VERSION ""

NS_ :

BS_:

BU_: IHU

BO_ 1050 AVM_3: 8 Vector__XXX
 SG_ HPA_Subscribe_Status : 63|3@0+ (1,0) [0|7] ""  IHU
 SG_ HPA_IHU_Audio_HPA_status : 60|1@0+ (1,0) [0|1] ""  IHU
 SG_ FaultStatusCameraDVR : 59|2@0+ (1,0) [0|2] ""  IHU
 SG_ REQ_AVMDisp_1 : 57|2@0+ (1,0) [0|3] ""  IHU
 SG_ PDC_fault_status : 55|1@0+ (1,0) [0|1] ""  IHU
 SG_ APA_fault_status : 54|2@0+ (1,0) [0|3] ""  IHU
 SG_ FAPASet_Feedback : 52|1@0+ (1,0) [0|1] ""  IHU
 SG_ HPASubStsFeedback : 51|1@0+ (1,0) [0|1] ""  IHU
 SG_ UndoSet_Feedback : 49|1@0+ (1,0) [0|1] ""  IHU
 SG_ Undo_fault_status : 48|1@0+ (1,0) [0|1] ""  IHU
 SG_ PDCmute_Set_Feedback : 43|1@0+ (1,0) [0|1] ""  IHU
 SG_ MOD_WorkSts : 42|2@0+ (1,0) [0|3] ""  IHU
 SG_ STAT_BSV_status : 40|1@0+ (1,0) [0|1] ""  IHU
 SG_ HPAMode : 47|3@0+ (1,0) [0|7] ""  IHU
 SG_ HPAActive : 44|1@0+ (1,0) [0|1] ""  IHU
 SG_ HPA_IHU_Audio_Park_Tips_1 : 39|4@0+ (1,0) [0|15] ""  IHU
 SG_ HPA_IHU_Audio_Learn_Tips_1 : 35|4@0+ (1,0) [0|15] ""  IHU
 SG_ HPA_IHU_Audio_Park_Tips : 31|4@0+ (1,0) [0|15] ""  IHU
 SG_ HPA_IHU_Audio_Learn_Tips : 27|4@0+ (1,0) [0|15] ""  IHU
 SG_ HPA_Exam_status : 21|2@0+ (1,0) [0|3] ""  IHU
 SG_ REQ_BSVDisp : 19|2@0+ (1,0) [0|3] ""  IHU
 SG_ MEBSet_Feedback : 8|1@0+ (1,0) [0|1] ""  IHU
 SG_ AVM_FactoryMode : 23|1@0+ (1,0) [0|1] ""  IHU
 SG_ AVMFeedbackSts_RemoteMode : 22|1@0+ (1,0) [0|1] ""  IHU
 SG_ AVM_3_IHUTTSExtend : 15|4@0+ (1,0) [0|15] ""  IHU
 SG_ AVM_3_IHUTTS : 5|5@0+ (1,0) [0|31] ""  IHU
 SG_ AVMDisplaySts : 0|1@0+ (1,0) [0|1] ""  IHU

BO_ 1267 AIPM_2: 8 Vector__XXX
 SG_ AIPM_2_DriveModeSet : 35|2@0+ (1,0) [0|3] ""  IHU

BO_ 1265 AIPM_1: 8 Vector__XXX
 SG_ PanelKeyVoiceRemindReq : 8|1@0+ (1,0) [0|1] ""  IHU

BO_ 704 ABS_ESP_G: 7 Vector__XXX
 SG_ CDPFailSts : 46|1@0+ (1,0) [0|1] ""  IHU
 SG_ AVHFailSts : 45|1@0+ (1,0) [0|1] ""  IHU
 SG_ AVHSts : 44|2@0+ (1,0) [0|3] ""  IHU
 SG_ HDCFailSts : 42|1@0+ (1,0) [0|1] ""  IHU
 SG_ DiagnosticSessionSts : 47|1@0+ (1,0) [0|1] ""  IHU
 SG_ CDPActive : 13|1@0+ (1,0) [0|1] ""  IHU
 SG_ HHCFailSts : 15|1@0+ (1,0) [0|1] ""  IHU
 SG_ VDCActive : 0|1@0+ (1,0) [0|1] ""  IHU
 SG_ TCSActive : 1|1@0+ (1,0) [0|1] ""  IHU
 SG_ VDCFailSts : 2|1@0+ (1,0) [0|1] ""  IHU
 SG_ TCSFailSts : 3|1@0+ (1,0) [0|1] ""  IHU
 SG_ EBDFailSts : 4|1@0+ (1,0) [0|1] ""  IHU
 SG_ ABSFailSts : 5|1@0+ (1,0) [0|1] ""  IHU
 SG_ AVHWarningMessage : 7|1@0+ (1,0) [0|1] ""  IHU
 SG_ ABS_ESP_Checksum : 55|8@0+ (1,0) [0|255] ""  IHU
 SG_ HDCCtrlSts : 41|2@0+ (1,0) [0|3] ""  IHU
 SG_ ABS_ESP_MessageCounter : 35|4@0+ (1,0) [0|15] ""  IHU
 SG_ VehicleSpeedVSOSigValidData : 31|1@0+ (1,0) [0|1] ""  IHU
 SG_ VehicleSpeedVSOSig : 12|13@0+ (0.0625,0) [0|511.875] "km/h"  IHU
 SG_ ESPSwitchStatus : 14|1@0+ (1,0) [0|1] ""  IHU

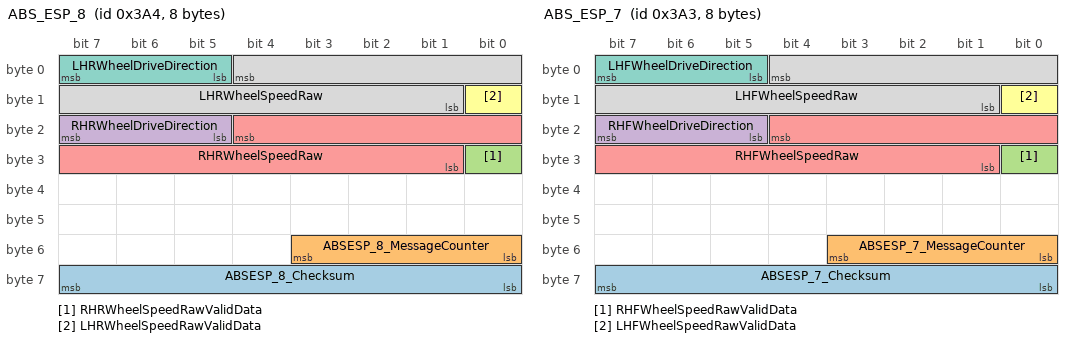
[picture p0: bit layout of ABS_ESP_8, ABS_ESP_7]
BO_ 932 ABS_ESP_8: 8 Vector__XXX
 SG_ ABSESP_8_Checksum : 63|8@0+ (1,0) [0|255] ""  IHU
 SG_ ABSESP_8_MessageCounter : 51|4@0+ (1,0) [0|15] ""  IHU
 SG_ RHRWheelSpeedRawValidData : 24|1@0+ (1,0) [0|1] ""  IHU
 SG_ RHRWheelDriveDirection : 23|3@0+ (1,0) [0|7] ""  IHU
 SG_ RHRWheelSpeedRaw : 20|12@0+ (0.05,-30) [-30|80] "m/s"  IHU
 SG_ LHRWheelSpeedRawValidData : 8|1@0+ (1,0) [0|1] ""  IHU
 SG_ LHRWheelDriveDirection : 7|3@0+ (1,0) [0|7] ""  IHU
 SG_ LHRWheelSpeedRaw : 4|12@0+ (0.05,-30) [-30|80] "m/s"  IHU

BO_ 931 ABS_ESP_7: 8 Vector__XXX
 SG_ ABSESP_7_Checksum : 63|8@0+ (1,0) [0|255] ""  IHU
 SG_ ABSESP_7_MessageCounter : 51|4@0+ (1,0) [0|15] ""  IHU
 SG_ RHFWheelSpeedRawValidData : 24|1@0+ (1,0) [0|1] ""  IHU
 SG_ RHFWheelDriveDirection : 23|3@0+ (1,0) [0|7] ""  IHU
 SG_ RHFWheelSpeedRaw : 20|12@0+ (0.05,-30) [-30|80] "m/s"  IHU
 SG_ LHFWheelSpeedRawValidData : 8|1@0+ (1,0) [0|1] ""  IHU
 SG_ LHFWheelDriveDirection : 7|3@0+ (1,0) [0|7] ""  IHU
 SG_ LHFWheelSpeedRaw : 4|12@0+ (0.05,-30) [-30|80] "m/s"  IHU

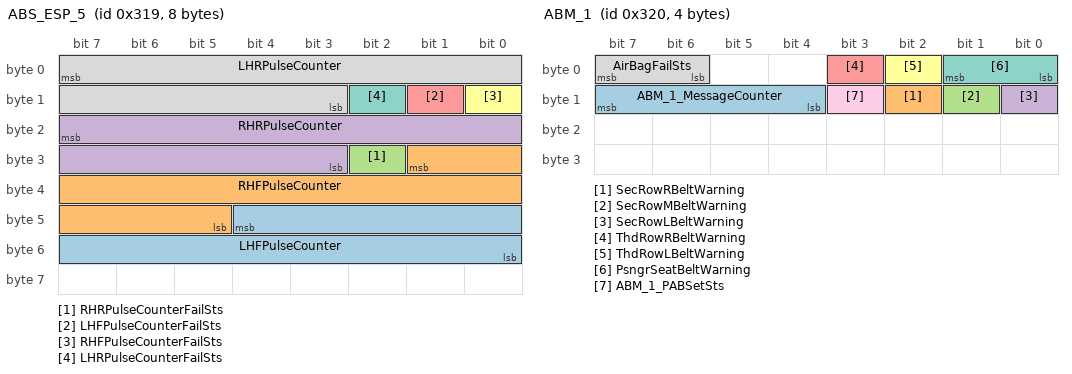
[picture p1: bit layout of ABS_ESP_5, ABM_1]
BO_ 793 ABS_ESP_5: 8 Vector__XXX
 SG_ LHFPulseCounter : 44|13@0+ (1,0) [0|8191] "pulse"  IHU
 SG_ RHFPulseCounter : 25|13@0+ (1,0) [0|8191] "pulse"  IHU
 SG_ RHRPulseCounterFailSts : 26|1@0+ (1,0) [0|1] ""  IHU
 SG_ RHRPulseCounter : 23|13@0+ (1,0) [0|8191] "pulse"  IHU
 SG_ LHFPulseCounterFailSts : 9|1@0+ (1,0) [0|1] ""  IHU
 SG_ RHFPulseCounterFailSts : 8|1@0+ (1,0) [0|1] ""  IHU
 SG_ LHRPulseCounterFailSts : 10|1@0+ (1,0) [0|1] ""  IHU
 SG_ LHRPulseCounter : 7|13@0+ (1,0) [0|8191] "pulse"  IHU

BO_ 787 ABS_ESP_3: 8 Vector__XXX
 SG_ ABS_ESP_3_AVHSts : 53|2@0+ (1,0) [0|3] ""  IHU
 SG_ ABS_ESP_3_AVHFailSts : 39|1@0+ (1,0) [0|1] ""  IHU

BO_ 800 ABM_1: 4 Vector__XXX
 SG_ ABM_1_MessageCounter : 15|4@0+ (1,0) [0|15] "" Vector__XXX
 SG_ SecRowRBeltWarning : 10|1@0+ (1,0) [0|1] "" Vector__XXX
 SG_ SecRowMBeltWarning : 9|1@0+ (1,0) [0|1] ""  IHU
 SG_ SecRowLBeltWarning : 8|1@0+ (1,0) [0|1] "" Vector__XXX
 SG_ ThdRowRBeltWarning : 3|1@0+ (1,0) [0|1] "" Vector__XXX
 SG_ ThdRowLBeltWarning : 2|1@0+ (1,0) [0|1] ""  IHU
 SG_ PsngrSeatBeltWarning : 1|2@0+ (1,0) [0|3] "" Vector__XXX
 SG_ AirBagFailSts : 7|2@0+ (1,0) [0|3] "" Vector__XXX
 SG_ ABM_1_PABSetSts : 11|1@0+ (1,0) [0|1] ""  IHU

BO_ 1338 CGW_TMF: 8 Vector__XXX
 SG_ TMF_SpdAct : 55|16@0+ (1,-32767) [-32767|32766] "rpm"  IHU

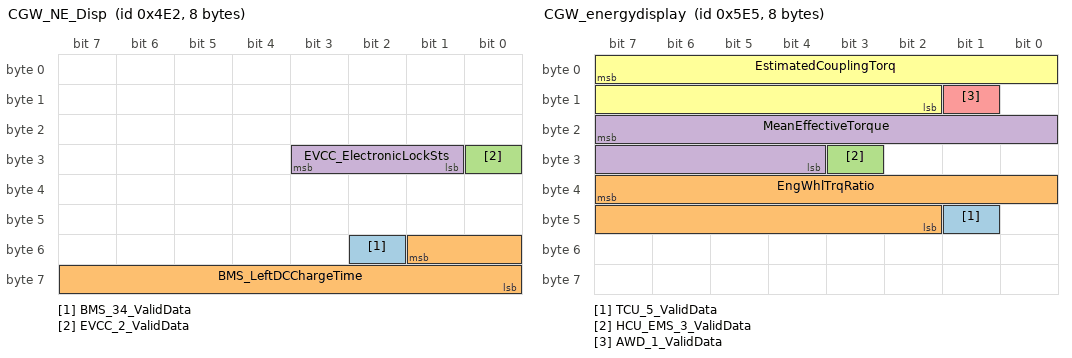
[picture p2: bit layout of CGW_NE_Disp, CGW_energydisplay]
BO_ 1250 CGW_NE_Disp: 8 Vector__XXX
 SG_ BMS_34_ValidData : 50|1@0+ (1,0) [0|1] ""  IHU
 SG_ BMS_LeftDCChargeTime : 49|10@0+ (1,0) [0|1022] "min"  IHU
 SG_ EVCC_2_ValidData : 24|1@0+ (1,0) [0|1] ""  IHU
 SG_ EVCC_ElectronicLockSts : 27|3@0+ (1,0) [0|4] ""  IHU

BO_ 1509 CGW_energydisplay: 8 Vector__XXX
 SG_ TCU_5_ValidData : 41|1@0+ (1,0) [0|1] ""  IHU
 SG_ EngWhlTrqRatio : 39|14@0+ (0.01,0) [0|163.82] ""  IHU
 SG_ HCU_EMS_3_ValidData : 27|1@0+ (1,0) [0|1] ""  IHU
 SG_ MeanEffectiveTorque : 23|12@0+ (0.5,-1000) [-1000|1000] "NM"  IHU
 SG_ AWD_1_ValidData : 9|1@0+ (1,0) [0|1] ""  IHU
 SG_ EstimatedCouplingTorq : 7|14@0+ (0.25,0) [0|3000] "Nm"  IHU

BO_ 1812 DMC_BCM_RLS_RES: 8 Vector__XXX
 SG_ DMC_BCM_RLS_RES : 7|64@0+ (1,0) [0|0] ""  IHU

BO_ 1796 DMC_BCM_RLS_REQ: 8 IHU
 SG_ DMC_BCM_RLS_REQ : 7|64@0+ (1,0) [0|0] "" Vector__XXX

BO_ 1882 TBOX_IHU_RES: 8 IHU
 SG_ TBOX_IHU_RES : 7|64@0+ (1,0) [0|0] "" Vector__XXX

BO_ 1866 TBOX_IHU_REQ: 8 Vector__XXX
 SG_ TBOX_IHU_REQ : 7|64@0+ (1,0) [0|0] ""  IHU

BO_ 1913 DMC_BCM_EBS_RES: 8 Vector__XXX
 SG_ DMC_BCM_EBS_RES : 7|64@0+ (1,0) [0|0] ""  IHU

BO_ 2041 DMC_ACU_RES_EDR: 8 Vector__XXX
 SG_ DMC_ACU_RES_EDR : 7|64@0+ (1,0) [0|0] ""  IHU

BO_ 2030 DMC_DCDC_RES: 8 Vector__XXX
 SG_ DMC_DCDC_RES : 7|64@0+ (1,0) [0|0] ""  IHU

BO_ 2029 DMC_BMS_RES: 8 Vector__XXX
 SG_ DMC_BMS_RES : 7|64@0+ (1,0) [0|0] ""  IHU

BO_ 1813 DMC_EVCC_RES: 8 Vector__XXX
 SG_ DMC_EVCC_RES : 7|64@0+ (1,0) [0|0] ""  IHU

BO_ 1819 DMC_ISGF_RES: 8 Vector__XXX
 SG_ DMC_ISGF_RES : 7|64@0+ (1,0) [0|0] ""  IHU

BO_ 2027 DMC_BSGF_MCUF_RES: 8 Vector__XXX
 SG_ DMC_BSG1_RES : 7|64@0+ (1,0) [0|0] ""  IHU

BO_ 2025 DMC_OBD_RES_TCU: 8 Vector__XXX
 SG_ DMC_OBD_RESP_TCU : 7|64@0+ (1,0) [0|0] ""  IHU

BO_ 2024 DMC_OBD_EMS_RES: 8 Vector__XXX
 SG_ DMC_OBD_EMS_RES : 7|64@0+ (1,0) [0|0] ""  IHU

BO_ 2014 DMC_SHU3L_RES: 8 Vector__XXX
 SG_ DMC_SHU3L_RES : 7|64@0+ (1,0) [0|0] ""  IHU

BO_ 2009 DMC_SHU2R_RES: 8 Vector__XXX
 SG_ DMC_SHU2R_RES : 7|64@0+ (1,0) [0|0] ""  IHU

BO_ 2008 DMC_SHU2M_RES: 8 Vector__XXX
 SG_ DMC_SHU2M_RES : 7|64@0+ (1,0) [0|0] ""  IHU

BO_ 2007 DMC_SHU2L_RES: 8 Vector__XXX
 SG_ DMC_SHU2L_RES : 7|64@0+ (1,0) [0|0] ""  IHU

BO_ 2006 DMC_SHU3R_RES: 8 Vector__XXX
 SG_ DMC_SHU3R_RES : 7|64@0+ (1,0) [0|0] ""  IHU

BO_ 1982 DMC_SRFR_RES: 8 Vector__XXX
 SG_ DMC_SRFR_RES : 7|64@0+ (1,0) [0|0] ""  IHU

BO_ 1981 DMC_SRFG_RES: 8 Vector__XXX
 SG_ DMC_SRFG_RES : 7|64@0+ (1,0) [0|0] ""  IHU

BO_ 1980 DMC_SAUR_RES: 8 Vector__XXX
 SG_ DMC_SAUR_RES : 7|64@0+ (1,0) [0|0] ""  IHU

BO_ 1979 DMC_RRPLM_RES: 8 Vector__XXX
 SG_ DMC_RRPLM_RES : 7|64@0+ (1,0) [0|0] ""  IHU

BO_ 1978 DMC_RRFLM_RES: 8 Vector__XXX
 SG_ DMC_RRFLM_RES : 7|64@0+ (1,0) [0|0] ""  IHU

BO_ 1977 DMC_RLPLM_RES: 8 Vector__XXX
 SG_ DMC_RLPLM_RES : 7|64@0+ (1,0) [0|0] ""  IHU

BO_ 1976 DMC_RLFLM_RES: 8 Vector__XXX
 SG_ DMC_RLFLM_RES : 7|64@0+ (1,0) [0|0] ""  IHU

BO_ 1975 DMC_SAUP_RES: 8 Vector__XXX
 SG_ DMC_SAUP_RES : 7|64@0+ (1,0) [0|0] ""  IHU

BO_ 1974 DMC_SHU1P_RES: 8 Vector__XXX
 SG_ DMC_SHU1P_RES : 7|64@0+ (1,0) [0|0] ""  IHU

BO_ 1951 DMC_SAUD_RES: 8 Vector__XXX
 SG_ DMC_SAUD_RES : 7|64@0+ (1,0) [0|0] ""  IHU

BO_ 1949 DMC_NFC_RES: 8 Vector__XXX
 SG_ DMC_NFC_RES : 7|64@0+ (1,0) [0|0] ""  IHU

BO_ 1946 DMC_AIPMR_RES: 8 Vector__XXX
 SG_ DMC__AIPMR_RES : 7|64@0+ (1,0) [0|0] ""  IHU

BO_ 1945 DMC_AIPM_RES: 8 Vector__XXX
 SG_ DMC__AIPM_RES : 7|64@0+ (1,0) [0|0] ""  IHU

BO_ 1938 DMC_SHU1D_RES: 8 Vector__XXX
 SG_ DMC_SHU1D_RES : 7|64@0+ (1,0) [0|0] ""  IHU

BO_ 1936 DMC_SCU_RES: 8 Vector__XXX
 SG_ DMC_SCU_RES : 7|64@0+ (1,0) [0|0] ""  IHU

BO_ 1919 DMC_RHM_RES: 8 Vector__XXX
 SG_ DMC_RHM_RES : 7|64@0+ (1,0) [0|0] ""  IHU

BO_ 1918 DMC_LHM_RES: 8 Vector__XXX
 SG_ DMC_LHM_RES : 7|64@0+ (1,0) [0|0] ""  IHU

BO_ 1917 DMC_ESCL_RES: 8 Vector__XXX
 SG_ DMC_ESCL_RES : 7|64@0+ (1,0) [0|0] ""  IHU

BO_ 1916 DMC_PLG_RES: 8 Vector__XXX
 SG_ DMC_PLG_RES : 7|64@0+ (1,0) [0|0] ""  IHU

BO_ 1910 DMC_AVM_RES: 8 Vector__XXX
 SG_ DMC_AVM_RES : 7|64@0+ (1,0) [0|0] ""  IHU

BO_ 1907 DMC_RADAR_RES: 8 Vector__XXX
 SG_ DMC_RADAR_RES : 7|64@0+ (1,0) [0|0] ""  IHU

BO_ 1906 DMC_CGW_RES: 8 Vector__XXX
 SG_ DMC_CGW_RES : 7|64@0+ (1,0) [0|0] ""  IHU

BO_ 1904 DMC_BDM_RES: 8 Vector__XXX
 SG_ DMC_BDM_RES : 7|64@0+ (1,0) [0|0] ""  IHU

BO_ 1885 DMC_IMMO_RES: 8 Vector__XXX
 SG_ DMC_IMMO_RES : 7|64@0+ (1,0) [0|0] ""  IHU

BO_ 1883 DMC_CLM_RES: 8 Vector__XXX
 SG_ DMC_CLM_RES : 7|64@0+ (1,0) [0|0] ""  IHU

BO_ 1880 DMC_DBL_RES: 8 Vector__XXX
 SG_ DMC_DBL_RES : 7|64@0+ (1,0) [0|0] ""  IHU

BO_ 1879 DMC_ICM_RES: 8 Vector__XXX
 SG_ DMC_ICM_RES : 7|64@0+ (1,0) [0|0] ""  IHU

BO_ 1878 DMC_ACU_RES: 8 Vector__XXX
 SG_ DMC_ACU_RES : 7|64@0+ (1,0) [0|0] ""  IHU

BO_ 1855 DMC_FRM_RES: 8 Vector__XXX
 SG_ DMC_FRM_RES : 7|64@0+ (1,0) [0|0] ""  IHU

BO_ 1854 DMC_FCM_RES: 8 Vector__XXX
 SG_ DMC_FCM_RES : 7|64@0+ (1,0) [0|0] ""  IHU

BO_ 1851 DMC_EGS_RES: 8 Vector__XXX
 SG_ DMC_EGS_RES : 7|64@0+ (1,0) [0|0] ""  IHU

BO_ 1848 DMC_TPMS_RES: 8 Vector__XXX
 SG_ DMC_TPMS_RES : 7|64@0+ (1,0) [0|0] ""  IHU

BO_ 1844 DMC_EPS_RES: 8 Vector__XXX
 SG_ DMC_EPS_RES : 7|64@0+ (1,0) [0|0] ""  IHU

BO_ 1840 DMC_ESP_RES: 8 Vector__XXX
 SG_ DMC_ESP_RES : 7|64@0+ (1,0) [0|0] ""  IHU

BO_ 1816 DIAG_EPB_RES_CH: 8 Vector__XXX
 SG_ DIAG_EPB_RES : 7|64@0+ (1,0) [0|0] ""  IHU

BO_ 1841 DIAG_EPB_RES_PT: 8 Vector__XXX
 SG_ DIAG_EPB_RES : 7|64@0+ (1,0) [0|0] ""  IHU

BO_ 1823 DMC_GSI_RES: 8 Vector__XXX
 SG_ DMC_GSI_RES : 7|64@0+ (1,0) [0|0] ""  IHU

BO_ 1811 DMC_TCU_RES: 8 Vector__XXX
 SG_ DMC_TCU_RES : 7|64@0+ (1,0) [0|0] ""  IHU

BO_ 1810 DMC_AWD_RES: 8 Vector__XXX
 SG_ DMC_AWD_RES : 7|64@0+ (1,0) [0|0] ""  IHU

BO_ 1809 DMC_FPC_RES: 8 Vector__XXX
 SG_ DMC_FPC_RES : 7|64@0+ (1,0) [0|0] ""  IHU

BO_ 1808 DMC_EMS_RES: 8 Vector__XXX
 SG_ DMC_EMS_RES : 7|64@0+ (1,0) [0|0] ""  IHU

BO_ 2005 DMC_CVBOX_RES: 8 Vector__XXX
 SG_ DMC_CVBOX_RES : 7|64@0+ (1,0) [0|0] ""  IHU

BO_ 1948 DMC_HUD_RES: 8 Vector__XXX
 SG_ DMC_HUD_RES : 7|64@0+ (1,0) [0|0] ""  IHU

BO_ 1874 DMC_DCM_RES: 8 Vector__XXX
 SG_ DMC_DCM_RES : 7|64@0+ (1,0) [0|0] ""  IHU

BO_ 1843 DMC_PPMI_RES: 8 Vector__XXX
 SG_ DMC_PPMI_RES : 7|64@0+ (1,0) [0|0] ""  IHU

BO_ 1905 DMC_SAM_RES: 8 Vector__XXX
 SG_ DMC_SAM_RES : 7|64@0+ (1,0) [0|0] ""  IHU

BO_ 2028 DMC_MCUR_RES: 8 Vector__XXX
 SG_ DMC_MCUR_RES : 7|64@0+ (1,0) [0|0] ""  IHU

BO_ 2026 DMC_HCU_RES: 8 Vector__XXX
 SG_ DMC_HCU_RES : 7|64@0+ (1,0) [0|0] ""  IHU

BO_ 1847 DMC_ASU_RES: 8 Vector__XXX
 SG_ DMC_ASU_RES : 7|64@0+ (1,0) [0|0] ""  IHU

BO_ 2004 DMC_RRCR_RES: 8 Vector__XXX
 SG_ DMC_RRCR_RES : 7|64@0+ (1,0) [0|0] ""  IHU

BO_ 2003 DMC_RLCR_RES: 8 Vector__XXX
 SG_ DMC_RLCR_RES : 7|64@0+ (1,0) [0|0] ""  IHU

BO_ 2002 DMC_FRCR_RES: 8 Vector__XXX
 SG_ DMC_FRCR_RES : 7|64@0+ (1,0) [0|0] ""  IHU

BO_ 2001 DMC_FLCR_RES: 8 Vector__XXX
 SG_ DMC_FLCR_RES : 7|64@0+ (1,0) [0|0] ""  IHU

BO_ 2000 DMC_IDCU_RES: 8 Vector__XXX
 SG_ DMC_IDCU_RES : 7|64@0+ (1,0) [0|0] ""  IHU

BO_ 1983 DMC_CIR_RES: 8 Vector__XXX
 SG_ DMC_CIR_RES : 7|64@0+ (1,0) [0|0] ""  IHU

BO_ 1897 DMC_BCM_EBS_REQ: 8 IHU
 SG_ DMC_BCM_EBS_REQ : 7|64@0+ (1,0) [0|0] "" Vector__XXX

BO_ 1999 DMC_REQ_Broadcast: 8 IHU
 SG_ DMC_REQ_Broadcast : 7|64@0+ (1,0) [0|0] "" Vector__XXX

BO_ 2033 DMC_ACU_REQ_EDR: 8 IHU
 SG_ DMC_ACU_REQ_EDR : 7|64@0+ (1,0) [0|0] "" Vector__XXX

BO_ 1797 DMC_EVCC_REQ: 8 IHU
 SG_ DMC_OBD_REQ_EVCC : 7|64@0+ (1,0) [0|0] "" Vector__XXX

BO_ 1803 DMC_ISGF_REQ: 8 IHU
 SG_ DMC_ISGF_REQ : 7|64@0+ (1,0) [0|0] "" Vector__XXX

BO_ 2019 DMC_BSGF_MCUF_REQ: 8 IHU
 SG_ DMC_BSG1_REQ : 7|64@0+ (1,0) [0|0] "" Vector__XXX

BO_ 2017 DMC_OBD_REQ_TCU: 8 IHU
 SG_ DMC_OBD_REQ_TCU : 7|64@0+ (1,0) [0|0] "" Vector__XXX

BO_ 2016 DMC_OBD_EMS_REQ: 8 IHU
 SG_ DMC_OBD_EMS_REQ : 7|64@0+ (1,0) [0|0] "" Vector__XXX

BO_ 1998 DMC_SHU3L_REQ: 8 IHU
 SG_ DMC_SHU3L_REQ : 7|64@0+ (1,0) [0|0] "" Vector__XXX

BO_ 1993 DMC_SHU2R_REQ: 8 IHU
 SG_ DMC_SHU2R_REQ : 7|64@0+ (1,0) [0|0] "" Vector__XXX

BO_ 1992 DMC_SHU2M_REQ: 8 IHU
 SG_ DMC_SHU2M_REQ : 7|64@0+ (1,0) [0|0] "" Vector__XXX

BO_ 1991 DMC_SHU2L_REQ: 8 IHU
 SG_ DMC_SHU2L_REQ : 7|64@0+ (1,0) [0|0] "" Vector__XXX

BO_ 1990 DMC_SHU3R_REQ: 8 IHU
 SG_ DMC_SHU3R_REQ : 7|64@0+ (1,0) [0|0] "" Vector__XXX

BO_ 1966 DMC_SRFR_REQ: 8 IHU
 SG_ DMC_SRFR_REQ : 7|64@0+ (1,0) [0|0] "" Vector__XXX

BO_ 1965 DMC_SRFG_REQ: 8 IHU
 SG_ DMC_SRFG_REQ : 7|64@0+ (1,0) [0|0] "" Vector__XXX

BO_ 1964 DMC_SAUR_REQ: 8 IHU
 SG_ DMC_SAUR_REQ : 7|64@0+ (1,0) [0|0] "" Vector__XXX

BO_ 1963 DMC_RRPLM_REQ: 8 IHU
 SG_ DMC_RRPLM_REQ : 7|64@0+ (1,0) [0|0] "" Vector__XXX

BO_ 1962 DMC_RRFLM_REQ: 8 IHU
 SG_ DMC_RRFLM_REQ : 7|64@0+ (1,0) [0|0] "" Vector__XXX

BO_ 1961 DMC_RLPLM_REQ: 8 IHU
 SG_ DMC_RLPLM_REQ : 7|64@0+ (1,0) [0|0] "" Vector__XXX

BO_ 1960 DMC_RLFLM_REQ: 8 IHU
 SG_ DMC_RLFLM_REQ : 7|64@0+ (1,0) [0|0] "" Vector__XXX

BO_ 1959 DMC_SAUP_REQ: 8 IHU
 SG_ DMC_SAUP_REQ : 7|64@0+ (1,0) [0|0] "" Vector__XXX

BO_ 1958 DMC_SHU1P_REQ: 8 IHU
 SG_ DMC_SHU1P_REQ : 7|64@0+ (1,0) [0|0] "" Vector__XXX

BO_ 1943 DMC_EAMP_RES: 8 Vector__XXX
 SG_ DMC_EAMP_RES : 7|64@0+ (1,0) [0|0] ""  IHU

BO_ 1942 DMC_ACP_RES: 8 Vector__XXX
 SG_ DMC__ACP_RES : 7|64@0+ (1,0) [0|0] ""  IHU

BO_ 1941 DMC_DVR_RES: 8 Vector__XXX
 SG_ DMC_DVR_RES : 7|64@0+ (1,0) [0|0] ""  IHU

BO_ 1939 DMC_CWC_RES: 8 Vector__XXX
 SG_ DMC_CWC_RES : 7|64@0+ (1,0) [0|0] ""  IHU

BO_ 1935 DMC_SAUD_REQ: 8 IHU
 SG_ DMC_SAUD_REQ : 7|64@0+ (1,0) [0|0] "" Vector__XXX

BO_ 1933 DMC_NFC_REQ: 8 IHU
 SG_ DMC_NFC_REQ : 7|64@0+ (1,0) [0|0] "" Vector__XXX

BO_ 1930 DMC_AIPMR_REQ: 8 IHU
 SG_ DMC_AIPMR_REQ : 7|64@0+ (1,0) [0|0] "" Vector__XXX

BO_ 1929 DMC_AIPM_REQ: 8 IHU
 SG_ DMC_AIPM_REQ : 7|64@0+ (1,0) [0|0] "" Vector__XXX

BO_ 1927 DMC_EAMP_REQ: 8 IHU
 SG_ DMC_EAMP_REQ : 7|64@0+ (1,0) [0|0] "" Vector__XXX

BO_ 1926 DMC_ACP_REQ: 8 IHU
 SG_ DMC__ACP_REQ : 7|64@0+ (1,0) [0|0] "" Vector__XXX

BO_ 1925 DMC_DVR_REQ: 8 IHU
 SG_ DMC_DVR_REQ : 7|64@0+ (1,0) [0|0] "" Vector__XXX

BO_ 1923 DMC_CWC_REQ: 8 IHU
 SG_ DMC_CWC_REQ : 7|64@0+ (1,0) [0|0] "" Vector__XXX

BO_ 1922 DMC_SHU1D_REQ: 8 IHU
 SG_ DMC_SHU1D_REQ : 7|64@0+ (1,0) [0|0] "" Vector__XXX

BO_ 1920 DMC_SCU_REQ: 8 IHU
 SG_ DMC_SCU_REQ : 7|64@0+ (1,0) [0|0] "" Vector__XXX

BO_ 1903 DMC_RHM_REQ: 8 IHU
 SG_ DMC_RHM_REQ : 7|64@0+ (1,0) [0|0] "" Vector__XXX

BO_ 1902 DMC_LHM_REQ: 8 IHU
 SG_ DMC_LHM_REQ : 7|64@0+ (1,0) [0|0] "" Vector__XXX

BO_ 1901 DMC_ESCL_REQ: 8 IHU
 SG_ DMC_ESCL_REQ : 7|64@0+ (1,0) [0|0] "" Vector__XXX

BO_ 1900 DMC_PLG_REQ: 8 IHU
 SG_ DMC_PLG_REQ : 7|64@0+ (1,0) [0|0] "" Vector__XXX

BO_ 1894 DMC_AVM_REQ: 8 IHU
 SG_ DMC_AVM_REQ : 7|64@0+ (1,0) [0|0] "" Vector__XXX

BO_ 1891 DMC_RADAR_REQ: 8 IHU
 SG_ DMC_RADAR_REQ : 7|64@0+ (1,0) [0|0] "" Vector__XXX

BO_ 1890 DMC_CGW_REQ: 8 IHU
 SG_ DMC_CGW_REQ : 7|64@0+ (1,0) [0|0] "" Vector__XXX

BO_ 1888 DMC_BDM_REQ: 8 IHU
 SG_ DMC_BDM_REQ : 7|64@0+ (1,0) [0|0] "" Vector__XXX

BO_ 1869 DMC_IMMO_REQ: 8 IHU
 SG_ DMC_IMMO_REQ : 7|64@0+ (1,0) [0|0] "" Vector__XXX

BO_ 1867 DMC_CLM_REQ: 8 IHU
 SG_ DMC_CLM_REQ : 7|64@0+ (1,0) [0|0] "" Vector__XXX

BO_ 1864 DMC_DBL_REQ: 8 IHU
 SG_ DMC_DBL_REQ : 7|64@0+ (1,0) [0|0] "" Vector__XXX

BO_ 1863 DMC_ICM_REQ: 8 IHU
 SG_ DMC_ICM_REQ : 7|64@0+ (1,0) [0|0] "" Vector__XXX

BO_ 1862 DMC_ACU_REQ: 8 IHU
 SG_ DMC_ACU_REQ : 7|64@0+ (1,0) [0|0] "" Vector__XXX

BO_ 1839 DMC_FRM_REQ: 8 IHU
 SG_ DMC_FRM_REQ : 7|64@0+ (1,0) [0|0] "" Vector__XXX

BO_ 1838 DMC_FCM_REQ: 8 IHU
 SG_ DMC_FCM_REQ : 7|64@0+ (1,0) [0|0] "" Vector__XXX

BO_ 1835 DMC_EGS_REQ: 8 IHU
 SG_ DMC_EGS_REQ : 7|64@0+ (1,0) [0|0] "" Vector__XXX

BO_ 1832 DMC_TPMS_REQ: 8 IHU
 SG_ DMC_TPMS_REQ : 7|64@0+ (1,0) [0|0] "" Vector__XXX

BO_ 1828 DMC_EPS_REQ: 8 IHU
 SG_ DMC_EPS_REQ : 7|64@0+ (1,0) [0|0] "" Vector__XXX

BO_ 1824 DMC_ESP_REQ: 8 IHU
 SG_ DMC_ESP_REQ : 7|64@0+ (1,0) [0|0] "" Vector__XXX

BO_ 1800 DIAG_EPB_REQ_CH: 8 IHU
 SG_ DIAG_EPB_REQ : 7|64@0+ (1,0) [0|0] "" Vector__XXX

BO_ 1825 DIAG_EPB_REQ_PT: 8 IHU
 SG_ DIAG_EPB_REQ : 7|64@0+ (1,0) [0|0] "" Vector__XXX

BO_ 1807 DMC_GSI_REQ: 8 IHU
 SG_ DMC_GSI_REQ : 7|64@0+ (1,0) [0|0] "" Vector__XXX

BO_ 1795 DMC_TCU_REQ: 8 IHU
 SG_ DMC_TCU_REQ : 7|64@0+ (1,0) [0|0] "" Vector__XXX

BO_ 1794 DMC_AWD_REQ: 8 IHU
 SG_ DMC_AWD_REQ : 7|64@0+ (1,0) [0|0] "" Vector__XXX

BO_ 1793 DMC_FPC_REQ: 8 IHU
 SG_ DMC_FPC_REQ : 7|64@0+ (1,0) [0|0] "" Vector__XXX

BO_ 1792 DMC_EMS_REQ: 8 IHU
 SG_ DMC_EMS_REQ : 7|64@0+ (1,0) [0|0] "" Vector__XXX

BO_ 1989 DMC_CVBOX_REQ: 8 IHU
 SG_ DMC_CVBOX_REQ : 7|64@0+ (1,0) [0|0] "" Vector__XXX

BO_ 1932 DMC_HUD_REQ: 8 IHU
 SG_ DMC_HUD_REQ : 7|64@0+ (1,0) [0|0] "" Vector__XXX

BO_ 1858 DMC_DCM_REQ: 8 IHU
 SG_ DMC_DCM_REQ : 7|64@0+ (1,0) [0|0] "" Vector__XXX

BO_ 1827 DMC_PPMI_REQ: 8 IHU
 SG_ DMC_PPMI_REQ : 7|64@0+ (1,0) [0|0] "" Vector__XXX

BO_ 1889 DMC_SAM_REQ: 8 IHU
 SG_ DMC_SAM_REQ : 7|64@0+ (1,0) [0|0] "" Vector__XXX

BO_ 2020 DMC_MCUR_REQ: 8 IHU
 SG_ DMC_MCUR_REQ : 7|64@0+ (1,0) [0|0] "" Vector__XXX

BO_ 2022 DMC_DCDC_REQ: 8 IHU
 SG_ DMC_DCDC_REQ : 7|64@0+ (1,0) [0|0] "" Vector__XXX

BO_ 2021 DMC_BMS_REQ: 8 IHU
 SG_ DMC_BMS_REQ : 7|64@0+ (1,0) [0|0] "" Vector__XXX

BO_ 2018 DMC_HCU_REQ: 8 IHU
 SG_ DMC_HCU_REQ : 7|64@0+ (1,0) [0|0] "" Vector__XXX

BO_ 1831 DMC_ASU_REQ: 8 IHU
 SG_ DMC_ASU_REQ : 7|64@0+ (1,0) [0|0] "" Vector__XXX

BO_ 1988 DMC_RRCR_REQ: 8 IHU
 SG_ DMC_RRCR_REQ : 7|64@0+ (1,0) [0|0] "" Vector__XXX

BO_ 1987 DMC_RLCR_REQ: 8 IHU
 SG_ DMC_RLCR_REQ : 7|64@0+ (1,0) [0|0] "" Vector__XXX

BO_ 1986 DMC_FRCR_REQ: 8 IHU
 SG_ DMC_FRCR_REQ : 7|64@0+ (1,0) [0|0] "" Vector__XXX

BO_ 1985 DMC_FLCR_REQ: 8 IHU
 SG_ DMC_FLCR_REQ : 7|64@0+ (1,0) [0|0] "" Vector__XXX

BO_ 1984 DMC_IDCU_REQ: 8 IHU
 SG_ DMC_IDCU_REQ : 7|64@0+ (1,0) [0|0] "" Vector__XXX

BO_ 1967 DMC_CIR_REQ: 8 IHU
 SG_ DMC_CIR_REQ : 7|64@0+ (1,0) [0|0] "" Vector__XXX

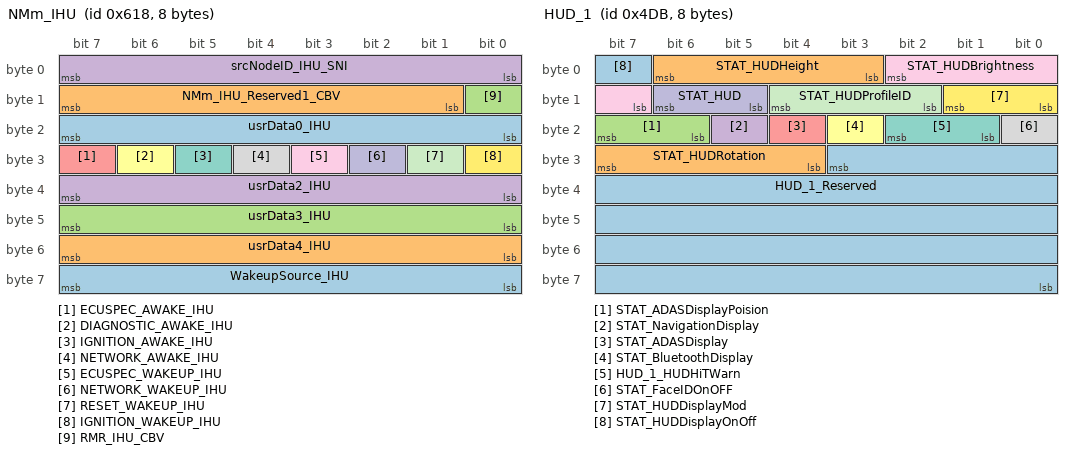
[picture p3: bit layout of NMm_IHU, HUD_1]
BO_ 1560 NMm_IHU: 8 IHU
 SG_ WakeupSource_IHU : 63|8@0+ (1,0) [0|255] "" Vector__XXX
 SG_ usrData4_IHU : 55|8@0+ (1,0) [0|255] "" Vector__XXX
 SG_ usrData3_IHU : 47|8@0+ (1,0) [0|255] "" Vector__XXX
 SG_ usrData2_IHU : 39|8@0+ (1,0) [0|255] "" Vector__XXX
 SG_ ECUSPEC_AWAKE_IHU : 31|1@0+ (1,0) [0|1] "" Vector__XXX
 SG_ DIAGNOSTIC_AWAKE_IHU : 30|1@0+ (1,0) [0|1] "" Vector__XXX
 SG_ IGNITION_AWAKE_IHU : 29|1@0+ (1,0) [0|1] "" Vector__XXX
 SG_ NETWORK_AWAKE_IHU : 28|1@0+ (1,0) [0|1] "" Vector__XXX
 SG_ ECUSPEC_WAKEUP_IHU : 27|1@0+ (1,0) [0|1] "" Vector__XXX
 SG_ NETWORK_WAKEUP_IHU : 26|1@0+ (1,0) [0|1] "" Vector__XXX
 SG_ RESET_WAKEUP_IHU : 25|1@0+ (1,0) [0|1] "" Vector__XXX
 SG_ IGNITION_WAKEUP_IHU : 24|1@0+ (1,0) [0|1] "" Vector__XXX
 SG_ usrData0_IHU : 23|8@0+ (1,0) [0|255] "" Vector__XXX
 SG_ NMm_IHU_Reserved1_CBV : 15|7@0+ (1,0) [0|127] "" Vector__XXX
 SG_ RMR_IHU_CBV : 8|1@0+ (1,0) [0|1] "" Vector__XXX
 SG_ srcNodeID_IHU_SNI : 7|8@0+ (1,0) [0|255] "" Vector__XXX

BO_ 1266 TBOX_2: 8 Vector__XXX
 SG_ TBOX_SetAVMVeiw : 34|3@0+ (1,0) [0|7] ""  IHU
 SG_ TBOX_SetAVMOnReq : 36|2@0+ (1,0) [0|3] ""  IHU

BO_ 1312 TBOX_1: 4 Vector__XXX
 SG_ TBOX_1_RemDiagSts : 23|2@0+ (1,0) [0|3] ""  IHU

BO_ 1243 HUD_1: 8 Vector__XXX
 SG_ HUD_1_Reserved : 27|36@0+ (1,0) [0|0] ""  IHU
 SG_ STAT_HUDRotation : 31|4@0+ (1,0) [0|15] ""  IHU
 SG_ STAT_ADASDisplayPoision : 23|2@0+ (1,0) [0|3] ""  IHU
 SG_ STAT_NavigationDisplay : 21|1@0+ (1,0) [0|1] ""  IHU
 SG_ STAT_ADASDisplay : 20|1@0+ (1,0) [0|1] ""  IHU
 SG_ STAT_BluetoothDisplay : 19|1@0+ (1,0) [0|1] ""  IHU
 SG_ HUD_1_HUDHiTWarn : 18|2@0+ (1,0) [0|3] ""  IHU
 SG_ STAT_FaceIDOnOFF : 16|1@0+ (1,0) [0|1] ""  IHU
 SG_ STAT_HUDBrightness : 2|4@0+ (1,0) [0|15] ""  IHU
 SG_ STAT_HUD : 14|2@0+ (1,0) [0|3] ""  IHU
 SG_ STAT_HUDProfileID : 12|3@0+ (1,0) [0|7] ""  IHU
 SG_ STAT_HUDDisplayMod : 9|2@0+ (1,0) [0|3] ""  IHU
 SG_ STAT_HUDDisplayOnOff : 7|1@0+ (1,0) [0|1] ""  IHU
 SG_ STAT_HUDHeight : 6|4@0+ (1,0) [0|15] ""  IHU

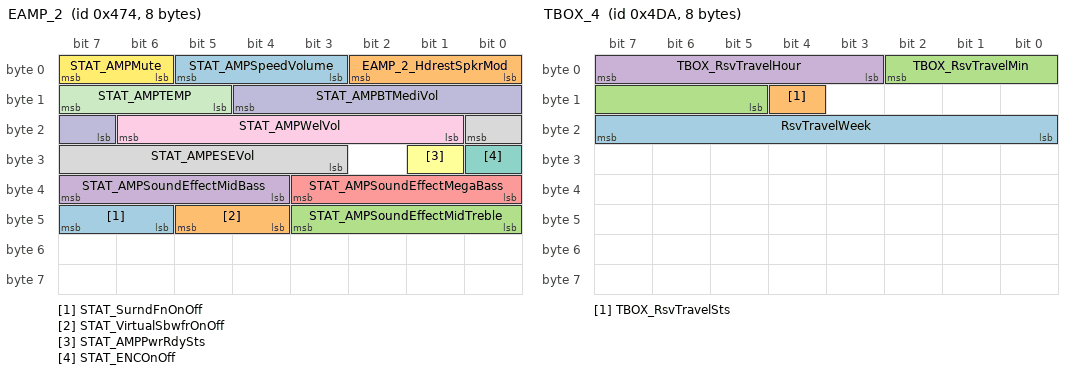
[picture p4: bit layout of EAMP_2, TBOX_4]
BO_ 1140 EAMP_2: 8 Vector__XXX
 SG_ STAT_SurndFnOnOff : 47|2@0+ (1,0) [0|3] ""  IHU
 SG_ STAT_VirtualSbwfrOnOff : 45|2@0+ (1,0) [0|3] ""  IHU
 SG_ STAT_AMPSoundEffectMidTreble : 43|4@0+ (1,0) [0|15] ""  IHU
 SG_ STAT_AMPSoundEffectMidBass : 39|4@0+ (1,0) [0|15] ""  IHU
 SG_ STAT_AMPSoundEffectMegaBass : 35|4@0+ (1,0) [0|15] ""  IHU
 SG_ STAT_AMPPwrRdySts : 25|1@0+ (1,0) [0|1] ""  IHU
 SG_ STAT_ENCOnOff : 24|1@0+ (1,0) [0|1] ""  IHU
 SG_ STAT_AMPESEVol : 16|6@0+ (1,0) [0|63] ""  IHU
 SG_ STAT_AMPWelVol : 22|6@0+ (1,0) [0|63] ""  IHU
 SG_ STAT_AMPBTMediVol : 12|6@0+ (1,0) [0|63] ""  IHU
 SG_ STAT_AMPTEMP : 15|3@0+ (1,0) [0|7] ""  IHU
 SG_ STAT_AMPMute : 7|2@0+ (1,0) [0|3] ""  IHU
 SG_ STAT_AMPSpeedVolume : 5|3@0+ (1,0) [0|7] ""  IHU
 SG_ EAMP_2_HdrestSpkrMod : 2|3@0+ (1,0) [0|7] ""  IHU

BO_ 1121 EAMP_1: 8 Vector__XXX
 SG_ STAT_AMPAlarmVolume : 63|4@0+ (1,0) [1|15] ""  IHU
 SG_ STAT_AMPLoudness : 59|2@0+ (1,0) [0|3] ""  IHU
 SG_ STAT_AMPLiveAcoustics : 57|2@0+ (1,0) [0|3] ""  IHU
 SG_ STAT_AMPSoundFieldFader : 55|4@0+ (1,0) [0|15] ""  IHU
 SG_ STAT_AMPSoundFieldBalance : 51|4@0+ (1,0) [0|15] ""  IHU
 SG_ STAT_AMPSoundEffectTreble : 47|4@0+ (1,0) [0|15] ""  IHU
 SG_ STAT_AMPSoundEffectMidrange : 43|4@0+ (1,0) [0|15] ""  IHU
 SG_ STAT_AMPSoundEffectBass : 39|4@0+ (1,0) [0|15] ""  IHU
 SG_ STAT_AMPSoundEffect : 35|4@0+ (1,0) [0|15] ""  IHU
 SG_ STAT_AMPRestoreDefaults : 31|2@0+ (1,0) [0|3] ""  IHU
 SG_ STAT_AMPDefaultVolume : 29|6@0+ (1,0) [0|63] ""  IHU
 SG_ STAT_AMPSoundFocus : 23|3@0+ (1,0) [0|15] ""  IHU
 SG_ STAT_AMPPhoneVolume : 20|5@0+ (1,0) [0|31] ""  IHU
 SG_ STAT_AMPMediaVolume : 15|6@0+ (1,0) [0|63] ""  IHU
 SG_ STAT_AMPKeyTone : 9|2@0+ (1,0) [0|3] ""  IHU
 SG_ STAT_AMPVRVolume : 7|4@0+ (1,0) [0|15] ""  IHU
 SG_ STAT_AMPNaviVolume : 3|4@0+ (1,0) [0|15] ""  IHU

BO_ 1517 HUD_IHU_Interaction: 8 Vector__XXX
 SG_ HUD_IHU_Interaction : 7|64@0+ (1,0) [0|0] ""  IHU

BO_ 1515 IHU_HUD_Interaction: 8 IHU
 SG_ IHU_HUD_Interaction : 7|64@0+ (1,0) [0|0] "" Vector__XXX

BO_ 1298 IHU_CVBOX_Interaction: 8 IHU
 SG_ IHU_CVBOX_Interaction : 7|64@0+ (1,0) [0|0] "" Vector__XXX

BO_ 1289 CVBOX_IHU_Interaction: 8 Vector__XXX
 SG_ CVBOX_IHU_Interaction : 7|64@0+ (1,0) [0|0] ""  IHU

BO_ 759 DVR_TIHU_Interaction: 8 Vector__XXX
 SG_ DVR_TIHU_Interaction : 7|64@0+ (1,0) [0|0] ""  IHU

BO_ 755 TIHU_DVR_Interaction: 8 IHU
 SG_ IHU_DVR_Interaction : 7|64@0+ (1,0) [0|0] "" Vector__XXX

BO_ 1151 TIHU_IMMO_12: 8 IHU
 SG_ TIHU_Teach_IMMO : 7|64@0+ (1,0) [0|0] "" Vector__XXX

BO_ 1116 TIHU_IMMO_11: 8 IHU
 SG_ TIHU_Auth : 7|64@0+ (1,0) [0|0] "" Vector__XXX

BO_ 1242 TBOX_4: 8 Vector__XXX
 SG_ RsvTravelWeek : 23|8@0+ (1,0) [0|255] ""  IHU
 SG_ TBOX_RsvTravelSts : 12|1@0+ (1,0) [0|1] ""  IHU
 SG_ TBOX_RsvTravelMin : 2|6@0+ (1,0) [0|63] "min"  IHU
 SG_ TBOX_RsvTravelHour : 7|5@0+ (1,0) [0|31] "h"  IHU

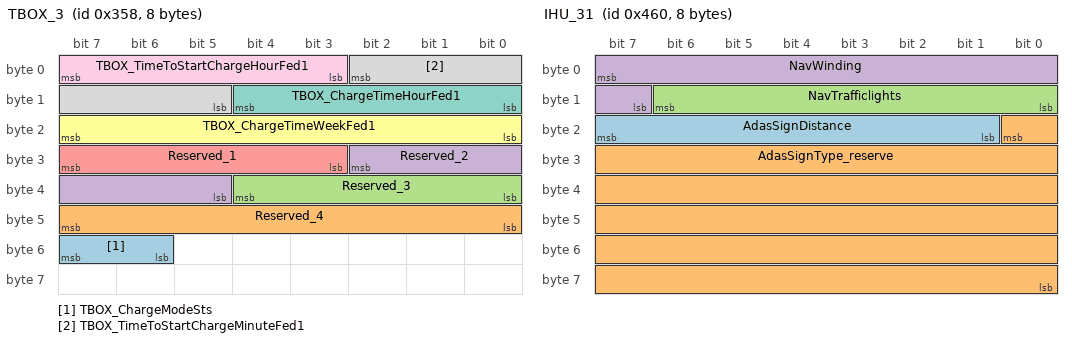
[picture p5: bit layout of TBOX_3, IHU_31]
BO_ 856 TBOX_3: 8 Vector__XXX
 SG_ TBOX_ChargeModeSts : 55|2@0+ (1,0) [0|3] ""  IHU
 SG_ Reserved_4 : 47|8@0+ (1,0) [0|0] ""  IHU
 SG_ Reserved_3 : 36|5@0+ (1,0) [0|0] ""  IHU
 SG_ Reserved_2 : 26|6@0+ (1,0) [0|0] ""  IHU
 SG_ Reserved_1 : 31|5@0+ (1,0) [0|0] ""  IHU
 SG_ TBOX_ChargeTimeWeekFed1 : 23|8@0+ (1,0) [0|255] ""  IHU
 SG_ TBOX_ChargeTimeHourFed1 : 12|5@0+ (1,0) [0|31] "h"  IHU
 SG_ TBOX_TimeToStartChargeMinuteFed1 : 2|6@0+ (1,0) [0|63] "min"  IHU
 SG_ TBOX_TimeToStartChargeHourFed1 : 7|5@0+ (1,0) [0|31] "h"  IHU

BO_ 1150 IHU_32: 8 IHU
 SG_ IHU_32_CRC : 63|8@0+ (1,0) [0|255] "" Vector__XXX
 SG_ IHU_32_MessageCounter : 51|4@0+ (1,0) [0|15] "" Vector__XXX
 SG_ IHU_32_Reserved3 : 55|4@0+ (1,0) [0|0] "" Vector__XXX
 SG_ IHU_32_Reserved2 : 47|4@0+ (1,0) [0|0] "" Vector__XXX
 SG_ APASoftKeyRequest : 43|2@0+ (1,0) [0|3] "" Vector__XXX
 SG_ SET_BSV_Enable : 41|2@0+ (1,0) [0|3] "" Vector__XXX
 SG_ IHU_CurrentThemeMode : 39|2@0+ (1,0) [0|2] "" Vector__XXX
 SG_ IHU_CurrentTheme : 37|2@0+ (1,0) [0|2] "" Vector__XXX
 SG_ HPA_Voice_Confirmed : 35|1@0+ (1,0) [0|1] "" Vector__XXX
 SG_ HPA_Voice_FuctionSwitch : 34|1@0+ (1,0) [0|1] "" Vector__XXX
 SG_ MOD_Setting : 33|2@0+ (1,0) [0|3] "" Vector__XXX
 SG_ PDCmute_Setting : 23|2@0+ (1,0) [0|3] "" Vector__XXX
 SG_ AVMSoftKeyRequest : 21|2@0+ (1,0) [0|3] "" Vector__XXX
 SG_ ADAS_tollstation_Dis : 17|10@0+ (1,0) [0|1000] "m" Vector__XXX
 SG_ ADAS_tollstation : 19|2@0+ (1,0) [0|2] "" Vector__XXX
 SG_ SET_stopgo_timeEnable : 15|8@0+ (1,0) [0|180] "S" Vector__XXX
 SG_ IHU_32_Reserved1 : 7|8@0+ (1,0) [0|0] "" Vector__XXX

BO_ 1120 IHU_31: 8 IHU
 SG_ AdasSignDistance : 23|7@0+ (1,0) [0|100] "" Vector__XXX
 SG_ AdasSignType_reserve : 16|41@0+ (1,0) [0|0] "" Vector__XXX
 SG_ NavTrafficlights : 14|7@0+ (1,0) [0|100] "" Vector__XXX
 SG_ NavWinding : 7|9@0+ (1,0) [0|360] "" Vector__XXX

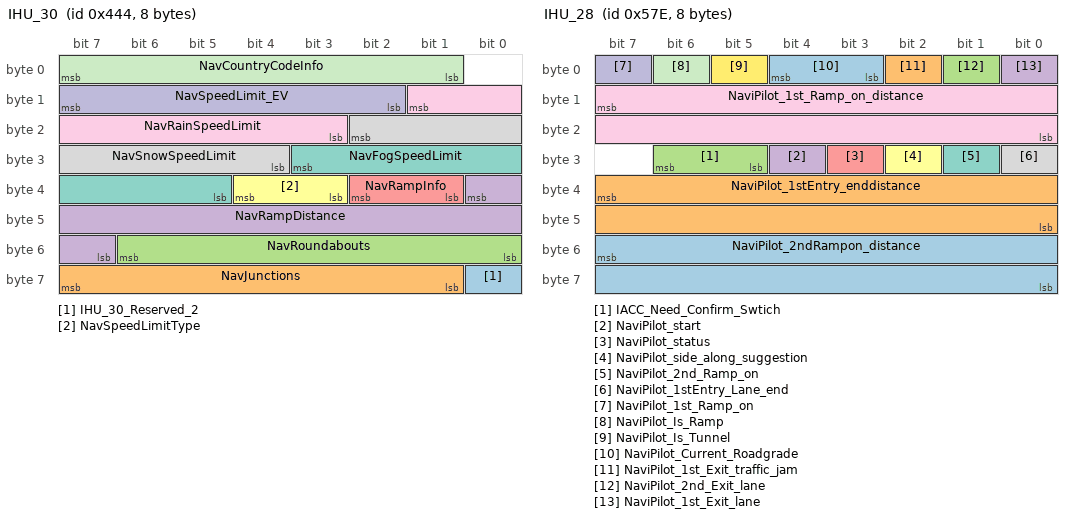
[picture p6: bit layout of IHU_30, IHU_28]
BO_ 1092 IHU_30: 8 IHU
 SG_ IHU_30_Reserved_2 : 56|1@0+ (1,0) [0|0] "" Vector__XXX
 SG_ NavJunctions : 63|7@0+ (1,0) [0|100] "" Vector__XXX
 SG_ NavRoundabouts : 54|7@0+ (1,0) [0|100] "" Vector__XXX
 SG_ NavRampDistance : 32|10@0+ (1,0) [0|1000] "m" Vector__XXX
 SG_ NavRampInfo : 34|2@0+ (1,0) [0|3] "" Vector__XXX
 SG_ NavSpeedLimitType : 36|2@0+ (1,0) [0|3] "" Vector__XXX
 SG_ NavFogSpeedLimit : 27|7@0+ (1,0) [0|120] "" Vector__XXX
 SG_ NavSnowSpeedLimit : 18|7@0+ (1,0) [0|120] "" Vector__XXX
 SG_ NavRainSpeedLimit : 9|7@0+ (1,0) [0|120] "" Vector__XXX
 SG_ NavSpeedLimit_EV : 15|6@0+ (1,0) [0|34] "" Vector__XXX
 SG_ NavCountryCodeInfo : 7|7@0+ (1,0) [0|127] "" Vector__XXX

BO_ 1330 IHU_29: 8 IHU
 SG_ IHU_29_Reserved_2 : 47|6@0+ (1,0) [0|0] "" Vector__XXX
 SG_ IHU_29_VoiceReminder : 59|2@0+ (1,0) [0|3] "" Vector__XXX
 SG_ IHU_29_SpeedLmtNmberE : 49|6@0+ (1,0) [0|63] "" Vector__XXX
 SG_ IHU_29_SpeedLmtNmberAb : 55|6@0+ (1,0) [0|63] "" Vector__XXX
 SG_ IHU_29_SLAMode : 41|2@0+ (1,0) [0|3] "" Vector__XXX
 SG_ ShowRoomSwt : 33|2@0+ (1,0) [0|3] "" Vector__XXX
 SG_ SLASpdlimitWarningAudSWSet : 35|2@0+ (1,0) [0|3] "" Vector__XXX
 SG_ SLWFONOFFSet : 37|2@0+ (1,0) [0|3] "" Vector__XXX
 SG_ IHU_29_DchaSet : 57|2@0+ (1,0) [0|2] "" Vector__XXX
 SG_ ElectcUnlckCmd : 15|1@0+ (1,0) [0|1] "" Vector__XXX
 SG_ IHU_29_ChrgElecLockSwt : 23|2@0+ (1,0) [0|3] "" Vector__XXX
 SG_ IHU_29_ChrgStopSoc : 29|8@0+ (1,0) [1|100] "%" Vector__XXX
 SG_ IHU_29_V2LStopSoc : 21|8@0+ (1,0) [1|100] "%" Vector__XXX
 SG_ IHU_29_KeepWrmSwt : 7|2@0+ (1,0) [0|3] "" Vector__XXX
 SG_ IHU_29_V2LSwt : 5|2@0+ (1,0) [0|3] "" Vector__XXX
 SG_ IHU_29_V2LFctSwt : 3|2@0+ (1,0) [0|3] "" Vector__XXX
 SG_ IHU_29_TowMod : 1|2@0+ (1,0) [0|3] "" Vector__XXX

BO_ 1406 IHU_28: 8 IHU
 SG_ NaviPilot_2ndRampon_distance : 55|16@0+ (1,0) [0|30000] "m" Vector__XXX
 SG_ NaviPilot_1stEntry_enddistance : 39|16@0+ (1,0) [0|30000] "m" Vector__XXX
 SG_ IACC_Need_Confirm_Swtich : 30|2@0+ (1,0) [0|3] "" Vector__XXX
 SG_ NaviPilot_start : 28|1@0+ (1,0) [0|1] "" Vector__XXX
 SG_ NaviPilot_status : 27|1@0+ (1,0) [0|1] "" Vector__XXX
 SG_ NaviPilot_side_along_suggestion : 26|1@0+ (1,0) [0|1] "" Vector__XXX
 SG_ NaviPilot_2nd_Ramp_on : 25|1@0+ (1,0) [0|1] "" Vector__XXX
 SG_ NaviPilot_1stEntry_Lane_end : 24|1@0+ (1,0) [0|1] "" Vector__XXX
 SG_ NaviPilot_1st_Ramp_on_distance : 15|16@0+ (1,0) [0|30000] "m" Vector__XXX
 SG_ NaviPilot_1st_Ramp_on : 7|1@0+ (1,0) [0|1] "" Vector__XXX
 SG_ NaviPilot_Is_Ramp : 6|1@0+ (1,0) [0|1] "" Vector__XXX
 SG_ NaviPilot_Is_Tunnel : 5|1@0+ (1,0) [0|1] "" Vector__XXX
 SG_ NaviPilot_Current_Roadgrade : 4|2@0+ (1,0) [0|3] "" Vector__XXX
 SG_ NaviPilot_1st_Exit_traffic_jam : 2|1@0+ (1,0) [0|1] "" Vector__XXX
 SG_ NaviPilot_2nd_Exit_lane : 1|1@0+ (1,0) [0|1] "" Vector__XXX
 SG_ NaviPilot_1st_Exit_lane : 0|1@0+ (1,0) [0|1] "" Vector__XXX

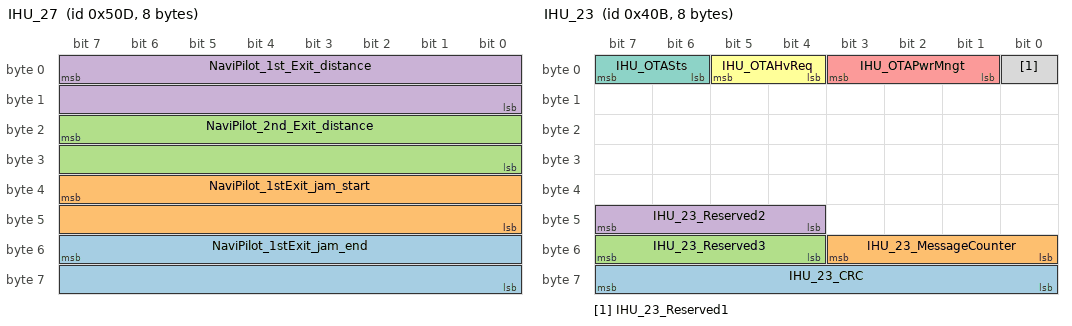
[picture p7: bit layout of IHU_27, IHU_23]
BO_ 1293 IHU_27: 8 IHU
 SG_ NaviPilot_1stExit_jam_end : 55|16@0+ (1,0) [0|30000] "m" Vector__XXX
 SG_ NaviPilot_1stExit_jam_start : 39|16@0+ (1,0) [0|30000] "m" Vector__XXX
 SG_ NaviPilot_2nd_Exit_distance : 23|16@0+ (1,0) [0|30000] "m" Vector__XXX
 SG_ NaviPilot_1st_Exit_distance : 7|16@0+ (1,0) [0|30000] "m" Vector__XXX

BO_ 1177 IHU_26: 8 IHU
 SG_ IHU_26_RRWinCmd : 62|7@0+ (1,0) [0|127] "" Vector__XXX
 SG_ IHU_26_Reserved2 : 48|2@0+ (1,0) [0|0] "" Vector__XXX
 SG_ IHU_26_WiprSnvty : 51|3@0+ (1,0) [0|7] "" Vector__XXX
 SG_ IHU_26_SeatLegSpprtPosnCmd : 55|4@0+ (1,0) [0|15] "" Vector__XXX
 SG_ IHU_26_RLWinCmd : 46|7@0+ (1,0) [0|127] "" Vector__XXX
 SG_ IHU_26_FRWinCmd : 37|7@0+ (1,0) [0|127] "" Vector__XXX
 SG_ IHU_26_FLWinCmd : 28|7@0+ (1,0) [0|127] "" Vector__XXX
 SG_ ChrgPortCover_Switch : 29|1@0+ (1,0) [0|1] "" Vector__XXX
 SG_ IHU_26_CenterLockSwt : 31|2@0+ (1,0) [0|3] "" Vector__XXX
 SG_ IHU_26_SeatLvlPosnCmd : 23|4@0+ (1,0) [0|15] "" Vector__XXX
 SG_ IHU_26_SeatHdrestHeiAdjmtCmd : 19|4@0+ (1,0) [0|15] "" Vector__XXX
 SG_ IHU_26_WinInhbSwt : 15|1@0+ (1,0) [0|1] "" Vector__XXX
 SG_ IHU_26_ReWinDefrstSwt : 14|1@0+ (1,0) [0|1] "" Vector__XXX
 SG_ IHU_26_SteerWhlHeatgSwt : 13|1@0+ (1,0) [0|1] "" Vector__XXX
 SG_ IHU_26_BackrAgPosnCmd : 12|5@0+ (1,0) [0|31] "" Vector__XXX
 SG_ IHU_26_SeatCushPosnCmd : 7|4@0+ (1,0) [0|15] "" Vector__XXX
 SG_ IHU_26_SeatHeiPosnCmd : 3|4@0+ (1,0) [0|15] "" Vector__XXX

BO_ 643 IHU_25: 8 IHU
 SG_ IHU_25__Resd2 : 63|1@0+ (1,0) [0|0] "" Vector__XXX
 SG_ IHU_25_APPsts : 62|1@0+ (1,0) [0|1] "" Vector__XXX
 SG_ IHU_25_AmbLigFlngModSel : 58|3@0+ (1,0) [0|7] "" Vector__XXX
 SG_ IHU_25_AmbLig14FlngEna : 55|1@0+ (1,0) [0|1] "" Vector__XXX
 SG_ IHU_25_AmbLig13FlngEna : 47|1@0+ (1,0) [0|1] "" Vector__XXX
 SG_ IHU_25_AmbLig12FlngEna : 46|1@0+ (1,0) [0|1] "" Vector__XXX
 SG_ IHU_25_AmbLigFadeINOUTStepTi : 54|7@0+ (1,0) [0|127] "" Vector__XXX
 SG_ IHU_25_AmbLig14FadeEna : 45|1@0+ (1,0) [0|1] "" Vector__XXX
 SG_ IHU_25_AmbLig13FadeEna : 44|1@0+ (1,0) [0|1] "" Vector__XXX
 SG_ IHU_25_AmbLig12FadeEna : 43|1@0+ (1,0) [0|1] "" Vector__XXX
 SG_ IHU_25_AmbLig11FadeEna : 42|1@0+ (1,0) [0|1] "" Vector__XXX
 SG_ IHU_25_AmbLig10FadeEna : 41|1@0+ (1,0) [0|1] "" Vector__XXX
 SG_ IHU_25_AmbLig09FadeEna : 40|1@0+ (1,0) [0|1] "" Vector__XXX
 SG_ IHU_25_AmbLig08FadeEna : 39|1@0+ (1,0) [0|1] "" Vector__XXX
 SG_ IHU_25_AmbLig07FadeEna : 38|1@0+ (1,0) [0|1] "" Vector__XXX
 SG_ IHU_25_AmbLig06FadeEna : 37|1@0+ (1,0) [0|1] "" Vector__XXX
 SG_ IHU_25_AmbLig05FadeEna : 36|1@0+ (1,0) [0|1] "" Vector__XXX
 SG_ IHU_25_AmbLig04FadeEna : 35|1@0+ (1,0) [0|1] "" Vector__XXX
 SG_ IHU_25_AmbLig03FadeEna : 34|1@0+ (1,0) [0|1] "" Vector__XXX
 SG_ IHU_25_AmbLig02FadeEna : 33|1@0+ (1,0) [0|1] "" Vector__XXX
 SG_ IHU_25_AmbLig01FadeEna : 32|1@0+ (1,0) [0|1] "" Vector__XXX
 SG_ IHU_25_AmbLigColorAdj : 31|8@0+ (1,0) [0|255] "" Vector__XXX
 SG_ IHU_25_AmbLigBriAdj : 23|8@0+ (1,0) [0|100] "%" Vector__XXX
 SG_ IHU_25__Resd1 : 15|2@0+ (1,0) [0|0] "" Vector__XXX
 SG_ IHU_25_AmbLig14Authn : 13|1@0+ (1,0) [0|1] "" Vector__XXX
 SG_ IHU_25_AmbLig13Authn : 12|1@0+ (1,0) [0|1] "" Vector__XXX
 SG_ IHU_25_AmbLig12Authn : 11|1@0+ (1,0) [0|1] "" Vector__XXX
 SG_ IHU_25_AmbLig11Authn : 10|1@0+ (1,0) [0|1] "" Vector__XXX
 SG_ IHU_25_AmbLig10Authn : 9|1@0+ (1,0) [0|1] "" Vector__XXX
 SG_ IHU_25_AmbLig09Authn : 8|1@0+ (1,0) [0|1] "" Vector__XXX
 SG_ IHU_25_AmbLig08Authn : 7|1@0+ (1,0) [0|1] "" Vector__XXX
 SG_ IHU_25_AmbLig07Authn : 6|1@0+ (1,0) [0|1] "" Vector__XXX
 SG_ IHU_25_AmbLig06Authn : 5|1@0+ (1,0) [0|1] "" Vector__XXX
 SG_ IHU_25_AmbLig05Authn : 4|1@0+ (1,0) [0|1] "" Vector__XXX
 SG_ IHU_25_AmbLig04Authn : 3|1@0+ (1,0) [0|1] "" Vector__XXX
 SG_ IHU_25_AmbLig03Authn : 2|1@0+ (1,0) [0|1] "" Vector__XXX
 SG_ IHU_25_AmbLig02Authn : 1|1@0+ (1,0) [0|1] "" Vector__XXX
 SG_ IHU_25_AmbLig01Authn : 0|1@0+ (1,0) [0|1] "" Vector__XXX

BO_ 1244 IHU_24: 8 IHU
 SG_ PassSeatMsgModeCmd : 63|3@0+ (1,0) [0|7] "" Vector__XXX
 SG_ PassSeatMsgStr_LvlCmd : 60|3@0+ (1,0) [0|7] "" Vector__XXX
 SG_ IHU_24_Reserved5 : 57|2@0+ (1,0) [0|0] "" Vector__XXX
 SG_ IHU_24_SetHUDRot : 54|4@0+ (1,0) [0|15] "" Vector__XXX
 SG_ IHU_24_Reserved3 : 25|2@0+ (1,0) [0|0] "" Vector__XXX
 SG_ AUTODefrostlevelKeySts : 50|3@0+ (1,0) [0|7] "" Vector__XXX
 SG_ DriverSeatMsg_ModeCmd : 39|3@0+ (1,0) [0|7] "" Vector__XXX
 SG_ DriverSeatMsgStr_Lvlcmd : 36|3@0+ (1,0) [0|7] "" Vector__XXX
 SG_ IHU_24_SetAdasDisp : 31|2@0+ (1,0) [0|3] "" Vector__XXX
 SG_ IHU_24_SetBlueToothDisp : 29|2@0+ (1,0) [0|3] "" Vector__XXX
 SG_ IHU_24_SetFaceIdOnoff : 27|2@0+ (1,0) [0|3] "" Vector__XXX
 SG_ IHU_24_PwrOff : 23|1@0+ (1,0) [0|1] "" Vector__XXX
 SG_ IHU_RearFogLightSwtCmd : 22|1@0+ (1,0) [0|1] "" Vector__XXX
 SG_ IHU_FrntFogLightSwtCmd : 21|1@0+ (1,0) [0|1] "" Vector__XXX
 SG_ IHU_24_SetAdasDispPoision : 20|3@0+ (1,0) [0|7] "" Vector__XXX
 SG_ IHU_24_SetNavDisp : 17|2@0+ (1,0) [0|3] "" Vector__XXX
 SG_ IHU_24_SetHudBri : 0|4@0+ (1,0) [0|15] "" Vector__XXX
 SG_ IHU_24_SetHudDispMod : 12|2@0+ (1,0) [0|3] "" Vector__XXX
 SG_ IHU_LightMainSwitchCmd : 10|3@0+ (1,0) [0|7] "" Vector__XXX
 SG_ IHU_24_SetHudHei : 4|4@0+ (1,0) [0|15] "" Vector__XXX
 SG_ IHU_24_SetHudDispOnOff : 7|3@0+ (1,0) [0|7] "" Vector__XXX

BO_ 1035 IHU_23: 8 IHU
 SG_ IHU_23_CRC : 63|8@0+ (1,0) [0|255] "" Vector__XXX
 SG_ IHU_23_MessageCounter : 51|4@0+ (1,0) [0|15] "" Vector__XXX
 SG_ IHU_23_Reserved3 : 55|4@0+ (1,0) [0|0] "" Vector__XXX
 SG_ IHU_23_Reserved2 : 47|4@0+ (1,0) [0|0] "" Vector__XXX
 SG_ IHU_OTAPwrMngt : 3|3@0+ (1,0) [0|7] "" Vector__XXX
 SG_ IHU_OTAHvReq : 5|2@0+ (1,0) [0|3] "" Vector__XXX
 SG_ IHU_OTASts : 7|2@0+ (1,0) [0|3] "" Vector__XXX
 SG_ IHU_23_Reserved1 : 0|1@0+ (1,0) [0|0] "" Vector__XXX

BO_ 1278 IHU_22: 8 IHU
 SG_ IHU_22_Reserved1 : 48|9@0+ (1,0) [0|0] "" Vector__XXX
 SG_ IHU_22_DispEvDteTyp : 50|2@0+ (1,0) [0|3] "" Vector__XXX
 SG_ IHU_22_DispPwrMod : 52|2@0+ (1,0) [0|3] "" Vector__XXX
 SG_ IHU_22_RCCPInhbSwt : 53|1@0+ (1,0) [0|1] "" Vector__XXX
 SG_ IHU_22_FRSeatAutVentnCmd : 55|2@0+ (1,0) [0|3] "" Vector__XXX
 SG_ IHU_22_FLSeatAutVentnCmd : 41|2@0+ (1,0) [0|3] "" Vector__XXX
 SG_ IHU_22_FRSeatAutHeatCmd : 45|2@0+ (1,0) [0|3] "" Vector__XXX
 SG_ IHU_22_FLSeatAutHeatCmd : 43|2@0+ (1,0) [0|3] "" Vector__XXX
 SG_ SHU3RSeatVentilationCmd : 32|3@0+ (1,0) [0|7] "" Vector__XXX
 SG_ SHU3LSeatVentilationCmd : 35|3@0+ (1,0) [0|7] "" Vector__XXX
 SG_ SHU3RSeatHeatLevelCmd : 38|3@0+ (1,0) [0|7] "" Vector__XXX
 SG_ SHU3LSeatHeatLevelCmd : 25|3@0+ (1,0) [0|7] "" Vector__XXX
 SG_ SHU2RSeatVentilationCmd : 28|3@0+ (1,0) [0|7] "" Vector__XXX
 SG_ SHU2MSeatVentilationCmd : 31|3@0+ (1,0) [0|7] "" Vector__XXX
 SG_ SHU2LSeatVentilationCmd : 18|3@0+ (1,0) [0|7] "" Vector__XXX
 SG_ SHU2RSeatHeatLevelCmd : 21|3@0+ (1,0) [0|7] "" Vector__XXX
 SG_ SHU2MSeatHeatLevelCmd : 8|3@0+ (1,0) [0|7] "" Vector__XXX
 SG_ SHU2LSeatHeatLevelCmd : 11|3@0+ (1,0) [0|7] "" Vector__XXX
 SG_ IHU_22_FRSeatVentilationCmd : 14|3@0+ (1,0) [0|7] "" Vector__XXX
 SG_ IHU_22_FLSeatVentilationCmd : 1|3@0+ (1,0) [0|7] "" Vector__XXX
 SG_ IHU_22_FRSeatHeatLevelCmd : 4|3@0+ (1,0) [0|7] "" Vector__XXX
 SG_ IHU_22_FLSeatHeatLevelCmd : 7|3@0+ (1,0) [0|7] "" Vector__XXX

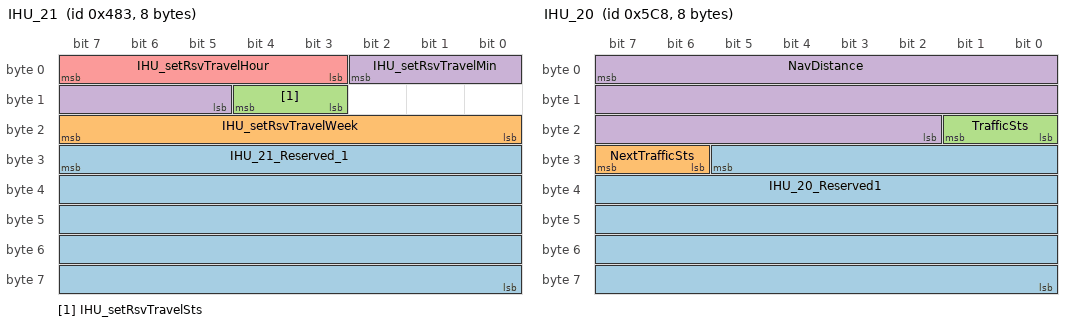
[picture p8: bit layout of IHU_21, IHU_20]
BO_ 1155 IHU_21: 8 IHU
 SG_ IHU_21_Reserved_1 : 31|40@0+ (1,0) [0|0] "" Vector__XXX
 SG_ IHU_setRsvTravelWeek : 23|8@0+ (1,0) [0|255] "" Vector__XXX
 SG_ IHU_setRsvTravelSts : 12|2@0+ (1,0) [0|3] "" Vector__XXX
 SG_ IHU_setRsvTravelMin : 2|6@0+ (1,0) [0|63] "min" Vector__XXX
 SG_ IHU_setRsvTravelHour : 7|5@0+ (1,0) [0|31] "h" Vector__XXX

BO_ 1480 IHU_20: 8 IHU
 SG_ IHU_20_Reserved1 : 29|38@0+ (1,0) [0|0] "" Vector__XXX
 SG_ NextTrafficSts : 31|2@0+ (1,0) [0|3] "" Vector__XXX
 SG_ TrafficSts : 17|2@0+ (1,0) [0|3] "" Vector__XXX
 SG_ NavDistance : 7|22@0+ (20,0) [0|83886060] "m" Vector__XXX

BO_ 1119 IHU_19: 8 IHU
 SG_ IHU_19_Reserved_1 : 53|14@0+ (1,0) [0|0] "" Vector__XXX
 SG_ IHU_19_Set_HdrestSpkrMod : 40|3@0+ (1,0) [0|7] "" Vector__XXX
 SG_ IHU_19_Set_AMPESEVol : 46|6@0+ (1,0) [0|63] "" Vector__XXX
 SG_ IHU_19_Set_AMPWelVol : 36|6@0+ (1,0) [0|63] "" Vector__XXX
 SG_ IHU_19_Set_AMPBTMediVol : 26|6@0+ (1,0) [0|63] "" Vector__XXX
 SG_ IHU_19_REQ_AMPA2BMediSound : 29|3@0+ (1,0) [0|7] "" Vector__XXX
 SG_ IHU_19_REQ_AMPA2BESESound : 31|2@0+ (1,0) [0|3] "" Vector__XXX
 SG_ IHU_19_PABSetCmd : 17|2@0+ (1,0) [0|3] "" Vector__XXX
 SG_ IHU_19_HwSet : 19|2@0+ (1,0) [0|3] "" Vector__XXX
 SG_ IHU_19_BSRBPASet : 21|2@0+ (1,0) [0|3] "" Vector__XXX
 SG_ REQ_AMPA2BKeyTone : 23|2@0+ (1,0) [0|3] "" Vector__XXX
 SG_ REQ_AMPA2BTTSSound : 15|2@0+ (1,0) [0|3] "" Vector__XXX
 SG_ REQ_AMPA2BVRSound : 13|2@0+ (1,0) [0|3] "" Vector__XXX
 SG_ REQ_AMPA2BNaviSound : 11|2@0+ (1,0) [0|3] "" Vector__XXX
 SG_ REQ_AMPA2BMediaSound : 9|2@0+ (1,0) [0|3] "" Vector__XXX
 SG_ Set_AMPMute : 7|2@0+ (1,0) [0|3] "" Vector__XXX
 SG_ Set_AMPSpeedVolume : 5|3@0+ (1,0) [0|7] "" Vector__XXX
 SG_ REQ_AMPA2BPhoneSound : 2|3@0+ (1,0) [0|7] "" Vector__XXX

CM_ SG_ 1050 HPA_Subscribe_Status "indicate HPA subscription status";
CM_ SG_ 1050 HPA_IHU_Audio_HPA_status "HPA feedback audio reminder(durning parking)";
CM_ SG_ 1050 FaultStatusCameraDVR "DVR working status";
CM_ SG_ 1050 REQ_AVMDisp_1 "AVM request IHU to change display content";
CM_ SG_ 1050 HPASubStsFeedback "HPA subscrib status feedback";
CM_ SG_ 1050 UndoSet_Feedback "Undo setting feedback";
CM_ SG_ 1050 Undo_fault_status "Undo fault status";
CM_ SG_ 1050 MOD_WorkSts "Indicate the MOD Work stats";
CM_ SG_ 1050 HPAMode "HPA??????";
CM_ SG_ 1050 HPAActive "HPA???????";
CM_ SG_ 1050 HPA_IHU_Audio_Park_Tips_1 "HPA??????????????????????????
HPA feedback audio reminder(durning HPA)";
CM_ SG_ 1050 HPA_IHU_Audio_Learn_Tips_1 "HPA?????????????????????
HPA feedback audio reminder(durning mapping)";
CM_ SG_ 1050 HPA_IHU_Audio_Park_Tips "HPA??????????????????????????
HPA feedback audio reminder(durning HPA)";
CM_ SG_ 1050 HPA_IHU_Audio_Learn_Tips "HPA?????????????????????
HPA feedback audio reminder(durning mapping)";
CM_ SG_ 1050 HPA_Exam_status "User Exam status";
CM_ SG_ 1050 REQ_BSVDisp "BSV display Request";
CM_ SG_ 1050 AVM_FactoryMode "AVM??????";
CM_ SG_ 1050 AVMFeedbackSts_RemoteMode "???????£¨AVM??????";
CM_ SG_ 1050 AVM_3_IHUTTSExtend "0x1: ???????£¨?????
0x2!mao!???????????????
0x3!mao!???P??!dou!??????????
0x4!mao!???????°§???????
0x5!mao!???????°§????
0x6!mao!?????????¶À??????°§??
0x7!mao!??????????????!dou!?????
0x8!mao!???????
0x9!mao!°§?????!dou!?????ß”???
0xA!mao!??¶À?????";
CM_ SG_ 1050 AVM_3_IHUTTS "Parking voice prompt
???????????
0x0: ??
0x1: ??????????????¶À
0x2: ???????????????
0x3: ??????APP??????????
0x4: ???????!dou!????
0x5: ???????!dou!????
0x6: ???????
0x7: °§???????!dou!??????????????
0x8: °§????????????????
0x9: °§???????!dou!???????¶ ????
0xA: °§???????
0xB: °§????????
0xC: ???????????!dou!?????
0xD: ????????????!dou!?????
0xE: ????????????!dou!?????
0xF: ???????????????!dou!???????
0x10: ??????????
0x11: ????????
0x12: ????????
0x13: ???????
0x14: ???????????????!dou!???????
0x15: ???????!dou!????
0x16: ???????!dou!????
0x17: ??????
0x18: ??????
0x19!mao!??????????????!dou!?????
0x1A!mao!?????????????!dou!?????
0x1B!mao!???????
0x1C!mao!????e????
0x1D!mao!?????????
0x1E!mao!??????????
0x1F!mao!?????¶À";
CM_ SG_ 1050 AVMDisplaySts "AVM?????????
AVM????¶ƒ????!dou!??0!dou!??DVD????????
AVM???????!dou!?????AVM???????????????????R?????????/?????!dou!??1!dou!DVD??????ß›?????????µµ";
CM_ BO_ 1267 "Source network message is \"Cyclic, 100ms\".
If no messages are received on source network, no messages are sent on the destination network.";
CM_ SG_ 1267 AIPM_2_DriveModeSet "????????¶À£¨??3?¶≈???£¨????? Not Active";
CM_ BO_ 1265 "?????????????????????????0
Source network message is \"NoMsgSendType, /\".
If no messages are received on source network, no messages are sent on the destination network.";
CM_ SG_ 1265 PanelKeyVoiceRemindReq "0x0£∫No action??DVD need not to respond to this signal 
0x1!mao! Request??DVD need to make an audible prompt??
Note!mao!When the panel detects that a button that requires an audible prompt is pressed, the signal is triggered to first send a frame 0x1:Request, and then send a frame 0x0:Not active.";
CM_ BO_ 704 "Source network message is \"Cyclic, 100ms\".
If no messages are received on source network, no messages are sent on the destination network.";
CM_ SG_ 704 CDPFailSts "???????????£¨CDP?ßπ";
CM_ SG_ 704 AVHSts "????Auto Hold??AVH??????????????
Off!mao!AVH??????
Standy!mao!AVH?????!dou!??????¶ƒ????
Active!mao!AVH???????";
CM_ SG_ 704 HDCFailSts "After IGN OFF, this signal should be set to 0 for avoiding ICM HDC warning.";
CM_ SG_ 704 CDPActive "???????£∫??????CDPActive=1_active??RWUActive=1_active£¨???????????";
CM_ SG_ 704 HHCFailSts "After IGN OFF, this signal should be set to 0 for avoiding ICM ESP warning.";
CM_ SG_ 704 VDCFailSts "After IGN OFF, this signal should be set to 0 for avoiding ICM ESP warning.";
CM_ SG_ 704 TCSFailSts "After IGN OFF, this signal should be set to 0 for avoiding ICM ESP warning.";
CM_ SG_ 704 AVHWarningMessage "????AVH???????Autohold?????£¨¶ƒ?????????/?????¶ƒ????£¨????????????
??????????????????AVH";
CM_ SG_ 704 ABS_ESP_Checksum "((Byte0+Byte1+ Byte2+Byte3+Byte4+Byte5) AND 0xFF) XOR 0xFF
Note: Details Please refer to specification??Standard Specification for CAN Data Link Layer_v1.1??section 2.3.3";
CM_ SG_ 704 ABS_ESP_MessageCounter "Rolling message counter(the maximum value of Alive counter is 15)
Note: Details Please refer to specification??Standard Specification for CAN Data Link Layer_v1.1??section 2.3.1";
CM_ SG_ 704 ESPSwitchStatus "??1?? means VDC and Engine Traction Control System (PTC) Function and Brake Traction Control System (BTC) Function disabled and Ignit ESP lamp.
0x0!mao!ESP???????
0x1!mao!ESP??????";
CM_ BO_ 932 "Source network message is \"Cyclic, 20ms\".
If no messages are received on source network, no messages are sent on the destination network.";
CM_ SG_ 932 ABSESP_8_Checksum "((Byte0+Byte1+ Byte2+Byte3+Byte4+Byte5+Byte6) AND 0xFF) XOR 0xFF
Note: Details Please refer to specification??Standard Specification for CAN Data Link Layer_v1.1??section 2.3.3";
CM_ SG_ 932 ABSESP_8_MessageCounter "Rolling message counter(the maximum value of Alive counter is 15)
Note: Details Please refer to specification??Standard Specification for CAN Data Link Layer_v1.1??section 2.3.1";
CM_ BO_ 931 "Source network message is \"Cyclic, 20ms\".
If no messages are received on source network, no messages are sent on the destination network.";
CM_ SG_ 931 ABSESP_7_Checksum "((Byte0+Byte1+ Byte2+Byte3+Byte4+Byte5+Byte6) AND 0xFF) XOR 0xFF
Note: Details Please refer to specification??Standard Specification for CAN Data Link Layer_v1.1??section 2.3.3";
CM_ SG_ 931 ABSESP_7_MessageCounter "Rolling message counter(the maximum value of Alive counter is 15)
Note: Details Please refer to specification??Standard Specification for CAN Data Link Layer_v1.1??section 2.3.1";
CM_ BO_ 793 "Source network message is \"Cyclic, 20ms\".
If no messages are received on source network, no messages are sent on the destination network.";
CM_ BO_ 787 "Source network message is \"Cyclic, 20ms\".
If no messages are received on source network, no messages are sent on the destination network.";
CM_ SG_ 787 ABS_ESP_3_AVHSts "Auto Hold??????";
CM_ SG_ 787 ABS_ESP_3_AVHFailSts "AutoHold?????ßπ??";
CM_ BO_ 800 "Source network message is \"Cyclic, 500ms\".
If no messages are received on source network, no messages are sent on the destination network.";
CM_ SG_ 800 ABM_1_MessageCounter "Rolling message counter(the maximum value of Alive counter is 15)
Note: Details Please refer to specification??Standard Specification for CAN Data Link Layer_v1.1??section 2.3.1";
CM_ SG_ 800 SecRowRBeltWarning "???¶À???£∫
???????????????
0x0:¶ƒ????/?????????
0x1:????¶ƒ?
?????¶À???!mao!
0x0:??????????
0x1;?????¶ƒ???";
CM_ SG_ 800 SecRowMBeltWarning "???¶À???£∫
??????ßµ????????
0x0:¶ƒ????/?????????
0x1:????¶ƒ?
?????¶À???!mao!
0x0:??????????
0x1;?????¶ƒ???";
CM_ SG_ 800 SecRowLBeltWarning "???¶À???£∫
??????????????
0x0:¶ƒ????/?????????
0x1:????¶ƒ?
?????¶À???!mao!
0x0:??????????
0x1;?????¶ƒ???";
CM_ SG_ 800 ThdRowRBeltWarning "???¶À???£∫
???????????????
0x0:¶ƒ????/?????????
0x1:????¶ƒ?
?????¶À???!mao!
0x0:??????????
0x1;?????¶ƒ???";
CM_ SG_ 800 ThdRowLBeltWarning "???¶À???£∫
??????????????
0x0:¶ƒ????/?????????
0x1:????¶ƒ?
?????¶À???!mao!
0x0:??????????
0x1;?????¶ƒ???";
CM_ SG_ 800 PsngrSeatBeltWarning "?????ß⁄???????????????ABM????????£¨??????ß⁄?????????ABM??????Startup???
???????SBR?ßÿ?";
CM_ SG_ 800 ABM_1_PABSetSts "ABM_1_PAB Set Status";
CM_ SG_ 1338 TMF_SpdAct "TMF motor actual speed";
CM_ SG_ 1250 BMS_LeftDCChargeTime "?????????
????PHEV?????????????   BMS_34????!dou!???°§??????????";
CM_ SG_ 1250 EVCC_ElectronicLockSts "???????????£¨EVCC_2?????IF????IHU????£¨???°§?????????PHEV????";
CM_ SG_ 1509 EngWhlTrqRatio "Crankshaft torque to wheel torque ratio";
CM_ SG_ 1509 MeanEffectiveTorque "this signal is crankshaft  torque";
CM_ SG_ 1509 EstimatedCouplingTorq "Estimated Coupling Torque??ESP???
AWD???®≤?!dou!????????";
CM_ BO_ 1812 "Source network message is \"NoMsgSendType, /\".
If no messages are received on source network, no messages are sent on the destination network.";
CM_ BO_ 1913 "Source network message is \"NoMsgSendType, /\".
If no messages are received on source network, no messages are sent on the destination network.";
CM_ BO_ 2041 "Source network message is \"NoMsgSendType, /\".
If no messages are received on source network, no messages are sent on the destination network.";
CM_ BO_ 2030 "Source network message is \"NoMsgSendType, /\".
If no messages are received on source network, no messages are sent on the destination network.";
CM_ BO_ 2029 "Source network message is \"NoMsgSendType, /\".
If no messages are received on source network, no messages are sent on the destination network.";
CM_ BO_ 2027 "Source network message is \"NoMsgSendType, /\".
If no messages are received on source network, no messages are sent on the destination network.";
CM_ BO_ 2025 "Source network message is \"NoMsgSendType, /\".
If no messages are received on source network, no messages are sent on the destination network.";
CM_ BO_ 2024 "Source network message is \"NoMsgSendType, /\".
If no messages are received on source network, no messages are sent on the destination network.";
CM_ BO_ 2014 "Source network message is \"NoMsgSendType, /\".
If no messages are received on source network, no messages are sent on the destination network.";
CM_ BO_ 2009 "Source network message is \"NoMsgSendType, /\".
If no messages are received on source network, no messages are sent on the destination network.";
CM_ BO_ 2008 "Source network message is \"NoMsgSendType, /\".
If no messages are received on source network, no messages are sent on the destination network.";
CM_ BO_ 2007 "Source network message is \"NoMsgSendType, /\".
If no messages are received on source network, no messages are sent on the destination network.";
CM_ BO_ 2006 "Source network message is \"NoMsgSendType, /\".
If no messages are received on source network, no messages are sent on the destination network.";
CM_ BO_ 1982 "Source network message is \"NoMsgSendType, /\".
If no messages are received on source network, no messages are sent on the destination network.";
CM_ BO_ 1981 "Source network message is \"NoMsgSendType, /\".
If no messages are received on source network, no messages are sent on the destination network.";
CM_ BO_ 1980 "Source network message is \"NoMsgSendType, /\".
If no messages are received on source network, no messages are sent on the destination network.";
CM_ BO_ 1979 "Source network message is \"NoMsgSendType, /\".
If no messages are received on source network, no messages are sent on the destination network.";
CM_ BO_ 1978 "Source network message is \"NoMsgSendType, /\".
If no messages are received on source network, no messages are sent on the destination network.";
CM_ BO_ 1977 "Source network message is \"NoMsgSendType, /\".
If no messages are received on source network, no messages are sent on the destination network.";
CM_ BO_ 1976 "Source network message is \"NoMsgSendType, /\".
If no messages are received on source network, no messages are sent on the destination network.";
CM_ BO_ 1975 "Source network message is \"NoMsgSendType, /\".
If no messages are received on source network, no messages are sent on the destination network.";
CM_ BO_ 1974 "Source network message is \"NoMsgSendType, /\".
If no messages are received on source network, no messages are sent on the destination network.";
CM_ BO_ 1951 "Source network message is \"NoMsgSendType, /\".
If no messages are received on source network, no messages are sent on the destination network.";
CM_ BO_ 1949 "Source network message is \"NoMsgSendType,/\".
If no messages are received on source network, no messages are sent on the destination network.";
CM_ BO_ 1946 "Source network message is \"NoMsgSendType, /\".
If no messages are received on source network, no messages are sent on the destination network.";
CM_ BO_ 1945 "Source network message is \"NoMsgSendType, /\".
If no messages are received on source network, no messages are sent on the destination network.";
CM_ BO_ 1938 "Source network message is \"NoMsgSendType, /\".
If no messages are received on source network, no messages are sent on the destination network.";
CM_ BO_ 1936 "Source network message is \"NoMsgSendType, /\".
If no messages are received on source network, no messages are sent on the destination network.";
CM_ BO_ 1919 "Source network message is \"NoMsgSendType, /\".
If no messages are received on source network, no messages are sent on the destination network.";
CM_ BO_ 1918 "Source network message is \"NoMsgSendType, /\".
If no messages are received on source network, no messages are sent on the destination network.";
CM_ BO_ 1917 "Source network message is \"NoMsgSendType, /\".
If no messages are received on source network, no messages are sent on the destination network.";
CM_ BO_ 1916 "Source network message is \"NoMsgSendType, /\".
If no messages are received on source network, no messages are sent on the destination network.";
CM_ BO_ 1910 "Source network message is \"NoMsgSendType, /\".
If no messages are received on source network, no messages are sent on the destination network.";
CM_ BO_ 1907 "Source network message is \"NoMsgSendType, /\".
If no messages are received on source network, no messages are sent on the destination network.";
CM_ BO_ 1906 "Source network message is \"NoMsgSendType, /\".
If no messages are received on source network, no messages are sent on the destination network.";
CM_ BO_ 1904 "Source network message is \"NoMsgSendType, /\".
If no messages are received on source network, no messages are sent on the destination network.";
CM_ BO_ 1885 "Source network message is \"NoMsgSendType, /\".
If no messages are received on source network, no messages are sent on the destination network.";
CM_ BO_ 1883 "Source network message is \"NoMsgSendType, /\".
If no messages are received on source network, no messages are sent on the destination network.";
CM_ BO_ 1880 "Source network message is \"NoMsgSendType, /\".
If no messages are received on source network, no messages are sent on the destination network.";
CM_ BO_ 1879 "Source network message is \"NoMsgSendType, /\".
If no messages are received on source network, no messages are sent on the destination network.";
CM_ BO_ 1878 "Source network message is \"NoMsgSendType, /\".
If no messages are received on source network, no messages are sent on the destination network.";
CM_ BO_ 1855 "Source network message is \"NoMsgSendType, /\".
If no messages are received on source network, no messages are sent on the destination network.";
CM_ BO_ 1854 "Source network message is \"NoMsgSendType, /\".
If no messages are received on source network, no messages are sent on the destination network.";
CM_ BO_ 1851 "Source network message is \"NoMsgSendType, /\".
If no messages are received on source network, no messages are sent on the destination network.";
CM_ BO_ 1848 "Source network message is \"NoMsgSendType, /\".
If no messages are received on source network, no messages are sent on the destination network.";
CM_ BO_ 1844 "Source network message is \"NoMsgSendType, /\".
If no messages are received on source network, no messages are sent on the destination network.";
CM_ BO_ 1840 "Source network message is \"NoMsgSendType, /\".
If no messages are received on source network, no messages are sent on the destination network.";
CM_ BO_ 1823 "Source network message is \"NoMsgSendType, /\".
If no messages are received on source network, no messages are sent on the destination network.";
CM_ BO_ 1811 "Source network message is \"NoMsgSendType, /\".
If no messages are received on source network, no messages are sent on the destination network.";
CM_ BO_ 1810 "Source network message is \"NoMsgSendType, /\".
If no messages are received on source network, no messages are sent on the destination network.";
CM_ BO_ 1809 "Source network message is \"NoMsgSendType, /\".
If no messages are received on source network, no messages are sent on the destination network.";
CM_ BO_ 1808 "Source network message is \"NoMsgSendType, /\".
If no messages are received on source network, no messages are sent on the destination network.";
CM_ BO_ 2005 "Source network message is \"NoMsgSendType,/\".
If no messages are received on source network, no messages are sent on the destination network.";
CM_ BO_ 1948 "Source network message is \"NoMsgSendType,/\".
If no messages are received on source network, no messages are sent on the destination network.";
CM_ BO_ 1874 "Source network message is \"NoMsgSendType,/\".
If no messages are received on source network, no messages are sent on the destination network.";
CM_ BO_ 1843 "Source network message is \"NoMsgSendType,/\".
If no messages are received on source network, no messages are sent on the destination network.";
CM_ BO_ 1905 "Source network message is \"NoMsgSendType,/\".
If no messages are received on source network, no messages are sent on the destination network.";
CM_ BO_ 2028 "Source network message is \"NoMsgSendType,/\".
If no messages are received on source network, no messages are sent on the destination network.";
CM_ BO_ 2026 "Source network message is \"NoMsgSendType,/\".
If no messages are received on source network, no messages are sent on the destination network.";
CM_ BO_ 1847 "Source network message is \"NoMsgSendType,/\".
If no messages are received on source network, no messages are sent on the destination network.";
CM_ BO_ 2004 "Source network message is \"NoMsgSendType,/\".
If no messages are received on source network, no messages are sent on the destination network.";
CM_ BO_ 2003 "Source network message is \"NoMsgSendType,/\".
If no messages are received on source network, no messages are sent on the destination network.";
CM_ BO_ 2002 "Source network message is \"NoMsgSendType,/\".
If no messages are received on source network, no messages are sent on the destination network.";
CM_ BO_ 2001 "Source network message is \"NoMsgSendType,/\".
If no messages are received on source network, no messages are sent on the destination network.";
CM_ BO_ 2000 "Source network message is \"NoMsgSendType,/\".
If no messages are received on source network, no messages are sent on the destination network.";
CM_ BO_ 1999 "Source network message is \"NoMsgSendType, /\".
If no messages are received on source network, no messages are sent on the destination network.";
CM_ BO_ 1797 "Source network message is \"NoMsgSendType, /\".
If no messages are received on source network, no messages are sent on the destination network.";
CM_ BO_ 1803 "Source network message is \"NoMsgSendType, /\".
If no messages are received on source network, no messages are sent on the destination network.";
CM_ BO_ 1800 "Source network message is \"NoMsgSendType, /\".
If no messages are received on source network, no messages are sent on the destination network.";
CM_ BO_ 1825 "Source network message is \"NoMsgSendType, /\".
If no messages are received on source network, no messages are sent on the destination network.";
CM_ BO_ 1967 "Source network message is \"NoMsgSendType, /\".
If no messages are received on source network, no messages are sent on the destination network.";
CM_ SG_ 1560 WakeupSource_IHU "Wakeup Source
Note: Details Please refer to specification??IF CAN IHU Network Management Specification ??section10.2 and ??IF CAN DMC Network Management Specification ??section10.2";
CM_ SG_ 1560 ECUSPEC_AWAKE_IHU "ECU keeps the network awake for ECU-define reasons for which communication is needed";
CM_ SG_ 1560 DIAGNOSTIC_AWAKE_IHU "ECU needs communication for diagnostic purpose and keeps network awake.";
CM_ SG_ 1560 IGNITION_AWAKE_IHU "ECU can?t release communication because ignition (KL15) is turn on, or KLR is turned on";
CM_ SG_ 1560 NETWORK_AWAKE_IHU "ECU keeps the network awake due to the CAN message received from the network";
CM_ SG_ 1560 ECUSPEC_WAKEUP_IHU "ECU was in ??power off??, ??Bus Sleep??, ??Pre-pare Bus Sleep?? or ??Ready Sleep?? mode or ??awake?? and re-started by ECU specific reason (e.g. pressed Button, timer, etc.)";
CM_ SG_ 1560 NETWORK_WAKEUP_IHU "ECU was in ??Power off??, ??Bus Sleep??, ??Pre-pare Bus Sleep?? or ??Ready Sleep?? Mode and then re-started by a network communication.";
CM_ SG_ 1560 RESET_WAKEUP_IHU "If ECU was already awake, in ??Prepare Bus Sleep?? or ??Ready Sleep?? mode and re-started by an internal or an external reset.";
CM_ SG_ 1560 IGNITION_WAKEUP_IHU "ECU was ??power off?? or ??Bus sleep?? mode and started by ignition switch";
CM_ SG_ 1560 RMR_IHU_CBV "If set to 1 to force the network management of all other nodes on the bus into the re-peat message state.";
CM_ SG_ 1560 srcNodeID_IHU_SNI "The srcNodeID of IHU is 0x18";
CM_ SG_ 1266 TBOX_SetAVMVeiw "???APP??????AVM???";
CM_ SG_ 1266 TBOX_SetAVMOnReq "???APP??????AVM??????";
CM_ SG_ 1312 TBOX_1_RemDiagSts "Remote Diagnostic Status";
CM_ SG_ 1243 STAT_HUDRotation "STAT_HUDRotation
HUD?????????";
CM_ SG_ 1243 STAT_ADASDisplayPoision "STAT_ADASDisplayPoision";
CM_ SG_ 1243 HUD_1_HUDHiTWarn "?HUD?high?temperature?warning";
CM_ SG_ 1243 STAT_HUDBrightness "STAT_HUDBrightness";
CM_ SG_ 1243 STAT_HUD "STAT_HUD";
CM_ SG_ 1243 STAT_HUDProfileID "STAT_HUDProfileID";
CM_ SG_ 1243 STAT_HUDDisplayMod "STAT_HUDDisplayMod";
CM_ SG_ 1243 STAT_HUDDisplayOnOff "STAT_HUDDisplayOnOff";
CM_ SG_ 1243 STAT_HUDHeight "STAT_HUDHeight";
CM_ BO_ 1140 "Not Active?????????????";
CM_ SG_ 1140 STAT_SurndFnOnOff "Surround_On_Off_Request feedback";
CM_ SG_ 1140 STAT_VirtualSbwfrOnOff "Amplifier sound effect midtreble feedback";
CM_ SG_ 1140 STAT_AMPSoundEffectMidTreble "Amplifier sound effect midbass feedback";
CM_ SG_ 1140 STAT_AMPSoundEffectMidBass "Amplifier sound effect megabass feedback";
CM_ SG_ 1140 STAT_AMPSoundEffectMegaBass "AMP Power Ready Status with A2B";
CM_ SG_ 1140 STAT_AMPPwrRdySts "A2B Connect Ready Status feedback";
CM_ SG_ 1140 STAT_ENCOnOff "Engine Noise Canceling Function On Off Switch Feedback";
CM_ SG_ 1140 STAT_AMPESEVol "Volume
????,???31??0-31??";
CM_ SG_ 1140 STAT_AMPWelVol "Welcome Volume
??????,???31??0-31??";
CM_ SG_ 1140 STAT_AMPBTMediVol "Media Volume
e????????,???31??0-31??";
CM_ SG_ 1140 STAT_AMPTEMP "Temperature status of power amplifier
?????????";
CM_ SG_ 1140 STAT_AMPMute "????????????????
????????????lin??????????DVD!dou!DVD???CAN????
????";
CM_ SG_ 1140 STAT_AMPSpeedVolume "????????
????????????!mao!???!dun!??!dun!??!dun!??.
?????????????????!dou!??y???????Entertainment???????????????????????????????????????";
CM_ SG_ 1140 EAMP_2_HdrestSpkrMod "Set the headrest speaker mode using the host softkey
???????????????????????????????
0x0!mao!??????
0x1: ??????
0x2: ??????
0x3:?????
0x4:???
0x5:???
0x6:???
0x8:???";
CM_ BO_ 1121 "Not Active?????????????";
CM_ SG_ 1121 STAT_AMPAlarmVolume "??????£¨?????¶∂?1~10";
CM_ SG_ 1121 STAT_AMPLoudness "???£∫???????????????y???????Entertainment?????£¨??????????????????????";
CM_ SG_ 1121 STAT_AMPLiveAcoustics "?????ßπ?????????
EQ:equalizer";
CM_ SG_ 1121 STAT_AMPSoundFieldFader "???????/???????????Y_axis??";
CM_ SG_ 1121 STAT_AMPSoundFieldBalance "???????/??????????£∫???????????????????????X_axis??
?????????¶∂?-7~+7";
CM_ SG_ 1121 STAT_AMPSoundEffectTreble "??ßπ?????????????????????????";
CM_ SG_ 1121 STAT_AMPSoundEffectMidrange "??ßπ??????????????????????????";
CM_ SG_ 1121 STAT_AMPSoundEffectBass "??ßπ?????????????????????????'-7~+7£¨";
CM_ SG_ 1121 STAT_AMPSoundEffect "??ßπ????
????!mao!?????!dun!???!dun!????!dun!???!dun!???!dun!???!dun!????!dun!???

0x1: Customer-defined mode?????
0x2: Standard mode ?????
0x3: Popular mode ??????
0x4: Jazz mode ?????
0x5: Classic mode ?????
0x6: Rock mode ?????
0x7: Vocals mode??????
0x8: Rural model(?????)";
CM_ SG_ 1121 STAT_AMPRestoreDefaults "??????????£¨????£∫????°¢??ßπ°¢?????????????";
CM_ SG_ 1121 STAT_AMPDefaultVolume "???????????
0~ 31!dou!
?????y???????Entertainment???????????????????????!dou!
? ????????????????????A?!dou!??????y?????????ß≥??A!dou!?????????????????????????????????????????y?????????????A!dou!??????????????????????A";
CM_ SG_ 1121 STAT_AMPSoundFocus "???????
0x1!mao!Customized(???Balance/Fader)
0x2!mao!All(Passenger)
0x3!mao!Driver
0x4!mao!Front
0x5!mao!Rear
0x6!mao!Sleep(Baby Mode)
0x7!mao!VIP(Boss)";
CM_ SG_ 1121 STAT_AMPPhoneVolume "?¥¬????,?????¶∂?0~25";
CM_ SG_ 1121 STAT_AMPMediaVolume "y????,???31??0-31??";
CM_ SG_ 1121 STAT_AMPKeyTone "?????????";
CM_ SG_ 1121 STAT_AMPVRVolume "???????????£¨0~10£¨
VR!dou!????!mao!ß≥?????!dou!EAMP?????????????";
CM_ SG_ 1121 STAT_AMPNaviVolume "??????,0~10";
CM_ SG_ 1242 RsvTravelWeek "??????8??bit
???¶À?????????????????????????? 1?????0?????!dou!????????0
?????¶À??????¶À???¶¡??????????
Bit 7 : ????????????????  1=?? 0=???
Bit 6 : 1=???? 0=??
Bit 5 : 1=???? 0=??
Bit 4 : 1=???? 0=??
Bit 3 : 1=???? 0=??
Bit 2 : 1=???? 0=??
Bit 1 : 1=??? 0=??
Bit 0 : 1=??? 0=??";
CM_ SG_ 1242 TBOX_RsvTravelSts "?????ß·??????°¬???";
CM_ SG_ 1242 TBOX_RsvTravelMin "?????? ???°¬??????";
CM_ SG_ 1242 TBOX_RsvTravelHour "?????? ????ß≥?????";
CM_ SG_ 856 TBOX_ChargeTimeWeekFed1 "You can choose several day of the week
??????8??bit
???¶À????????????????????????? 1?????0?????!dou!????????0
?????¶À??????¶À???¶¡??????????
Bit 7 : ???????????????  1=?? 0=???
Bit 6 : 1=???? 0=??
Bit 5 : 1=???? 0=??
Bit 4 : 1=???? 0=??
Bit 3 : 1=???? 0=??
Bit 2 : 1=???? 0=??
Bit 1 : 1=??? 0=??
Bit 0 : 1=??? 0=??";
CM_ BO_ 1150 "Only for M32TFL Project";
CM_ SG_ 1150 IHU_32_CRC "SAE J1850 CRC-8";
CM_ SG_ 1150 IHU_32_MessageCounter "Alivecounter";
CM_ SG_ 1150 APASoftKeyRequest "APA interface display";
CM_ SG_ 1150 SET_BSV_Enable "set blind area assitance switch";
CM_ SG_ 1150 HPA_Voice_Confirmed "Driver voice confirm";
CM_ SG_ 1150 HPA_Voice_FuctionSwitch "Driver voice";
CM_ SG_ 1150 PDCmute_Setting "PDC mute";
CM_ SG_ 1150 AVMSoftKeyRequest "AVM Soft Key Request";
CM_ SG_ 1150 ADAS_tollstation_Dis "toll station distance";
CM_ SG_ 1150 ADAS_tollstation "toll station";
CM_ SG_ 1150 SET_stopgo_timeEnable "The time of stop&go  select switch in IHU.";
CM_ SG_ 1120 AdasSignDistance "???????";
CM_ SG_ 1120 AdasSignType_reserve "????????_???";
CM_ SG_ 1120 NavTrafficlights "0??????100??????????£¨??0??????100?????ß‹????????£¨??£∫60=????????60??";
CM_ SG_ 1120 NavWinding "?????°§?????????£¨????¶∂0~360???
?????????!mao!?????°§????!dou!?????°§???1??2?1000??!dou!3??4?600??!dou!5?400??!dou!???????°§??ßπ??ßµ????
?????????°§??ADAS??";
CM_ SG_ 1092 NavJunctions "0??????100??????????£¨??0??????100?????ßﬂ????????£¨??£∫60=???????60??";
CM_ SG_ 1092 NavRoundabouts "0??????100?????????£¨??0??????100????????????????£¨??£∫50=?????£¨???????50";
CM_ SG_ 1092 NavRampDistance "???????????";
CM_ SG_ 1092 NavRampInfo "???°§????????
0x0:unknown ??????????
0x1:exists ???1????????????°§???????
0x2:About to leave ?????????";
CM_ SG_ 1092 NavSpeedLimitType "??°§????????";
CM_ SG_ 1092 NavFogSpeedLimit "?????°§?????";
CM_ SG_ 1092 NavSnowSpeedLimit "????°§?????";
CM_ SG_ 1092 NavRainSpeedLimit "?????°§?????";
CM_ SG_ 1092 NavSpeedLimit_EV "??°§?????-EV???";
CM_ SG_ 1092 NavCountryCodeInfo "???????";
CM_ SG_ 1330 IHU_29_VoiceReminder "?????????????????(???ADAS????)";
CM_ SG_ 1330 IHU_29_SpeedLmtNmberE "?????????????????£¨??-20%??20%";
CM_ SG_ 1330 IHU_29_SpeedLmtNmberAb "??????????????£¨??-10??10";
CM_ SG_ 1330 IHU_29_SLAMode "????????£¨????????????ß›????";
CM_ SG_ 1330 ShowRoomSwt "????????????:CH Can HCU????";
CM_ SG_ 1330 IHU_29_DchaSet "?????????¬C?????PHEV                          External discharge of main engine for PHEV";
CM_ SG_ 1330 ElectcUnlckCmd "???????????????PHEV                                            Added soft switch of charging gun for PHEV";
CM_ SG_ 1330 IHU_29_ChrgElecLockSwt "???????????:
charge electric  lock switch";
CM_ SG_ 1330 IHU_29_ChrgStopSoc "?????SOC:
charge stop SOC";
CM_ SG_ 1330 IHU_29_V2LStopSoc "V2L?????SOC:
V2L stop SOC";
CM_ SG_ 1330 IHU_29_KeepWrmSwt "(??????1??????):
keep warm switch";
CM_ SG_ 1330 IHU_29_V2LSwt "V2L??¬C??:
V2L  switch";
CM_ SG_ 1330 IHU_29_V2LFctSwt "V2L??¿H?????:
V2L function switch";
CM_ SG_ 1330 IHU_29_TowMod "?????:
tow mode";
CM_ SG_ 1406 NaviPilot_2ndRampon_distance "the distance to 2nd on-ramp from current location";
CM_ SG_ 1406 NaviPilot_1stEntry_enddistance "the distance to 1st entrance lane end from current location";
CM_ SG_ 1406 IACC_Need_Confirm_Swtich "The IACC driver confirm enable switch in IHU. Defacult need to confirm.";
CM_ SG_ 1406 NaviPilot_start "Navi system Status??Navi system active NOA after HWA active)";
CM_ SG_ 1406 NaviPilot_status "If signal from Navi system is valid";
CM_ SG_ 1406 NaviPilot_side_along_suggestion "Indicate if there is suggestion vehicle should be driven along left or right side";
CM_ SG_ 1406 NaviPilot_2nd_Ramp_on "If the 2nd on-ramp of current path exists and already in the scope";
CM_ SG_ 1406 NaviPilot_1stEntry_Lane_end "If the 1st entrance lane end of current path exists and already in the scope";
CM_ SG_ 1406 NaviPilot_1st_Ramp_on_distance "the distance to 1st on-ramp from current location";
CM_ SG_ 1406 NaviPilot_1st_Ramp_on "If the 1st on-ramp of current path is already in the scope";
CM_ SG_ 1406 NaviPilot_Is_Ramp "If current road is ramp or not";
CM_ SG_ 1406 NaviPilot_Is_Tunnel "If current road is tunnel or not";
CM_ SG_ 1406 NaviPilot_Current_Roadgrade "Report of current road grade";
CM_ SG_ 1406 NaviPilot_1st_Exit_traffic_jam "If there is traffic jam when go into 1st exit";
CM_ SG_ 1406 NaviPilot_2nd_Exit_lane "If the 2nd exit of current path exists and already in the scope";
CM_ SG_ 1406 NaviPilot_1st_Exit_lane "If the 1st exit of current path is already in the scope";
CM_ SG_ 1293 NaviPilot_1stExit_jam_end "the distance to the end of traffic jam from current location";
CM_ SG_ 1293 NaviPilot_1stExit_jam_start "the distance to the start of traffic jam from current location";
CM_ SG_ 1293 NaviPilot_2nd_Exit_distance "the distance to 2nd exit from current location";
CM_ SG_ 1293 NaviPilot_1st_Exit_distance "the distance to 1st exit from current location";
CM_ SG_ 1177 IHU_26_RRWinCmd "???????????ßµ????°¢????????";
CM_ SG_ 1177 IHU_26_WiprSnvty "WiperSensitivity????????";
CM_ SG_ 1177 IHU_26_SeatLegSpprtPosnCmd "Seat leg support position command";
CM_ SG_ 1177 IHU_26_RLWinCmd "???????????ßµ????°¢????????";
CM_ SG_ 1177 IHU_26_FRWinCmd "???????????ßµ????°¢??????????";
CM_ SG_ 1177 IHU_26_FLWinCmd "???????????ßµ????°¢??????????";
CM_ SG_ 1177 ChrgPortCover_Switch "????????";
CM_ SG_ 1177 IHU_26_CenterLockSwt "CenterLock?ß·???????";
CM_ SG_ 1177 IHU_26_SeatLvlPosnCmd "Seat level position command";
CM_ SG_ 1177 IHU_26_SeatHdrestHeiAdjmtCmd "Seat headrest height adjustment command";
CM_ SG_ 1177 IHU_26_WinInhbSwt "Window Inhibit ???????????";
CM_ SG_ 1177 IHU_26_ReWinDefrstSwt "Rear window defrost??ºö????";
CM_ SG_ 1177 IHU_26_SteerWhlHeatgSwt "Steering Wheel heating?????????";
CM_ SG_ 1177 IHU_26_BackrAgPosnCmd "Seat back angle position command";
CM_ SG_ 1177 IHU_26_SeatCushPosnCmd "Seat cushion position command";
CM_ SG_ 1177 IHU_26_SeatHeiPosnCmd "Seat height position command";
CM_ SG_ 643 IHU_25_AmbLigFlngModSel "Ambient Lighting_Flowing_mode_select";
CM_ SG_ 643 IHU_25_AmbLig14FlngEna "Ambient Lighting14_Flowing_ENABLE";
CM_ SG_ 643 IHU_25_AmbLig13FlngEna "Ambient Lighting13_Flowing_ENABLE";
CM_ SG_ 643 IHU_25_AmbLig12FlngEna "Ambient Lighting12_Flowing_ENABLE";
CM_ SG_ 643 IHU_25_AmbLigFadeINOUTStepTi "Ambient Lighting_FADE_IN/OUT_STEP_TIME
T on = IHU_25_AmbLigFadeIN/OUTStepTi*50ms";
CM_ SG_ 643 IHU_25_AmbLig14FadeEna "Ambient Lighting14_FADE_ENABLE";
CM_ SG_ 643 IHU_25_AmbLig13FadeEna "Ambient Lighting13_FADE_ENABLE";
CM_ SG_ 643 IHU_25_AmbLig12FadeEna "Ambient Lighting12_FADE_ENABLE";
CM_ SG_ 643 IHU_25_AmbLig11FadeEna "Ambient Lighting11_FADE_ENABLE";
CM_ SG_ 643 IHU_25_AmbLig10FadeEna "Ambient Lighting10_FADE_ENABLE";
CM_ SG_ 643 IHU_25_AmbLig09FadeEna "Ambient Lighting9_FADE_ENABLE";
CM_ SG_ 643 IHU_25_AmbLig08FadeEna "Ambient Lighting8_FADE_ENABLE";
CM_ SG_ 643 IHU_25_AmbLig07FadeEna "Ambient Lighting7_FADE_ENABLE";
CM_ SG_ 643 IHU_25_AmbLig06FadeEna "Ambient Lighting6_FADE_ENABLE";
CM_ SG_ 643 IHU_25_AmbLig05FadeEna "Ambient Lighting5_FADE_ENABLE";
CM_ SG_ 643 IHU_25_AmbLig04FadeEna "Ambient Lighting4_FADE_ENABLE";
CM_ SG_ 643 IHU_25_AmbLig03FadeEna "Ambient Lighting3_FADE_ENABLE";
CM_ SG_ 643 IHU_25_AmbLig02FadeEna "Ambient Lighting2_FADE_ENABLE";
CM_ SG_ 643 IHU_25_AmbLig01FadeEna "Ambient Lighting1_FADE_ENABLE";
CM_ SG_ 643 IHU_25_AmbLigColorAdj "Ambient Lighting_Color_ADJUST";
CM_ SG_ 643 IHU_25_AmbLigBriAdj "Ambient Lighting_Brightness_ADJUST";
CM_ SG_ 643 IHU_25_AmbLig14Authn "Ambient Lighting14_Authorization";
CM_ SG_ 643 IHU_25_AmbLig13Authn "Ambient Lighting13_Authorization";
CM_ SG_ 643 IHU_25_AmbLig12Authn "Ambient Lighting12_Authorization";
CM_ SG_ 643 IHU_25_AmbLig11Authn "Ambient Lighting11_Authorization";
CM_ SG_ 643 IHU_25_AmbLig10Authn "Ambient Lighting10_Authorization";
CM_ SG_ 643 IHU_25_AmbLig09Authn "Ambient Lighting09_Authorization";
CM_ SG_ 643 IHU_25_AmbLig08Authn "Ambient Lighting08_Authorization";
CM_ SG_ 643 IHU_25_AmbLig07Authn "Ambient Lighting07_Authorization";
CM_ SG_ 643 IHU_25_AmbLig06Authn "Ambient Lighting06_Authorization";
CM_ SG_ 643 IHU_25_AmbLig05Authn "Ambient Lighting05_Authorization";
CM_ SG_ 643 IHU_25_AmbLig04Authn "Ambient Lighting04_Authorization";
CM_ SG_ 643 IHU_25_AmbLig03Authn "Ambient Lighting03_Authorization";
CM_ SG_ 643 IHU_25_AmbLig02Authn "Ambient Lighting02_Authorization";
CM_ SG_ 643 IHU_25_AmbLig01Authn "Ambient Lighting01_Authorization";
CM_ BO_ 1244 "????DVD?????????????????????¶≤????????????????????Not Active.";
CM_ SG_ 1244 IHU_24_SetHUDRot "???????HUD???";
CM_ SG_ 1244 AUTODefrostlevelKeySts "?????????????????";
CM_ SG_ 1244 DriverSeatMsg_ModeCmd "driver seat massage mode";
CM_ SG_ 1244 DriverSeatMsgStr_Lvlcmd "driver seat massage level";
CM_ SG_ 1244 IHU_24_SetAdasDisp "Set_ADASDisplay";
CM_ SG_ 1244 IHU_24_SetBlueToothDisp "Set_BluetoothDisplay";
CM_ SG_ 1244 IHU_24_SetFaceIdOnoff "Set_FaceIDOnOFF";
CM_ SG_ 1244 IHU_24_PwrOff "?????¶Ã?";
CM_ SG_ 1244 IHU_24_SetAdasDispPoision "Set_ADASDisplayPoision";
CM_ SG_ 1244 IHU_24_SetNavDisp "Set_NavigationDisplay";
CM_ SG_ 1244 IHU_24_SetHudBri "Set_HUDBrightness";
CM_ SG_ 1244 IHU_24_SetHudDispMod "Set_HUDDisplayMode";
CM_ SG_ 1244 IHU_LightMainSwitchCmd "ß≥??°¢????°¢Auto????";
CM_ SG_ 1244 IHU_24_SetHudHei "Set_HUDHeight";
CM_ SG_ 1244 IHU_24_SetHudDispOnOff "Set_HUDDisplayOnOff";
CM_ SG_ 1035 IHU_23_CRC "SAE J1850 CRC-8";
CM_ SG_ 1035 IHU_23_MessageCounter "Alivecounter";
CM_ SG_ 1035 IHU_OTAPwrMngt "Power Management";
CM_ SG_ 1035 IHU_OTAHvReq "OTA high voltage power down request";
CM_ SG_ 1035 IHU_OTASts "OTA status";
CM_ BO_ 1278 "??????¶≤???3?¶≈????? ???????Not Active.";
CM_ SG_ 1278 IHU_22_Reserved1 "IHU_Backrest Angle adjustment";
CM_ SG_ 1278 IHU_22_DispEvDteTyp "????????????ß›?????/??????/????????????";
CM_ SG_ 1278 IHU_22_DispPwrMod "????????????ß›??????/HEV???/EV?????????";
CM_ SG_ 1278 IHU_22_RCCPInhbSwt "??????????????????";
CM_ SG_ 1278 IHU_22_FRSeatAutVentnCmd "Passenger Seat Automatic Ventilation Command";
CM_ SG_ 1278 IHU_22_FLSeatAutVentnCmd "Driver Seat Automatic Ventilation Command";
CM_ SG_ 1278 IHU_22_FRSeatAutHeatCmd "Passenger Seat Automatic Heat Command";
CM_ SG_ 1278 IHU_22_FLSeatAutHeatCmd "Driver Seat Automatic Heat Command";
CM_ SG_ 1278 SHU3RSeatVentilationCmd "?????????????????????";
CM_ SG_ 1278 SHU3LSeatVentilationCmd "?????????????????????";
CM_ SG_ 1278 SHU3RSeatHeatLevelCmd "??????????????¶Ã??????";
CM_ SG_ 1278 SHU3LSeatHeatLevelCmd "??????????????¶Ã??????";
CM_ SG_ 1278 SHU2RSeatVentilationCmd "?????????????????????
(M1E??????????)";
CM_ SG_ 1278 SHU2MSeatVentilationCmd "?????????ßﬁ???????????
(M1E??????????)";
CM_ SG_ 1278 SHU2LSeatVentilationCmd "?????????????????????
(M1E??????????)";
CM_ SG_ 1278 SHU2RSeatHeatLevelCmd "??????????????¶Ã??????
(M1E??????????)";
CM_ SG_ 1278 SHU2MSeatHeatLevelCmd "?????????ßﬁ????¶Ã??????";
CM_ SG_ 1278 SHU2LSeatHeatLevelCmd "??????????????¶Ã??????";
CM_ SG_ 1278 IHU_22_FRSeatVentilationCmd "????????????????????";
CM_ SG_ 1278 IHU_22_FLSeatVentilationCmd "?????????????????????";
CM_ SG_ 1278 IHU_22_FRSeatHeatLevelCmd "?????????????¶Ã??????";
CM_ SG_ 1278 IHU_22_FLSeatHeatLevelCmd "??????????????¶Ã??????";
CM_ SG_ 1155 IHU_setRsvTravelWeek "??????8??bit(TBOX????)
???¶À?????????????????????????? 1?????0?????!dou!????????0
?????¶À??????¶À???¶¡??????????
Bit 7 : ????????????????  1=?? 0=???
Bit 6 : 1=???? 0=??
Bit 5 : 1=???? 0=??
Bit 4 : 1=???? 0=??
Bit 3 : 1=???? 0=??
Bit 2 : 1=???? 0=??
Bit 1 : 1=??? 0=??
Bit 0 : 1=??? 0=??
?0????Not active!dou!??????????";
CM_ SG_ 1480 NextTrafficSts "????????¶≈?°§????????£∫
0x0:??°§???
0x1:?????????
0x2:?????????
0x3:?????ßπ";
CM_ SG_ 1480 TrafficSts "?????????°§????????£∫
0x0:??°§???
0x1:?????????
0x2:?????????
0x3:?????ßπ";
CM_ SG_ 1480 NavDistance "????????";
CM_ BO_ 1119 "??????????¶≤???3?¶≈???";
CM_ SG_ 1119 IHU_19_Set_HdrestSpkrMod "Set the headrest speaker mode using the host softkey
???????????????????????????????
0x0!mao!??????
0x1: ??????
0x2: ??????
0x3:?????
0x4:???
0x5:???
0x6:???
0x8:???";
CM_ SG_ 1119 IHU_19_Set_AMPESEVol "Volume
????,???31??0-31??";
CM_ SG_ 1119 IHU_19_Set_AMPWelVol "Welcome Volume
??????,???31??0-31??";
CM_ SG_ 1119 IHU_19_Set_AMPBTMediVol "Media Volume
e????????,???31??0-31??";
CM_ SG_ 1119 IHU_19_REQ_AMPA2BMediSound "Type of multimedia playback
??y?å˚???????";
CM_ SG_ 1119 IHU_19_PABSetCmd "IHU_19_PAB Set Command";
CM_ SG_ 1119 IHU_19_HwSet "Haptic Warning(HWA) /  ??????????";
CM_ SG_ 1119 IHU_19_BSRBPASet "Belt slack reduction(BSR) / ??????????
Belt parking assist(BPA) / ???????????";
CM_ SG_ 1119 REQ_AMPA2BVRSound "M32TFL2??????0x3?????0x1??VR?;????4.0?????0x3????¶À";
CM_ SG_ 1119 REQ_AMPA2BMediaSound "M1E??????????3.0EAMP?????4.0
???!dou!???????????!dou!????????M1E???????????";
CM_ SG_ 1119 Set_AMPMute "????????????????
????????????lin??????????DVD!dou!DVD???CAN????
????";
CM_ SG_ 1119 Set_AMPSpeedVolume "????????
????????????!mao!???!dun!??!dun!??!dun!??.
?????????????????!dou!??y???????Entertainment???????????????????????????????????????";
BA_DEF_ SG_  "GenSigTimeoutValue" INT 0 2147483647;
BA_DEF_ SG_  "GenSigStartValue" INT 0 2147483647;
BA_DEF_ SG_  "GenSigInactiveValue" INT 0 2147483647;
BA_DEF_ BO_  "TpTxIndex" INT 0 255;
BA_DEF_ BO_  "DiagUudtResponse" ENUM  "False","True";
BA_DEF_ BO_  "DiagResponse" ENUM  "No","Yes";
BA_DEF_ BO_  "DiagRequest" ENUM  "No","Yes";
BA_DEF_ BO_  "DiagState" ENUM  "No","Yes";
BA_DEF_ BO_  "NmAsrMessage" ENUM  "No","Yes";
BA_DEF_ BO_  "GenMsgFastOnStart" INT 0 65535;
BA_DEF_ BO_  "GenMsgCycleTimeFast" INT 0 65535;
BA_DEF_ BO_  "GenMsgNrOfRepetition" INT 0 65535;
BA_DEF_ BO_  "GenMsgStartDelayTime" INT 0 65535;
BA_DEF_ BO_  "GenMsgCycleTime" INT 0 65535;
BA_DEF_ BO_  "GenMsgDelayTime" INT 0 65535;
BA_DEF_ SG_  "GenSigSendType" ENUM  "Cyclic","OnWrite","OnWriteWithRepetition","OnChange","OnChangeWithRepetition","IfActive","IfActiveWithRepetition","NoSigSendType","OnChangeAndIfActive","OnChangeAndIfActiveWithRepetition";
BA_DEF_ BO_  "GenMsgSendType" ENUM  "Cyclic","NotUsed","NotUsed","NotUsed","NotUsed","NotUsed","NotUsed","IfActive","NoMsgSendType";
BA_DEF_ BO_  "GenMsgILSupport" ENUM  "No","Yes";
BA_DEF_REL_ BU_SG_REL_  "GenSigTimeoutTime" INT 0 65535;
BA_DEF_DEF_  "GenSigTimeoutValue" 0;
BA_DEF_DEF_  "GenSigStartValue" 0;
BA_DEF_DEF_  "GenSigInactiveValue" 0;
BA_DEF_DEF_  "TpTxIndex" 0;
BA_DEF_DEF_  "DiagUudtResponse" "False";
BA_DEF_DEF_  "DiagResponse" "No";
BA_DEF_DEF_  "DiagRequest" "No";
BA_DEF_DEF_  "DiagState" "No";
BA_DEF_DEF_  "NmAsrMessage" "No";
BA_DEF_DEF_  "GenMsgFastOnStart" 0;
BA_DEF_DEF_  "GenMsgCycleTimeFast" 0;
BA_DEF_DEF_  "GenMsgNrOfRepetition" 3;
BA_DEF_DEF_  "GenMsgStartDelayTime" 0;
BA_DEF_DEF_  "GenMsgCycleTime" 0;
BA_DEF_DEF_  "GenMsgDelayTime" 0;
BA_DEF_DEF_  "GenSigSendType" "NoSigSendType";
BA_DEF_DEF_  "GenMsgSendType" "NoMsgSendType";
BA_DEF_DEF_  "GenMsgILSupport" "No";
BA_DEF_DEF_REL_ "GenSigTimeoutTime" 0;
BA_ "GenMsgILSupport" BO_ 1050 1;
BA_ "GenMsgSendType" BO_ 1050 0;
BA_ "GenMsgNrOfRepetition" BO_ 1050 0;
BA_ "GenMsgCycleTime" BO_ 1050 100;
BA_ "GenMsgILSupport" BO_ 1267 1;
BA_ "GenMsgSendType" BO_ 1267 0;
BA_ "GenMsgNrOfRepetition" BO_ 1267 0;
BA_ "GenMsgCycleTime" BO_ 1267 100;
BA_ "GenMsgILSupport" BO_ 1265 1;
BA_ "GenMsgNrOfRepetition" BO_ 1265 0;
BA_ "GenMsgDelayTime" BO_ 1265 5;
BA_ "GenMsgILSupport" BO_ 704 1;
BA_ "GenMsgSendType" BO_ 704 0;
BA_ "GenMsgNrOfRepetition" BO_ 704 0;
BA_ "GenMsgCycleTime" BO_ 704 100;
BA_ "GenMsgILSupport" BO_ 932 1;
BA_ "GenMsgSendType" BO_ 932 0;
BA_ "GenMsgNrOfRepetition" BO_ 932 0;
BA_ "GenMsgCycleTime" BO_ 932 20;
BA_ "GenMsgILSupport" BO_ 931 1;
BA_ "GenMsgSendType" BO_ 931 0;
BA_ "GenMsgNrOfRepetition" BO_ 931 0;
BA_ "GenMsgCycleTime" BO_ 931 20;
BA_ "GenMsgILSupport" BO_ 793 1;
BA_ "GenMsgSendType" BO_ 793 0;
BA_ "GenMsgNrOfRepetition" BO_ 793 0;
BA_ "GenMsgCycleTime" BO_ 793 20;
BA_ "GenMsgILSupport" BO_ 787 1;
BA_ "GenMsgSendType" BO_ 787 0;
BA_ "GenMsgNrOfRepetition" BO_ 787 0;
BA_ "GenMsgCycleTime" BO_ 787 20;
BA_ "GenMsgILSupport" BO_ 800 1;
BA_ "GenMsgSendType" BO_ 800 0;
BA_ "GenMsgNrOfRepetition" BO_ 800 6;
BA_ "GenMsgDelayTime" BO_ 800 5;
BA_ "GenMsgCycleTimeFast" BO_ 800 20;
BA_ "GenMsgCycleTime" BO_ 800 500;
BA_ "GenMsgILSupport" BO_ 1338 1;
BA_ "GenMsgSendType" BO_ 1338 0;
BA_ "GenMsgNrOfRepetition" BO_ 1338 0;
BA_ "GenMsgCycleTime" BO_ 1338 500;
BA_ "GenMsgILSupport" BO_ 1250 1;
BA_ "GenMsgSendType" BO_ 1250 0;
BA_ "GenMsgNrOfRepetition" BO_ 1250 0;
BA_ "GenMsgCycleTime" BO_ 1250 100;
BA_ "GenMsgILSupport" BO_ 1509 1;
BA_ "GenMsgSendType" BO_ 1509 0;
BA_ "GenMsgNrOfRepetition" BO_ 1509 0;
BA_ "GenMsgCycleTime" BO_ 1509 100;
BA_ "DiagResponse" BO_ 1812 1;
BA_ "GenMsgNrOfRepetition" BO_ 1812 0;
BA_ "DiagRequest" BO_ 1796 1;
BA_ "GenMsgNrOfRepetition" BO_ 1796 0;
BA_ "DiagResponse" BO_ 1882 1;
BA_ "GenMsgNrOfRepetition" BO_ 1882 0;
BA_ "DiagRequest" BO_ 1866 1;
BA_ "GenMsgNrOfRepetition" BO_ 1866 0;
BA_ "DiagResponse" BO_ 1913 1;
BA_ "GenMsgNrOfRepetition" BO_ 1913 0;
BA_ "DiagResponse" BO_ 2041 1;
BA_ "GenMsgNrOfRepetition" BO_ 2041 0;
BA_ "DiagResponse" BO_ 2030 1;
BA_ "GenMsgNrOfRepetition" BO_ 2030 0;
BA_ "DiagResponse" BO_ 2029 1;
BA_ "GenMsgNrOfRepetition" BO_ 2029 0;
BA_ "DiagResponse" BO_ 1813 1;
BA_ "GenMsgNrOfRepetition" BO_ 1813 0;
BA_ "DiagResponse" BO_ 1819 1;
BA_ "GenMsgNrOfRepetition" BO_ 1819 0;
BA_ "DiagResponse" BO_ 2027 1;
BA_ "GenMsgNrOfRepetition" BO_ 2027 0;
BA_ "DiagResponse" BO_ 2025 1;
BA_ "GenMsgNrOfRepetition" BO_ 2025 0;
BA_ "DiagResponse" BO_ 2024 1;
BA_ "GenMsgNrOfRepetition" BO_ 2024 0;
BA_ "DiagResponse" BO_ 2014 1;
BA_ "GenMsgNrOfRepetition" BO_ 2014 0;
BA_ "DiagResponse" BO_ 2009 1;
BA_ "GenMsgNrOfRepetition" BO_ 2009 0;
BA_ "DiagResponse" BO_ 2008 1;
BA_ "GenMsgNrOfRepetition" BO_ 2008 0;
BA_ "DiagResponse" BO_ 2007 1;
BA_ "GenMsgNrOfRepetition" BO_ 2007 0;
BA_ "DiagResponse" BO_ 2006 1;
BA_ "GenMsgNrOfRepetition" BO_ 2006 0;
BA_ "DiagResponse" BO_ 1982 1;
BA_ "GenMsgNrOfRepetition" BO_ 1982 0;
BA_ "DiagResponse" BO_ 1981 1;
BA_ "GenMsgNrOfRepetition" BO_ 1981 0;
BA_ "DiagResponse" BO_ 1980 1;
BA_ "GenMsgNrOfRepetition" BO_ 1980 0;
BA_ "DiagResponse" BO_ 1979 1;
BA_ "GenMsgNrOfRepetition" BO_ 1979 0;
BA_ "DiagResponse" BO_ 1978 1;
BA_ "GenMsgNrOfRepetition" BO_ 1978 0;
BA_ "DiagResponse" BO_ 1977 1;
BA_ "GenMsgNrOfRepetition" BO_ 1977 0;
BA_ "DiagResponse" BO_ 1976 1;
BA_ "GenMsgNrOfRepetition" BO_ 1976 0;
BA_ "DiagResponse" BO_ 1975 1;
BA_ "GenMsgNrOfRepetition" BO_ 1975 0;
BA_ "DiagResponse" BO_ 1974 1;
BA_ "GenMsgNrOfRepetition" BO_ 1974 0;
BA_ "DiagResponse" BO_ 1951 1;
BA_ "GenMsgNrOfRepetition" BO_ 1951 0;
BA_ "DiagResponse" BO_ 1949 1;
BA_ "GenMsgNrOfRepetition" BO_ 1949 0;
BA_ "DiagResponse" BO_ 1946 1;
BA_ "GenMsgNrOfRepetition" BO_ 1946 0;
BA_ "DiagResponse" BO_ 1945 1;
BA_ "GenMsgNrOfRepetition" BO_ 1945 0;
BA_ "DiagResponse" BO_ 1938 1;
BA_ "GenMsgNrOfRepetition" BO_ 1938 0;
BA_ "DiagResponse" BO_ 1936 1;
BA_ "GenMsgNrOfRepetition" BO_ 1936 0;
BA_ "DiagResponse" BO_ 1919 1;
BA_ "GenMsgNrOfRepetition" BO_ 1919 0;
BA_ "DiagResponse" BO_ 1918 1;
BA_ "GenMsgNrOfRepetition" BO_ 1918 0;
BA_ "DiagResponse" BO_ 1917 1;
BA_ "GenMsgNrOfRepetition" BO_ 1917 0;
BA_ "DiagResponse" BO_ 1916 1;
BA_ "GenMsgNrOfRepetition" BO_ 1916 0;
BA_ "DiagResponse" BO_ 1910 1;
BA_ "GenMsgNrOfRepetition" BO_ 1910 0;
BA_ "DiagResponse" BO_ 1907 1;
BA_ "GenMsgNrOfRepetition" BO_ 1907 0;
BA_ "DiagResponse" BO_ 1906 1;
BA_ "GenMsgNrOfRepetition" BO_ 1906 0;
BA_ "DiagResponse" BO_ 1904 1;
BA_ "GenMsgNrOfRepetition" BO_ 1904 0;
BA_ "DiagResponse" BO_ 1885 1;
BA_ "GenMsgNrOfRepetition" BO_ 1885 0;
BA_ "DiagResponse" BO_ 1883 1;
BA_ "GenMsgNrOfRepetition" BO_ 1883 0;
BA_ "DiagResponse" BO_ 1880 1;
BA_ "GenMsgNrOfRepetition" BO_ 1880 0;
BA_ "DiagResponse" BO_ 1879 1;
BA_ "GenMsgNrOfRepetition" BO_ 1879 0;
BA_ "DiagResponse" BO_ 1878 1;
BA_ "GenMsgNrOfRepetition" BO_ 1878 0;
BA_ "DiagResponse" BO_ 1855 1;
BA_ "GenMsgNrOfRepetition" BO_ 1855 0;
BA_ "DiagResponse" BO_ 1854 1;
BA_ "GenMsgNrOfRepetition" BO_ 1854 0;
BA_ "DiagResponse" BO_ 1851 1;
BA_ "GenMsgNrOfRepetition" BO_ 1851 0;
BA_ "DiagResponse" BO_ 1848 1;
BA_ "GenMsgNrOfRepetition" BO_ 1848 0;
BA_ "DiagResponse" BO_ 1844 1;
BA_ "GenMsgNrOfRepetition" BO_ 1844 0;
BA_ "DiagResponse" BO_ 1840 1;
BA_ "GenMsgNrOfRepetition" BO_ 1840 0;
BA_ "DiagResponse" BO_ 1816 1;
BA_ "GenMsgNrOfRepetition" BO_ 1816 0;
BA_ "DiagResponse" BO_ 1841 1;
BA_ "GenMsgNrOfRepetition" BO_ 1841 0;
BA_ "DiagResponse" BO_ 1823 1;
BA_ "GenMsgNrOfRepetition" BO_ 1823 0;
BA_ "DiagResponse" BO_ 1811 1;
BA_ "GenMsgNrOfRepetition" BO_ 1811 0;
BA_ "DiagResponse" BO_ 1810 1;
BA_ "GenMsgNrOfRepetition" BO_ 1810 0;
BA_ "DiagResponse" BO_ 1809 1;
BA_ "GenMsgNrOfRepetition" BO_ 1809 0;
BA_ "DiagResponse" BO_ 1808 1;
BA_ "GenMsgNrOfRepetition" BO_ 1808 0;
BA_ "DiagResponse" BO_ 2005 1;
BA_ "GenMsgNrOfRepetition" BO_ 2005 0;
BA_ "DiagResponse" BO_ 1948 1;
BA_ "GenMsgNrOfRepetition" BO_ 1948 0;
BA_ "DiagResponse" BO_ 1874 1;
BA_ "GenMsgNrOfRepetition" BO_ 1874 0;
BA_ "DiagResponse" BO_ 1843 1;
BA_ "GenMsgNrOfRepetition" BO_ 1843 0;
BA_ "DiagResponse" BO_ 1905 1;
BA_ "GenMsgNrOfRepetition" BO_ 1905 0;
BA_ "DiagResponse" BO_ 2028 1;
BA_ "GenMsgNrOfRepetition" BO_ 2028 0;
BA_ "DiagResponse" BO_ 2026 1;
BA_ "GenMsgNrOfRepetition" BO_ 2026 0;
BA_ "DiagResponse" BO_ 1847 1;
BA_ "GenMsgNrOfRepetition" BO_ 1847 0;
BA_ "DiagResponse" BO_ 2004 1;
BA_ "GenMsgNrOfRepetition" BO_ 2004 0;
BA_ "DiagResponse" BO_ 2003 1;
BA_ "GenMsgNrOfRepetition" BO_ 2003 0;
BA_ "DiagResponse" BO_ 2002 1;
BA_ "GenMsgNrOfRepetition" BO_ 2002 0;
BA_ "DiagResponse" BO_ 2001 1;
BA_ "GenMsgNrOfRepetition" BO_ 2001 0;
BA_ "DiagResponse" BO_ 2000 1;
BA_ "GenMsgNrOfRepetition" BO_ 2000 0;
BA_ "DiagResponse" BO_ 1983 1;
BA_ "GenMsgNrOfRepetition" BO_ 1983 0;
BA_ "DiagRequest" BO_ 1897 1;
BA_ "GenMsgNrOfRepetition" BO_ 1897 0;
BA_ "DiagState" BO_ 1999 1;
BA_ "GenMsgNrOfRepetition" BO_ 1999 0;
BA_ "DiagRequest" BO_ 2033 1;
BA_ "GenMsgNrOfRepetition" BO_ 2033 0;
BA_ "DiagRequest" BO_ 1797 1;
BA_ "GenMsgNrOfRepetition" BO_ 1797 0;
BA_ "DiagRequest" BO_ 1803 1;
BA_ "GenMsgNrOfRepetition" BO_ 1803 0;
BA_ "DiagRequest" BO_ 2019 1;
BA_ "GenMsgNrOfRepetition" BO_ 2019 0;
BA_ "DiagRequest" BO_ 2017 1;
BA_ "GenMsgNrOfRepetition" BO_ 2017 0;
BA_ "DiagRequest" BO_ 2016 1;
BA_ "GenMsgNrOfRepetition" BO_ 2016 0;
BA_ "DiagRequest" BO_ 1998 1;
BA_ "GenMsgNrOfRepetition" BO_ 1998 0;
BA_ "DiagRequest" BO_ 1993 1;
BA_ "GenMsgNrOfRepetition" BO_ 1993 0;
BA_ "DiagRequest" BO_ 1992 1;
BA_ "GenMsgNrOfRepetition" BO_ 1992 0;
BA_ "DiagRequest" BO_ 1991 1;
BA_ "GenMsgNrOfRepetition" BO_ 1991 0;
BA_ "DiagRequest" BO_ 1990 1;
BA_ "GenMsgNrOfRepetition" BO_ 1990 0;
BA_ "DiagRequest" BO_ 1966 1;
BA_ "GenMsgNrOfRepetition" BO_ 1966 0;
BA_ "DiagRequest" BO_ 1965 1;
BA_ "GenMsgNrOfRepetition" BO_ 1965 0;
BA_ "DiagRequest" BO_ 1964 1;
BA_ "GenMsgNrOfRepetition" BO_ 1964 0;
BA_ "DiagRequest" BO_ 1963 1;
BA_ "GenMsgNrOfRepetition" BO_ 1963 0;
BA_ "DiagRequest" BO_ 1962 1;
BA_ "GenMsgNrOfRepetition" BO_ 1962 0;
BA_ "DiagRequest" BO_ 1961 1;
BA_ "GenMsgNrOfRepetition" BO_ 1961 0;
BA_ "DiagRequest" BO_ 1960 1;
BA_ "GenMsgNrOfRepetition" BO_ 1960 0;
BA_ "DiagRequest" BO_ 1959 1;
BA_ "GenMsgNrOfRepetition" BO_ 1959 0;
BA_ "DiagRequest" BO_ 1958 1;
BA_ "GenMsgNrOfRepetition" BO_ 1958 0;
BA_ "DiagResponse" BO_ 1943 1;
BA_ "GenMsgNrOfRepetition" BO_ 1943 0;
BA_ "DiagResponse" BO_ 1942 1;
BA_ "GenMsgNrOfRepetition" BO_ 1942 0;
BA_ "DiagResponse" BO_ 1941 1;
BA_ "GenMsgNrOfRepetition" BO_ 1941 0;
BA_ "DiagResponse" BO_ 1939 1;
BA_ "GenMsgNrOfRepetition" BO_ 1939 0;
BA_ "DiagRequest" BO_ 1935 1;
BA_ "GenMsgNrOfRepetition" BO_ 1935 0;
BA_ "DiagRequest" BO_ 1933 1;
BA_ "GenMsgNrOfRepetition" BO_ 1933 0;
BA_ "DiagRequest" BO_ 1930 1;
BA_ "GenMsgNrOfRepetition" BO_ 1930 0;
BA_ "DiagRequest" BO_ 1929 1;
BA_ "GenMsgNrOfRepetition" BO_ 1929 0;
BA_ "DiagRequest" BO_ 1927 1;
BA_ "GenMsgNrOfRepetition" BO_ 1927 0;
BA_ "DiagRequest" BO_ 1926 1;
BA_ "GenMsgNrOfRepetition" BO_ 1926 0;
BA_ "DiagRequest" BO_ 1925 1;
BA_ "GenMsgNrOfRepetition" BO_ 1925 0;
BA_ "DiagRequest" BO_ 1923 1;
BA_ "GenMsgNrOfRepetition" BO_ 1923 0;
BA_ "DiagRequest" BO_ 1922 1;
BA_ "GenMsgNrOfRepetition" BO_ 1922 0;
BA_ "DiagRequest" BO_ 1920 1;
BA_ "GenMsgNrOfRepetition" BO_ 1920 0;
BA_ "DiagRequest" BO_ 1903 1;
BA_ "GenMsgNrOfRepetition" BO_ 1903 0;
BA_ "DiagRequest" BO_ 1902 1;
BA_ "GenMsgNrOfRepetition" BO_ 1902 0;
BA_ "DiagRequest" BO_ 1901 1;
BA_ "GenMsgNrOfRepetition" BO_ 1901 0;
BA_ "DiagRequest" BO_ 1900 1;
BA_ "GenMsgNrOfRepetition" BO_ 1900 0;
BA_ "DiagRequest" BO_ 1894 1;
BA_ "GenMsgNrOfRepetition" BO_ 1894 0;
BA_ "DiagRequest" BO_ 1891 1;
BA_ "GenMsgNrOfRepetition" BO_ 1891 0;
BA_ "DiagRequest" BO_ 1890 1;
BA_ "GenMsgNrOfRepetition" BO_ 1890 0;
BA_ "DiagRequest" BO_ 1888 1;
BA_ "GenMsgNrOfRepetition" BO_ 1888 0;
BA_ "DiagRequest" BO_ 1869 1;
BA_ "GenMsgNrOfRepetition" BO_ 1869 0;
BA_ "DiagRequest" BO_ 1867 1;
BA_ "GenMsgNrOfRepetition" BO_ 1867 0;
BA_ "DiagRequest" BO_ 1864 1;
BA_ "GenMsgNrOfRepetition" BO_ 1864 0;
BA_ "DiagRequest" BO_ 1863 1;
BA_ "GenMsgNrOfRepetition" BO_ 1863 0;
BA_ "DiagRequest" BO_ 1862 1;
BA_ "GenMsgNrOfRepetition" BO_ 1862 0;
BA_ "DiagRequest" BO_ 1839 1;
BA_ "GenMsgNrOfRepetition" BO_ 1839 0;
BA_ "DiagRequest" BO_ 1838 1;
BA_ "GenMsgNrOfRepetition" BO_ 1838 0;
BA_ "DiagRequest" BO_ 1835 1;
BA_ "GenMsgNrOfRepetition" BO_ 1835 0;
BA_ "DiagRequest" BO_ 1832 1;
BA_ "GenMsgNrOfRepetition" BO_ 1832 0;
BA_ "DiagRequest" BO_ 1828 1;
BA_ "GenMsgNrOfRepetition" BO_ 1828 0;
BA_ "DiagRequest" BO_ 1824 1;
BA_ "GenMsgNrOfRepetition" BO_ 1824 0;
BA_ "DiagRequest" BO_ 1800 1;
BA_ "GenMsgNrOfRepetition" BO_ 1800 0;
BA_ "DiagRequest" BO_ 1825 1;
BA_ "GenMsgNrOfRepetition" BO_ 1825 0;
BA_ "DiagRequest" BO_ 1807 1;
BA_ "GenMsgNrOfRepetition" BO_ 1807 0;
BA_ "DiagRequest" BO_ 1795 1;
BA_ "GenMsgNrOfRepetition" BO_ 1795 0;
BA_ "DiagRequest" BO_ 1794 1;
BA_ "GenMsgNrOfRepetition" BO_ 1794 0;
BA_ "DiagRequest" BO_ 1793 1;
BA_ "GenMsgNrOfRepetition" BO_ 1793 0;
BA_ "DiagRequest" BO_ 1792 1;
BA_ "GenMsgNrOfRepetition" BO_ 1792 0;
BA_ "DiagRequest" BO_ 1989 1;
BA_ "GenMsgNrOfRepetition" BO_ 1989 0;
BA_ "DiagRequest" BO_ 1932 1;
BA_ "GenMsgNrOfRepetition" BO_ 1932 0;
BA_ "DiagRequest" BO_ 1858 1;
BA_ "GenMsgNrOfRepetition" BO_ 1858 0;
BA_ "DiagRequest" BO_ 1827 1;
BA_ "GenMsgNrOfRepetition" BO_ 1827 0;
BA_ "DiagRequest" BO_ 1889 1;
BA_ "GenMsgNrOfRepetition" BO_ 1889 0;
BA_ "DiagRequest" BO_ 2020 1;
BA_ "GenMsgNrOfRepetition" BO_ 2020 0;
BA_ "DiagRequest" BO_ 2022 1;
BA_ "GenMsgNrOfRepetition" BO_ 2022 0;
BA_ "DiagRequest" BO_ 2021 1;
BA_ "GenMsgNrOfRepetition" BO_ 2021 0;
BA_ "DiagRequest" BO_ 2018 1;
BA_ "GenMsgNrOfRepetition" BO_ 2018 0;
BA_ "DiagRequest" BO_ 1831 1;
BA_ "GenMsgNrOfRepetition" BO_ 1831 0;
BA_ "DiagRequest" BO_ 1988 1;
BA_ "GenMsgNrOfRepetition" BO_ 1988 0;
BA_ "DiagRequest" BO_ 1987 1;
BA_ "GenMsgNrOfRepetition" BO_ 1987 0;
BA_ "DiagRequest" BO_ 1986 1;
BA_ "GenMsgNrOfRepetition" BO_ 1986 0;
BA_ "DiagRequest" BO_ 1985 1;
BA_ "GenMsgNrOfRepetition" BO_ 1985 0;
BA_ "DiagRequest" BO_ 1984 1;
BA_ "GenMsgNrOfRepetition" BO_ 1984 0;
BA_ "DiagRequest" BO_ 1967 1;
BA_ "GenMsgNrOfRepetition" BO_ 1967 0;
BA_ "NmAsrMessage" BO_ 1560 1;
BA_ "GenMsgSendType" BO_ 1560 0;
BA_ "GenMsgNrOfRepetition" BO_ 1560 0;
BA_ "GenMsgCycleTime" BO_ 1560 1000;
BA_ "GenMsgILSupport" BO_ 1266 1;
BA_ "GenMsgDelayTime" BO_ 1266 5;
BA_ "GenMsgCycleTimeFast" BO_ 1266 100;
BA_ "GenMsgILSupport" BO_ 1312 1;
BA_ "GenMsgSendType" BO_ 1312 0;
BA_ "GenMsgNrOfRepetition" BO_ 1312 0;
BA_ "GenMsgCycleTime" BO_ 1312 50;
BA_ "GenMsgILSupport" BO_ 1243 1;
BA_ "GenMsgSendType" BO_ 1243 0;
BA_ "GenMsgNrOfRepetition" BO_ 1243 0;
BA_ "GenMsgCycleTime" BO_ 1243 100;
BA_ "GenMsgILSupport" BO_ 1140 1;
BA_ "GenMsgSendType" BO_ 1140 0;
BA_ "GenMsgNrOfRepetition" BO_ 1140 0;
BA_ "GenMsgCycleTime" BO_ 1140 100;
BA_ "GenMsgILSupport" BO_ 1121 1;
BA_ "GenMsgSendType" BO_ 1121 0;
BA_ "GenMsgNrOfRepetition" BO_ 1121 0;
BA_ "GenMsgCycleTime" BO_ 1121 100;
BA_ "GenMsgILSupport" BO_ 1517 1;
BA_ "GenMsgNrOfRepetition" BO_ 1517 0;
BA_ "GenMsgILSupport" BO_ 1515 1;
BA_ "GenMsgNrOfRepetition" BO_ 1515 0;
BA_ "GenMsgILSupport" BO_ 1298 1;
BA_ "GenMsgNrOfRepetition" BO_ 1298 0;
BA_ "GenMsgILSupport" BO_ 1289 1;
BA_ "GenMsgNrOfRepetition" BO_ 1289 0;
BA_ "GenMsgILSupport" BO_ 759 1;
BA_ "GenMsgNrOfRepetition" BO_ 759 0;
BA_ "GenMsgILSupport" BO_ 755 1;
BA_ "GenMsgNrOfRepetition" BO_ 755 0;
BA_ "GenMsgILSupport" BO_ 1151 1;
BA_ "GenMsgNrOfRepetition" BO_ 1151 0;
BA_ "GenMsgDelayTime" BO_ 1151 5;
BA_ "GenMsgILSupport" BO_ 1116 1;
BA_ "GenMsgNrOfRepetition" BO_ 1116 0;
BA_ "GenMsgILSupport" BO_ 1242 1;
BA_ "GenMsgSendType" BO_ 1242 0;
BA_ "GenMsgNrOfRepetition" BO_ 1242 0;
BA_ "GenMsgCycleTime" BO_ 1242 50;
BA_ "GenMsgILSupport" BO_ 856 1;
BA_ "GenMsgSendType" BO_ 856 0;
BA_ "GenMsgNrOfRepetition" BO_ 856 0;
BA_ "GenMsgCycleTime" BO_ 856 50;
BA_ "GenMsgILSupport" BO_ 1150 1;
BA_ "GenMsgSendType" BO_ 1150 0;
BA_ "GenMsgNrOfRepetition" BO_ 1150 0;
BA_ "GenMsgCycleTime" BO_ 1150 100;
BA_ "GenMsgILSupport" BO_ 1120 1;
BA_ "GenMsgSendType" BO_ 1120 0;
BA_ "GenMsgNrOfRepetition" BO_ 1120 0;
BA_ "GenMsgCycleTime" BO_ 1120 100;
BA_ "GenMsgILSupport" BO_ 1092 1;
BA_ "GenMsgSendType" BO_ 1092 0;
BA_ "GenMsgNrOfRepetition" BO_ 1092 0;
BA_ "GenMsgCycleTime" BO_ 1092 100;
BA_ "GenMsgILSupport" BO_ 1330 1;
BA_ "GenMsgDelayTime" BO_ 1330 5;
BA_ "GenMsgCycleTimeFast" BO_ 1330 100;
BA_ "GenMsgILSupport" BO_ 1406 1;
BA_ "GenMsgSendType" BO_ 1406 0;
BA_ "GenMsgNrOfRepetition" BO_ 1406 0;
BA_ "GenMsgCycleTime" BO_ 1406 100;
BA_ "GenMsgILSupport" BO_ 1293 1;
BA_ "GenMsgSendType" BO_ 1293 0;
BA_ "GenMsgNrOfRepetition" BO_ 1293 0;
BA_ "GenMsgCycleTime" BO_ 1293 100;
BA_ "GenMsgILSupport" BO_ 1177 1;
BA_ "GenMsgDelayTime" BO_ 1177 5;
BA_ "GenMsgCycleTimeFast" BO_ 1177 100;
BA_ "GenMsgILSupport" BO_ 643 1;
BA_ "GenMsgSendType" BO_ 643 0;
BA_ "GenMsgNrOfRepetition" BO_ 643 0;
BA_ "GenMsgCycleTime" BO_ 643 20;
BA_ "GenMsgILSupport" BO_ 1244 1;
BA_ "GenMsgDelayTime" BO_ 1244 5;
BA_ "GenMsgCycleTimeFast" BO_ 1244 100;
BA_ "GenMsgILSupport" BO_ 1035 1;
BA_ "GenMsgSendType" BO_ 1035 0;
BA_ "GenMsgNrOfRepetition" BO_ 1035 0;
BA_ "GenMsgCycleTime" BO_ 1035 100;
BA_ "GenMsgILSupport" BO_ 1278 1;
BA_ "GenMsgDelayTime" BO_ 1278 5;
BA_ "GenMsgCycleTimeFast" BO_ 1278 100;
BA_ "GenMsgILSupport" BO_ 1155 1;
BA_ "GenMsgDelayTime" BO_ 1155 5;
BA_ "GenMsgCycleTimeFast" BO_ 1155 100;
BA_ "GenMsgILSupport" BO_ 1480 1;
BA_ "GenMsgSendType" BO_ 1480 0;
BA_ "GenMsgNrOfRepetition" BO_ 1480 0;
BA_ "GenMsgCycleTime" BO_ 1480 1000;
BA_ "GenMsgILSupport" BO_ 1119 1;
BA_ "GenMsgDelayTime" BO_ 1119 5;
BA_ "GenMsgCycleTimeFast" BO_ 1119 100;
BA_ "GenSigSendType" SG_ 1050 HPA_Subscribe_Status 0;
BA_ "GenSigSendType" SG_ 1050 HPA_IHU_Audio_HPA_status 0;
BA_ "GenSigSendType" SG_ 1050 FaultStatusCameraDVR 0;
BA_ "GenSigSendType" SG_ 1050 REQ_AVMDisp_1 0;
BA_ "GenSigSendType" SG_ 1050 PDC_fault_status 0;
BA_ "GenSigSendType" SG_ 1050 APA_fault_status 0;
BA_ "GenSigSendType" SG_ 1050 FAPASet_Feedback 0;
BA_ "GenSigSendType" SG_ 1050 HPASubStsFeedback 0;
BA_ "GenSigSendType" SG_ 1050 UndoSet_Feedback 0;
BA_ "GenSigSendType" SG_ 1050 Undo_fault_status 0;
BA_ "GenSigSendType" SG_ 1050 PDCmute_Set_Feedback 0;
BA_ "GenSigSendType" SG_ 1050 MOD_WorkSts 0;
BA_ "GenSigSendType" SG_ 1050 STAT_BSV_status 0;
BA_ "GenSigSendType" SG_ 1050 HPAMode 0;
BA_ "GenSigSendType" SG_ 1050 HPAActive 0;
BA_ "GenSigSendType" SG_ 1050 HPA_IHU_Audio_Park_Tips_1 0;
BA_ "GenSigSendType" SG_ 1050 HPA_IHU_Audio_Learn_Tips_1 0;
BA_ "GenSigSendType" SG_ 1050 HPA_IHU_Audio_Park_Tips 0;
BA_ "GenSigSendType" SG_ 1050 HPA_IHU_Audio_Learn_Tips 0;
BA_ "GenSigSendType" SG_ 1050 HPA_Exam_status 0;
BA_ "GenSigSendType" SG_ 1050 REQ_BSVDisp 0;
BA_ "GenSigSendType" SG_ 1050 MEBSet_Feedback 0;
BA_ "GenSigSendType" SG_ 1050 AVM_FactoryMode 0;
BA_ "GenSigSendType" SG_ 1050 AVMFeedbackSts_RemoteMode 0;
BA_ "GenSigSendType" SG_ 1050 AVM_3_IHUTTSExtend 0;
BA_ "GenSigSendType" SG_ 1050 AVM_3_IHUTTS 0;
BA_ "GenSigSendType" SG_ 1050 AVMDisplaySts 0;
BA_ "GenSigSendType" SG_ 1267 AIPM_2_DriveModeSet 0;
BA_ "GenSigSendType" SG_ 1265 PanelKeyVoiceRemindReq 1;
BA_ "GenSigSendType" SG_ 704 CDPFailSts 0;
BA_ "GenSigSendType" SG_ 704 AVHFailSts 0;
BA_ "GenSigSendType" SG_ 704 AVHSts 0;
BA_ "GenSigSendType" SG_ 704 HDCFailSts 0;
BA_ "GenSigSendType" SG_ 704 DiagnosticSessionSts 0;
BA_ "GenSigSendType" SG_ 704 CDPActive 0;
BA_ "GenSigSendType" SG_ 704 HHCFailSts 0;
BA_ "GenSigSendType" SG_ 704 VDCActive 0;
BA_ "GenSigSendType" SG_ 704 TCSActive 0;
BA_ "GenSigSendType" SG_ 704 VDCFailSts 0;
BA_ "GenSigSendType" SG_ 704 TCSFailSts 0;
BA_ "GenSigSendType" SG_ 704 EBDFailSts 0;
BA_ "GenSigSendType" SG_ 704 ABSFailSts 0;
BA_ "GenSigSendType" SG_ 704 AVHWarningMessage 0;
BA_ "GenSigSendType" SG_ 704 ABS_ESP_Checksum 0;
BA_ "GenSigSendType" SG_ 704 HDCCtrlSts 0;
BA_ "GenSigSendType" SG_ 704 ABS_ESP_MessageCounter 0;
BA_ "GenSigSendType" SG_ 704 VehicleSpeedVSOSigValidData 0;
BA_ "GenSigStartValue" SG_ 704 VehicleSpeedVSOSigValidData 1;
BA_ "GenSigSendType" SG_ 704 VehicleSpeedVSOSig 0;
BA_ "GenSigSendType" SG_ 704 ESPSwitchStatus 0;
BA_ "GenSigSendType" SG_ 932 ABSESP_8_Checksum 0;
BA_ "GenSigSendType" SG_ 932 ABSESP_8_MessageCounter 0;
BA_ "GenSigSendType" SG_ 932 RHRWheelSpeedRawValidData 0;
BA_ "GenSigStartValue" SG_ 932 RHRWheelSpeedRawValidData 1;
BA_ "GenSigSendType" SG_ 932 RHRWheelDriveDirection 0;
BA_ "GenSigSendType" SG_ 932 RHRWheelSpeedRaw 0;
BA_ "GenSigSendType" SG_ 932 LHRWheelSpeedRawValidData 0;
BA_ "GenSigStartValue" SG_ 932 LHRWheelSpeedRawValidData 1;
BA_ "GenSigSendType" SG_ 932 LHRWheelDriveDirection 0;
BA_ "GenSigSendType" SG_ 932 LHRWheelSpeedRaw 0;
BA_ "GenSigSendType" SG_ 931 ABSESP_7_Checksum 0;
BA_ "GenSigSendType" SG_ 931 ABSESP_7_MessageCounter 0;
BA_ "GenSigSendType" SG_ 931 RHFWheelSpeedRawValidData 0;
BA_ "GenSigStartValue" SG_ 931 RHFWheelSpeedRawValidData 1;
BA_ "GenSigSendType" SG_ 931 RHFWheelDriveDirection 0;
BA_ "GenSigSendType" SG_ 931 RHFWheelSpeedRaw 0;
BA_ "GenSigSendType" SG_ 931 LHFWheelSpeedRawValidData 0;
BA_ "GenSigStartValue" SG_ 931 LHFWheelSpeedRawValidData 1;
BA_ "GenSigSendType" SG_ 931 LHFWheelDriveDirection 0;
BA_ "GenSigSendType" SG_ 931 LHFWheelSpeedRaw 0;
BA_ "GenSigSendType" SG_ 793 LHFPulseCounter 0;
BA_ "GenSigSendType" SG_ 793 RHFPulseCounter 0;
BA_ "GenSigSendType" SG_ 793 RHRPulseCounterFailSts 0;
BA_ "GenSigSendType" SG_ 793 RHRPulseCounter 0;
BA_ "GenSigSendType" SG_ 793 LHFPulseCounterFailSts 0;
BA_ "GenSigSendType" SG_ 793 RHFPulseCounterFailSts 0;
BA_ "GenSigSendType" SG_ 793 LHRPulseCounterFailSts 0;
BA_ "GenSigSendType" SG_ 793 LHRPulseCounter 0;
BA_ "GenSigSendType" SG_ 787 ABS_ESP_3_AVHSts 0;
BA_ "GenSigSendType" SG_ 787 ABS_ESP_3_AVHFailSts 0;
BA_ "GenSigSendType" SG_ 800 ABM_1_MessageCounter 0;
BA_ "GenSigSendType" SG_ 800 SecRowRBeltWarning 0;
BA_ "GenSigSendType" SG_ 800 SecRowMBeltWarning 0;
BA_ "GenSigSendType" SG_ 800 SecRowLBeltWarning 0;
BA_ "GenSigSendType" SG_ 800 ThdRowRBeltWarning 0;
BA_ "GenSigSendType" SG_ 800 ThdRowLBeltWarning 0;
BA_ "GenSigSendType" SG_ 800 PsngrSeatBeltWarning 0;
BA_ "GenSigSendType" SG_ 800 AirBagFailSts 0;
BA_ "GenSigStartValue" SG_ 800 AirBagFailSts 3;
BA_ "GenSigSendType" SG_ 800 ABM_1_PABSetSts 0;
BA_ "GenSigStartValue" SG_ 800 ABM_1_PABSetSts 1;
BA_ "GenSigSendType" SG_ 1338 TMF_SpdAct 0;
BA_ "GenSigStartValue" SG_ 1338 TMF_SpdAct 32767;
BA_ "GenSigSendType" SG_ 1250 BMS_34_ValidData 0;
BA_ "GenSigSendType" SG_ 1250 BMS_LeftDCChargeTime 0;
BA_ "GenSigStartValue" SG_ 1250 BMS_LeftDCChargeTime 1022;
BA_ "GenSigSendType" SG_ 1250 EVCC_2_ValidData 0;
BA_ "GenSigSendType" SG_ 1250 EVCC_ElectronicLockSts 0;
BA_ "GenSigSendType" SG_ 1509 TCU_5_ValidData 0;
BA_ "GenSigSendType" SG_ 1509 EngWhlTrqRatio 0;
BA_ "GenSigSendType" SG_ 1509 HCU_EMS_3_ValidData 0;
BA_ "GenSigSendType" SG_ 1509 MeanEffectiveTorque 0;
BA_ "GenSigSendType" SG_ 1509 AWD_1_ValidData 0;
BA_ "GenSigSendType" SG_ 1509 EstimatedCouplingTorq 0;
BA_ "GenSigSendType" SG_ 1812 DMC_BCM_RLS_RES 1;
BA_ "GenSigSendType" SG_ 1796 DMC_BCM_RLS_REQ 1;
BA_ "GenSigSendType" SG_ 1882 TBOX_IHU_RES 1;
BA_ "GenSigSendType" SG_ 1866 TBOX_IHU_REQ 1;
BA_ "GenSigSendType" SG_ 1913 DMC_BCM_EBS_RES 1;
BA_ "GenSigSendType" SG_ 2041 DMC_ACU_RES_EDR 1;
BA_ "GenSigSendType" SG_ 2030 DMC_DCDC_RES 1;
BA_ "GenSigSendType" SG_ 2029 DMC_BMS_RES 1;
BA_ "GenSigSendType" SG_ 1813 DMC_EVCC_RES 1;
BA_ "GenSigSendType" SG_ 1819 DMC_ISGF_RES 1;
BA_ "GenSigSendType" SG_ 2027 DMC_BSG1_RES 1;
BA_ "GenSigSendType" SG_ 2025 DMC_OBD_RESP_TCU 1;
BA_ "GenSigSendType" SG_ 2024 DMC_OBD_EMS_RES 1;
BA_ "GenSigSendType" SG_ 2014 DMC_SHU3L_RES 1;
BA_ "GenSigSendType" SG_ 2009 DMC_SHU2R_RES 1;
BA_ "GenSigSendType" SG_ 2008 DMC_SHU2M_RES 1;
BA_ "GenSigSendType" SG_ 2007 DMC_SHU2L_RES 1;
BA_ "GenSigSendType" SG_ 2006 DMC_SHU3R_RES 1;
BA_ "GenSigSendType" SG_ 1982 DMC_SRFR_RES 1;
BA_ "GenSigSendType" SG_ 1981 DMC_SRFG_RES 1;
BA_ "GenSigSendType" SG_ 1980 DMC_SAUR_RES 1;
BA_ "GenSigSendType" SG_ 1979 DMC_RRPLM_RES 1;
BA_ "GenSigSendType" SG_ 1978 DMC_RRFLM_RES 1;
BA_ "GenSigSendType" SG_ 1977 DMC_RLPLM_RES 1;
BA_ "GenSigSendType" SG_ 1976 DMC_RLFLM_RES 1;
BA_ "GenSigSendType" SG_ 1975 DMC_SAUP_RES 1;
BA_ "GenSigSendType" SG_ 1974 DMC_SHU1P_RES 1;
BA_ "GenSigSendType" SG_ 1951 DMC_SAUD_RES 1;
BA_ "GenSigSendType" SG_ 1949 DMC_NFC_RES 1;
BA_ "GenSigSendType" SG_ 1946 DMC__AIPMR_RES 1;
BA_ "GenSigSendType" SG_ 1945 DMC__AIPM_RES 1;
BA_ "GenSigSendType" SG_ 1938 DMC_SHU1D_RES 1;
BA_ "GenSigSendType" SG_ 1936 DMC_SCU_RES 1;
BA_ "GenSigSendType" SG_ 1919 DMC_RHM_RES 1;
BA_ "GenSigSendType" SG_ 1918 DMC_LHM_RES 1;
BA_ "GenSigSendType" SG_ 1917 DMC_ESCL_RES 1;
BA_ "GenSigSendType" SG_ 1916 DMC_PLG_RES 1;
BA_ "GenSigSendType" SG_ 1910 DMC_AVM_RES 1;
BA_ "GenSigSendType" SG_ 1907 DMC_RADAR_RES 1;
BA_ "GenSigSendType" SG_ 1906 DMC_CGW_RES 1;
BA_ "GenSigSendType" SG_ 1904 DMC_BDM_RES 1;
BA_ "GenSigSendType" SG_ 1885 DMC_IMMO_RES 1;
BA_ "GenSigSendType" SG_ 1883 DMC_CLM_RES 1;
BA_ "GenSigSendType" SG_ 1880 DMC_DBL_RES 1;
BA_ "GenSigSendType" SG_ 1879 DMC_ICM_RES 1;
BA_ "GenSigSendType" SG_ 1878 DMC_ACU_RES 1;
BA_ "GenSigSendType" SG_ 1855 DMC_FRM_RES 1;
BA_ "GenSigSendType" SG_ 1854 DMC_FCM_RES 1;
BA_ "GenSigSendType" SG_ 1851 DMC_EGS_RES 1;
BA_ "GenSigSendType" SG_ 1848 DMC_TPMS_RES 1;
BA_ "GenSigSendType" SG_ 1844 DMC_EPS_RES 1;
BA_ "GenSigSendType" SG_ 1840 DMC_ESP_RES 1;
BA_ "GenSigSendType" SG_ 1816 DIAG_EPB_RES 1;
BA_ "GenSigSendType" SG_ 1841 DIAG_EPB_RES 1;
BA_ "GenSigSendType" SG_ 1823 DMC_GSI_RES 1;
BA_ "GenSigSendType" SG_ 1811 DMC_TCU_RES 1;
BA_ "GenSigSendType" SG_ 1810 DMC_AWD_RES 1;
BA_ "GenSigSendType" SG_ 1809 DMC_FPC_RES 1;
BA_ "GenSigSendType" SG_ 1808 DMC_EMS_RES 1;
BA_ "GenSigSendType" SG_ 2005 DMC_CVBOX_RES 1;
BA_ "GenSigSendType" SG_ 1948 DMC_HUD_RES 1;
BA_ "GenSigSendType" SG_ 1874 DMC_DCM_RES 1;
BA_ "GenSigSendType" SG_ 1843 DMC_PPMI_RES 1;
BA_ "GenSigSendType" SG_ 1905 DMC_SAM_RES 1;
BA_ "GenSigSendType" SG_ 2028 DMC_MCUR_RES 1;
BA_ "GenSigSendType" SG_ 2026 DMC_HCU_RES 1;
BA_ "GenSigSendType" SG_ 1847 DMC_ASU_RES 1;
BA_ "GenSigSendType" SG_ 2004 DMC_RRCR_RES 1;
BA_ "GenSigSendType" SG_ 2003 DMC_RLCR_RES 1;
BA_ "GenSigSendType" SG_ 2002 DMC_FRCR_RES 1;
BA_ "GenSigSendType" SG_ 2001 DMC_FLCR_RES 1;
BA_ "GenSigSendType" SG_ 2000 DMC_IDCU_RES 1;
BA_ "GenSigSendType" SG_ 1983 DMC_CIR_RES 1;
BA_ "GenSigSendType" SG_ 1897 DMC_BCM_EBS_REQ 1;
BA_ "GenSigSendType" SG_ 1999 DMC_REQ_Broadcast 1;
BA_ "GenSigSendType" SG_ 2033 DMC_ACU_REQ_EDR 1;
BA_ "GenSigSendType" SG_ 1797 DMC_OBD_REQ_EVCC 1;
BA_ "GenSigSendType" SG_ 1803 DMC_ISGF_REQ 1;
BA_ "GenSigSendType" SG_ 2019 DMC_BSG1_REQ 1;
BA_ "GenSigSendType" SG_ 2017 DMC_OBD_REQ_TCU 1;
BA_ "GenSigSendType" SG_ 2016 DMC_OBD_EMS_REQ 1;
BA_ "GenSigSendType" SG_ 1998 DMC_SHU3L_REQ 1;
BA_ "GenSigSendType" SG_ 1993 DMC_SHU2R_REQ 1;
BA_ "GenSigSendType" SG_ 1992 DMC_SHU2M_REQ 1;
BA_ "GenSigSendType" SG_ 1991 DMC_SHU2L_REQ 1;
BA_ "GenSigSendType" SG_ 1990 DMC_SHU3R_REQ 1;
BA_ "GenSigSendType" SG_ 1966 DMC_SRFR_REQ 1;
BA_ "GenSigSendType" SG_ 1965 DMC_SRFG_REQ 1;
BA_ "GenSigSendType" SG_ 1964 DMC_SAUR_REQ 1;
BA_ "GenSigSendType" SG_ 1963 DMC_RRPLM_REQ 1;
BA_ "GenSigSendType" SG_ 1962 DMC_RRFLM_REQ 1;
BA_ "GenSigSendType" SG_ 1961 DMC_RLPLM_REQ 1;
BA_ "GenSigSendType" SG_ 1960 DMC_RLFLM_REQ 1;
BA_ "GenSigSendType" SG_ 1959 DMC_SAUP_REQ 1;
BA_ "GenSigSendType" SG_ 1958 DMC_SHU1P_REQ 1;
BA_ "GenSigSendType" SG_ 1943 DMC_EAMP_RES 1;
BA_ "GenSigSendType" SG_ 1942 DMC__ACP_RES 1;
BA_ "GenSigSendType" SG_ 1941 DMC_DVR_RES 1;
BA_ "GenSigSendType" SG_ 1939 DMC_CWC_RES 1;
BA_ "GenSigSendType" SG_ 1935 DMC_SAUD_REQ 1;
BA_ "GenSigSendType" SG_ 1933 DMC_NFC_REQ 1;
BA_ "GenSigSendType" SG_ 1930 DMC_AIPMR_REQ 1;
BA_ "GenSigSendType" SG_ 1929 DMC_AIPM_REQ 1;
BA_ "GenSigSendType" SG_ 1927 DMC_EAMP_REQ 1;
BA_ "GenSigSendType" SG_ 1926 DMC__ACP_REQ 1;
BA_ "GenSigSendType" SG_ 1925 DMC_DVR_REQ 1;
BA_ "GenSigSendType" SG_ 1923 DMC_CWC_REQ 1;
BA_ "GenSigSendType" SG_ 1922 DMC_SHU1D_REQ 1;
BA_ "GenSigSendType" SG_ 1920 DMC_SCU_REQ 1;
BA_ "GenSigSendType" SG_ 1903 DMC_RHM_REQ 1;
BA_ "GenSigSendType" SG_ 1902 DMC_LHM_REQ 1;
BA_ "GenSigSendType" SG_ 1901 DMC_ESCL_REQ 1;
BA_ "GenSigSendType" SG_ 1900 DMC_PLG_REQ 1;
BA_ "GenSigSendType" SG_ 1894 DMC_AVM_REQ 1;
BA_ "GenSigSendType" SG_ 1891 DMC_RADAR_REQ 1;
BA_ "GenSigSendType" SG_ 1890 DMC_CGW_REQ 1;
BA_ "GenSigSendType" SG_ 1888 DMC_BDM_REQ 1;
BA_ "GenSigSendType" SG_ 1869 DMC_IMMO_REQ 1;
BA_ "GenSigSendType" SG_ 1867 DMC_CLM_REQ 1;
BA_ "GenSigSendType" SG_ 1864 DMC_DBL_REQ 1;
BA_ "GenSigSendType" SG_ 1863 DMC_ICM_REQ 1;
BA_ "GenSigSendType" SG_ 1862 DMC_ACU_REQ 1;
BA_ "GenSigSendType" SG_ 1839 DMC_FRM_REQ 1;
BA_ "GenSigSendType" SG_ 1838 DMC_FCM_REQ 1;
BA_ "GenSigSendType" SG_ 1835 DMC_EGS_REQ 1;
BA_ "GenSigSendType" SG_ 1832 DMC_TPMS_REQ 1;
BA_ "GenSigSendType" SG_ 1828 DMC_EPS_REQ 1;
BA_ "GenSigSendType" SG_ 1824 DMC_ESP_REQ 1;
BA_ "GenSigSendType" SG_ 1800 DIAG_EPB_REQ 1;
BA_ "GenSigSendType" SG_ 1825 DIAG_EPB_REQ 1;
BA_ "GenSigSendType" SG_ 1807 DMC_GSI_REQ 1;
BA_ "GenSigSendType" SG_ 1795 DMC_TCU_REQ 1;
BA_ "GenSigSendType" SG_ 1794 DMC_AWD_REQ 1;
BA_ "GenSigSendType" SG_ 1793 DMC_FPC_REQ 1;
BA_ "GenSigSendType" SG_ 1792 DMC_EMS_REQ 1;
BA_ "GenSigSendType" SG_ 1989 DMC_CVBOX_REQ 1;
BA_ "GenSigSendType" SG_ 1932 DMC_HUD_REQ 1;
BA_ "GenSigSendType" SG_ 1858 DMC_DCM_REQ 1;
BA_ "GenSigSendType" SG_ 1827 DMC_PPMI_REQ 1;
BA_ "GenSigSendType" SG_ 1889 DMC_SAM_REQ 1;
BA_ "GenSigSendType" SG_ 2020 DMC_MCUR_REQ 1;
BA_ "GenSigSendType" SG_ 2022 DMC_DCDC_REQ 1;
BA_ "GenSigSendType" SG_ 2021 DMC_BMS_REQ 1;
BA_ "GenSigSendType" SG_ 2018 DMC_HCU_REQ 1;
BA_ "GenSigSendType" SG_ 1831 DMC_ASU_REQ 1;
BA_ "GenSigSendType" SG_ 1988 DMC_RRCR_REQ 1;
BA_ "GenSigSendType" SG_ 1987 DMC_RLCR_REQ 1;
BA_ "GenSigSendType" SG_ 1986 DMC_FRCR_REQ 1;
BA_ "GenSigSendType" SG_ 1985 DMC_FLCR_REQ 1;
BA_ "GenSigSendType" SG_ 1984 DMC_IDCU_REQ 1;
BA_ "GenSigSendType" SG_ 1967 DMC_CIR_REQ 1;
BA_ "GenSigSendType" SG_ 1560 WakeupSource_IHU 0;
BA_ "GenSigSendType" SG_ 1560 usrData4_IHU 0;
BA_ "GenSigSendType" SG_ 1560 usrData3_IHU 0;
BA_ "GenSigSendType" SG_ 1560 usrData2_IHU 0;
BA_ "GenSigSendType" SG_ 1560 ECUSPEC_AWAKE_IHU 0;
BA_ "GenSigSendType" SG_ 1560 DIAGNOSTIC_AWAKE_IHU 0;
BA_ "GenSigSendType" SG_ 1560 IGNITION_AWAKE_IHU 0;
BA_ "GenSigSendType" SG_ 1560 NETWORK_AWAKE_IHU 0;
BA_ "GenSigSendType" SG_ 1560 ECUSPEC_WAKEUP_IHU 0;
BA_ "GenSigSendType" SG_ 1560 NETWORK_WAKEUP_IHU 0;
BA_ "GenSigSendType" SG_ 1560 RESET_WAKEUP_IHU 0;
BA_ "GenSigSendType" SG_ 1560 IGNITION_WAKEUP_IHU 0;
BA_ "GenSigSendType" SG_ 1560 usrData0_IHU 0;
BA_ "GenSigSendType" SG_ 1560 NMm_IHU_Reserved1_CBV 0;
BA_ "GenSigSendType" SG_ 1560 RMR_IHU_CBV 0;
BA_ "GenSigSendType" SG_ 1560 srcNodeID_IHU_SNI 0;
BA_ "GenSigStartValue" SG_ 1560 srcNodeID_IHU_SNI 24;
BA_ "GenSigSendType" SG_ 1266 TBOX_SetAVMVeiw 2;
BA_ "GenSigSendType" SG_ 1266 TBOX_SetAVMOnReq 2;
BA_ "GenSigSendType" SG_ 1312 TBOX_1_RemDiagSts 0;
BA_ "GenSigSendType" SG_ 1243 HUD_1_Reserved 0;
BA_ "GenSigSendType" SG_ 1243 STAT_HUDRotation 0;
BA_ "GenSigSendType" SG_ 1243 STAT_ADASDisplayPoision 0;
BA_ "GenSigSendType" SG_ 1243 STAT_NavigationDisplay 0;
BA_ "GenSigSendType" SG_ 1243 STAT_ADASDisplay 0;
BA_ "GenSigSendType" SG_ 1243 STAT_BluetoothDisplay 0;
BA_ "GenSigSendType" SG_ 1243 HUD_1_HUDHiTWarn 0;
BA_ "GenSigSendType" SG_ 1243 STAT_FaceIDOnOFF 0;
BA_ "GenSigSendType" SG_ 1243 STAT_HUDBrightness 0;
BA_ "GenSigSendType" SG_ 1243 STAT_HUD 0;
BA_ "GenSigSendType" SG_ 1243 STAT_HUDProfileID 0;
BA_ "GenSigSendType" SG_ 1243 STAT_HUDDisplayMod 0;
BA_ "GenSigSendType" SG_ 1243 STAT_HUDDisplayOnOff 0;
BA_ "GenSigSendType" SG_ 1243 STAT_HUDHeight 0;
BA_ "GenSigSendType" SG_ 1140 STAT_SurndFnOnOff 0;
BA_ "GenSigSendType" SG_ 1140 STAT_VirtualSbwfrOnOff 0;
BA_ "GenSigSendType" SG_ 1140 STAT_AMPSoundEffectMidTreble 0;
BA_ "GenSigSendType" SG_ 1140 STAT_AMPSoundEffectMidBass 0;
BA_ "GenSigSendType" SG_ 1140 STAT_AMPSoundEffectMegaBass 0;
BA_ "GenSigSendType" SG_ 1140 STAT_AMPPwrRdySts 0;
BA_ "GenSigSendType" SG_ 1140 STAT_ENCOnOff 0;
BA_ "GenSigSendType" SG_ 1140 STAT_AMPESEVol 0;
BA_ "GenSigSendType" SG_ 1140 STAT_AMPWelVol 0;
BA_ "GenSigSendType" SG_ 1140 STAT_AMPBTMediVol 0;
BA_ "GenSigSendType" SG_ 1140 STAT_AMPTEMP 0;
BA_ "GenSigSendType" SG_ 1140 STAT_AMPMute 0;
BA_ "GenSigSendType" SG_ 1140 STAT_AMPSpeedVolume 0;
BA_ "GenSigSendType" SG_ 1140 EAMP_2_HdrestSpkrMod 0;
BA_ "GenSigSendType" SG_ 1121 STAT_AMPAlarmVolume 0;
BA_ "GenSigSendType" SG_ 1121 STAT_AMPLoudness 0;
BA_ "GenSigSendType" SG_ 1121 STAT_AMPLiveAcoustics 0;
BA_ "GenSigSendType" SG_ 1121 STAT_AMPSoundFieldFader 0;
BA_ "GenSigSendType" SG_ 1121 STAT_AMPSoundFieldBalance 0;
BA_ "GenSigSendType" SG_ 1121 STAT_AMPSoundEffectTreble 0;
BA_ "GenSigSendType" SG_ 1121 STAT_AMPSoundEffectMidrange 0;
BA_ "GenSigSendType" SG_ 1121 STAT_AMPSoundEffectBass 0;
BA_ "GenSigSendType" SG_ 1121 STAT_AMPSoundEffect 0;
BA_ "GenSigSendType" SG_ 1121 STAT_AMPRestoreDefaults 0;
BA_ "GenSigSendType" SG_ 1121 STAT_AMPDefaultVolume 0;
BA_ "GenSigSendType" SG_ 1121 STAT_AMPSoundFocus 0;
BA_ "GenSigSendType" SG_ 1121 STAT_AMPPhoneVolume 0;
BA_ "GenSigSendType" SG_ 1121 STAT_AMPMediaVolume 0;
BA_ "GenSigSendType" SG_ 1121 STAT_AMPKeyTone 0;
BA_ "GenSigSendType" SG_ 1121 STAT_AMPVRVolume 0;
BA_ "GenSigSendType" SG_ 1121 STAT_AMPNaviVolume 0;
BA_ "GenSigSendType" SG_ 1517 HUD_IHU_Interaction 1;
BA_ "GenSigSendType" SG_ 1515 IHU_HUD_Interaction 1;
BA_ "GenSigSendType" SG_ 1298 IHU_CVBOX_Interaction 1;
BA_ "GenSigSendType" SG_ 1289 CVBOX_IHU_Interaction 1;
BA_ "GenSigSendType" SG_ 759 DVR_TIHU_Interaction 1;
BA_ "GenSigSendType" SG_ 755 IHU_DVR_Interaction 1;
BA_ "GenSigSendType" SG_ 1151 TIHU_Teach_IMMO 1;
BA_ "GenSigSendType" SG_ 1116 TIHU_Auth 1;
BA_ "GenSigSendType" SG_ 1242 RsvTravelWeek 0;
BA_ "GenSigSendType" SG_ 1242 TBOX_RsvTravelSts 0;
BA_ "GenSigSendType" SG_ 1242 TBOX_RsvTravelMin 0;
BA_ "GenSigSendType" SG_ 1242 TBOX_RsvTravelHour 0;
BA_ "GenSigSendType" SG_ 856 TBOX_ChargeModeSts 0;
BA_ "GenSigSendType" SG_ 856 Reserved_4 0;
BA_ "GenSigSendType" SG_ 856 Reserved_3 0;
BA_ "GenSigSendType" SG_ 856 Reserved_2 0;
BA_ "GenSigSendType" SG_ 856 Reserved_1 0;
BA_ "GenSigSendType" SG_ 856 TBOX_ChargeTimeWeekFed1 0;
BA_ "GenSigSendType" SG_ 856 TBOX_ChargeTimeHourFed1 0;
BA_ "GenSigSendType" SG_ 856 TBOX_TimeToStartChargeMinuteFed1 0;
BA_ "GenSigSendType" SG_ 856 TBOX_TimeToStartChargeHourFed1 0;
BA_ "GenSigSendType" SG_ 1150 IHU_32_CRC 0;
BA_ "GenSigSendType" SG_ 1150 IHU_32_MessageCounter 0;
BA_ "GenSigSendType" SG_ 1150 IHU_32_Reserved3 0;
BA_ "GenSigSendType" SG_ 1150 IHU_32_Reserved2 0;
BA_ "GenSigSendType" SG_ 1150 APASoftKeyRequest 0;
BA_ "GenSigSendType" SG_ 1150 SET_BSV_Enable 0;
BA_ "GenSigSendType" SG_ 1150 IHU_CurrentThemeMode 0;
BA_ "GenSigStartValue" SG_ 1150 IHU_CurrentThemeMode 1;
BA_ "GenSigSendType" SG_ 1150 IHU_CurrentTheme 0;
BA_ "GenSigStartValue" SG_ 1150 IHU_CurrentTheme 1;
BA_ "GenSigSendType" SG_ 1150 HPA_Voice_Confirmed 0;
BA_ "GenSigStartValue" SG_ 1150 HPA_Voice_Confirmed 1;
BA_ "GenSigSendType" SG_ 1150 HPA_Voice_FuctionSwitch 0;
BA_ "GenSigStartValue" SG_ 1150 HPA_Voice_FuctionSwitch 1;
BA_ "GenSigSendType" SG_ 1150 MOD_Setting 0;
BA_ "GenSigStartValue" SG_ 1150 MOD_Setting 1;
BA_ "GenSigSendType" SG_ 1150 PDCmute_Setting 0;
BA_ "GenSigSendType" SG_ 1150 AVMSoftKeyRequest 0;
BA_ "GenSigSendType" SG_ 1150 ADAS_tollstation_Dis 3;
BA_ "GenSigSendType" SG_ 1150 ADAS_tollstation 3;
BA_ "GenSigSendType" SG_ 1150 SET_stopgo_timeEnable 3;
BA_ "GenSigStartValue" SG_ 1150 SET_stopgo_timeEnable 3;
BA_ "GenSigSendType" SG_ 1150 IHU_32_Reserved1 0;
BA_ "GenSigSendType" SG_ 1120 AdasSignDistance 0;
BA_ "GenSigSendType" SG_ 1120 AdasSignType_reserve 0;
BA_ "GenSigSendType" SG_ 1120 NavTrafficlights 0;
BA_ "GenSigSendType" SG_ 1120 NavWinding 0;
BA_ "GenSigSendType" SG_ 1092 IHU_30_Reserved_2 0;
BA_ "GenSigSendType" SG_ 1092 NavJunctions 0;
BA_ "GenSigSendType" SG_ 1092 NavRoundabouts 0;
BA_ "GenSigSendType" SG_ 1092 NavRampDistance 0;
BA_ "GenSigSendType" SG_ 1092 NavRampInfo 0;
BA_ "GenSigSendType" SG_ 1092 NavSpeedLimitType 0;
BA_ "GenSigSendType" SG_ 1092 NavFogSpeedLimit 0;
BA_ "GenSigSendType" SG_ 1092 NavSnowSpeedLimit 0;
BA_ "GenSigSendType" SG_ 1092 NavRainSpeedLimit 0;
BA_ "GenSigSendType" SG_ 1092 NavSpeedLimit_EV 0;
BA_ "GenSigSendType" SG_ 1092 NavCountryCodeInfo 0;
BA_ "GenSigSendType" SG_ 1330 IHU_29_Reserved_2 2;
BA_ "GenSigSendType" SG_ 1330 IHU_29_VoiceReminder 2;
BA_ "GenSigSendType" SG_ 1330 IHU_29_SpeedLmtNmberE 2;
BA_ "GenSigSendType" SG_ 1330 IHU_29_SpeedLmtNmberAb 2;
BA_ "GenSigSendType" SG_ 1330 IHU_29_SLAMode 2;
BA_ "GenSigSendType" SG_ 1330 ShowRoomSwt 2;
BA_ "GenSigSendType" SG_ 1330 SLASpdlimitWarningAudSWSet 2;
BA_ "GenSigSendType" SG_ 1330 SLWFONOFFSet 2;
BA_ "GenSigSendType" SG_ 1330 IHU_29_DchaSet 2;
BA_ "GenSigSendType" SG_ 1330 ElectcUnlckCmd 2;
BA_ "GenSigSendType" SG_ 1330 IHU_29_ChrgElecLockSwt 2;
BA_ "GenSigSendType" SG_ 1330 IHU_29_ChrgStopSoc 2;
BA_ "GenSigSendType" SG_ 1330 IHU_29_V2LStopSoc 2;
BA_ "GenSigSendType" SG_ 1330 IHU_29_KeepWrmSwt 2;
BA_ "GenSigSendType" SG_ 1330 IHU_29_V2LSwt 2;
BA_ "GenSigSendType" SG_ 1330 IHU_29_V2LFctSwt 2;
BA_ "GenSigSendType" SG_ 1330 IHU_29_TowMod 2;
BA_ "GenSigSendType" SG_ 1406 NaviPilot_2ndRampon_distance 0;
BA_ "GenSigSendType" SG_ 1406 NaviPilot_1stEntry_enddistance 0;
BA_ "GenSigSendType" SG_ 1406 IACC_Need_Confirm_Swtich 3;
BA_ "GenSigStartValue" SG_ 1406 IACC_Need_Confirm_Swtich 1;
BA_ "GenSigSendType" SG_ 1406 NaviPilot_start 0;
BA_ "GenSigSendType" SG_ 1406 NaviPilot_status 0;
BA_ "GenSigSendType" SG_ 1406 NaviPilot_side_along_suggestion 0;
BA_ "GenSigSendType" SG_ 1406 NaviPilot_2nd_Ramp_on 0;
BA_ "GenSigSendType" SG_ 1406 NaviPilot_1stEntry_Lane_end 0;
BA_ "GenSigSendType" SG_ 1406 NaviPilot_1st_Ramp_on_distance 0;
BA_ "GenSigSendType" SG_ 1406 NaviPilot_1st_Ramp_on 0;
BA_ "GenSigSendType" SG_ 1406 NaviPilot_Is_Ramp 0;
BA_ "GenSigSendType" SG_ 1406 NaviPilot_Is_Tunnel 0;
BA_ "GenSigSendType" SG_ 1406 NaviPilot_Current_Roadgrade 0;
BA_ "GenSigSendType" SG_ 1406 NaviPilot_1st_Exit_traffic_jam 0;
BA_ "GenSigSendType" SG_ 1406 NaviPilot_2nd_Exit_lane 0;
BA_ "GenSigSendType" SG_ 1406 NaviPilot_1st_Exit_lane 0;
BA_ "GenSigSendType" SG_ 1293 NaviPilot_1stExit_jam_end 0;
BA_ "GenSigSendType" SG_ 1293 NaviPilot_1stExit_jam_start 0;
BA_ "GenSigSendType" SG_ 1293 NaviPilot_2nd_Exit_distance 0;
BA_ "GenSigSendType" SG_ 1293 NaviPilot_1st_Exit_distance 0;
BA_ "GenSigSendType" SG_ 1177 IHU_26_RRWinCmd 2;
BA_ "GenSigSendType" SG_ 1177 IHU_26_WiprSnvty 2;
BA_ "GenSigSendType" SG_ 1177 IHU_26_SeatLegSpprtPosnCmd 2;
BA_ "GenSigSendType" SG_ 1177 IHU_26_RLWinCmd 2;
BA_ "GenSigSendType" SG_ 1177 IHU_26_FRWinCmd 2;
BA_ "GenSigSendType" SG_ 1177 IHU_26_FLWinCmd 2;
BA_ "GenSigSendType" SG_ 1177 ChrgPortCover_Switch 2;
BA_ "GenSigSendType" SG_ 1177 IHU_26_CenterLockSwt 2;
BA_ "GenSigSendType" SG_ 1177 IHU_26_SeatLvlPosnCmd 2;
BA_ "GenSigSendType" SG_ 1177 IHU_26_SeatHdrestHeiAdjmtCmd 2;
BA_ "GenSigSendType" SG_ 1177 IHU_26_WinInhbSwt 2;
BA_ "GenSigSendType" SG_ 1177 IHU_26_ReWinDefrstSwt 2;
BA_ "GenSigSendType" SG_ 1177 IHU_26_SteerWhlHeatgSwt 2;
BA_ "GenSigSendType" SG_ 1177 IHU_26_BackrAgPosnCmd 2;
BA_ "GenSigSendType" SG_ 1177 IHU_26_SeatCushPosnCmd 2;
BA_ "GenSigSendType" SG_ 1177 IHU_26_SeatHeiPosnCmd 2;
BA_ "GenSigSendType" SG_ 643 IHU_25_APPsts 0;
BA_ "GenSigSendType" SG_ 643 IHU_25_AmbLigFlngModSel 0;
BA_ "GenSigSendType" SG_ 643 IHU_25_AmbLig14FlngEna 0;
BA_ "GenSigSendType" SG_ 643 IHU_25_AmbLig13FlngEna 0;
BA_ "GenSigSendType" SG_ 643 IHU_25_AmbLig12FlngEna 0;
BA_ "GenSigSendType" SG_ 643 IHU_25_AmbLigFadeINOUTStepTi 0;
BA_ "GenSigSendType" SG_ 643 IHU_25_AmbLig14FadeEna 0;
BA_ "GenSigSendType" SG_ 643 IHU_25_AmbLig13FadeEna 0;
BA_ "GenSigSendType" SG_ 643 IHU_25_AmbLig12FadeEna 0;
BA_ "GenSigSendType" SG_ 643 IHU_25_AmbLig11FadeEna 0;
BA_ "GenSigSendType" SG_ 643 IHU_25_AmbLig10FadeEna 0;
BA_ "GenSigSendType" SG_ 643 IHU_25_AmbLig09FadeEna 0;
BA_ "GenSigSendType" SG_ 643 IHU_25_AmbLig08FadeEna 0;
BA_ "GenSigSendType" SG_ 643 IHU_25_AmbLig07FadeEna 0;
BA_ "GenSigSendType" SG_ 643 IHU_25_AmbLig06FadeEna 0;
BA_ "GenSigSendType" SG_ 643 IHU_25_AmbLig05FadeEna 0;
BA_ "GenSigSendType" SG_ 643 IHU_25_AmbLig04FadeEna 0;
BA_ "GenSigSendType" SG_ 643 IHU_25_AmbLig03FadeEna 0;
BA_ "GenSigSendType" SG_ 643 IHU_25_AmbLig02FadeEna 0;
BA_ "GenSigSendType" SG_ 643 IHU_25_AmbLig01FadeEna 0;
BA_ "GenSigSendType" SG_ 643 IHU_25_AmbLigColorAdj 0;
BA_ "GenSigSendType" SG_ 643 IHU_25_AmbLigBriAdj 0;
BA_ "GenSigSendType" SG_ 643 IHU_25_AmbLig14Authn 0;
BA_ "GenSigSendType" SG_ 643 IHU_25_AmbLig13Authn 0;
BA_ "GenSigSendType" SG_ 643 IHU_25_AmbLig12Authn 0;
BA_ "GenSigSendType" SG_ 643 IHU_25_AmbLig11Authn 0;
BA_ "GenSigSendType" SG_ 643 IHU_25_AmbLig10Authn 0;
BA_ "GenSigSendType" SG_ 643 IHU_25_AmbLig09Authn 0;
BA_ "GenSigSendType" SG_ 643 IHU_25_AmbLig08Authn 0;
BA_ "GenSigSendType" SG_ 643 IHU_25_AmbLig07Authn 0;
BA_ "GenSigSendType" SG_ 643 IHU_25_AmbLig06Authn 0;
BA_ "GenSigSendType" SG_ 643 IHU_25_AmbLig05Authn 0;
BA_ "GenSigSendType" SG_ 643 IHU_25_AmbLig04Authn 0;
BA_ "GenSigSendType" SG_ 643 IHU_25_AmbLig03Authn 0;
BA_ "GenSigSendType" SG_ 643 IHU_25_AmbLig02Authn 0;
BA_ "GenSigSendType" SG_ 643 IHU_25_AmbLig01Authn 0;
BA_ "GenSigSendType" SG_ 1244 PassSeatMsgModeCmd 1;
BA_ "GenSigSendType" SG_ 1244 PassSeatMsgStr_LvlCmd 1;
BA_ "GenSigSendType" SG_ 1244 IHU_24_Reserved5 1;
BA_ "GenSigSendType" SG_ 1244 IHU_24_SetHUDRot 1;
BA_ "GenSigSendType" SG_ 1244 IHU_24_Reserved3 1;
BA_ "GenSigSendType" SG_ 1244 AUTODefrostlevelKeySts 2;
BA_ "GenSigSendType" SG_ 1244 DriverSeatMsg_ModeCmd 1;
BA_ "GenSigSendType" SG_ 1244 DriverSeatMsgStr_Lvlcmd 1;
BA_ "GenSigSendType" SG_ 1244 IHU_24_SetAdasDisp 1;
BA_ "GenSigSendType" SG_ 1244 IHU_24_SetBlueToothDisp 1;
BA_ "GenSigSendType" SG_ 1244 IHU_24_SetFaceIdOnoff 1;
BA_ "GenSigSendType" SG_ 1244 IHU_24_PwrOff 2;
BA_ "GenSigSendType" SG_ 1244 IHU_RearFogLightSwtCmd 2;
BA_ "GenSigSendType" SG_ 1244 IHU_FrntFogLightSwtCmd 2;
BA_ "GenSigSendType" SG_ 1244 IHU_24_SetAdasDispPoision 1;
BA_ "GenSigSendType" SG_ 1244 IHU_24_SetNavDisp 1;
BA_ "GenSigSendType" SG_ 1244 IHU_24_SetHudBri 1;
BA_ "GenSigSendType" SG_ 1244 IHU_24_SetHudDispMod 1;
BA_ "GenSigSendType" SG_ 1244 IHU_LightMainSwitchCmd 2;
BA_ "GenSigSendType" SG_ 1244 IHU_24_SetHudHei 1;
BA_ "GenSigSendType" SG_ 1244 IHU_24_SetHudDispOnOff 1;
BA_ "GenSigSendType" SG_ 1035 IHU_23_CRC 0;
BA_ "GenSigSendType" SG_ 1035 IHU_23_MessageCounter 0;
BA_ "GenSigSendType" SG_ 1035 IHU_23_Reserved3 0;
BA_ "GenSigSendType" SG_ 1035 IHU_23_Reserved2 0;
BA_ "GenSigSendType" SG_ 1035 IHU_OTAPwrMngt 0;
BA_ "GenSigSendType" SG_ 1035 IHU_OTAHvReq 0;
BA_ "GenSigSendType" SG_ 1035 IHU_OTASts 0;
BA_ "GenSigSendType" SG_ 1035 IHU_23_Reserved1 0;
BA_ "GenSigSendType" SG_ 1278 IHU_22_Reserved1 2;
BA_ "GenSigSendType" SG_ 1278 IHU_22_DispEvDteTyp 2;
BA_ "GenSigSendType" SG_ 1278 IHU_22_DispPwrMod 2;
BA_ "GenSigSendType" SG_ 1278 IHU_22_RCCPInhbSwt 2;
BA_ "GenSigSendType" SG_ 1278 IHU_22_FRSeatAutVentnCmd 2;
BA_ "GenSigSendType" SG_ 1278 IHU_22_FLSeatAutVentnCmd 2;
BA_ "GenSigSendType" SG_ 1278 IHU_22_FRSeatAutHeatCmd 2;
BA_ "GenSigSendType" SG_ 1278 IHU_22_FLSeatAutHeatCmd 2;
BA_ "GenSigSendType" SG_ 1278 SHU3RSeatVentilationCmd 2;
BA_ "GenSigSendType" SG_ 1278 SHU3LSeatVentilationCmd 2;
BA_ "GenSigSendType" SG_ 1278 SHU3RSeatHeatLevelCmd 2;
BA_ "GenSigSendType" SG_ 1278 SHU3LSeatHeatLevelCmd 2;
BA_ "GenSigSendType" SG_ 1278 SHU2RSeatVentilationCmd 2;
BA_ "GenSigSendType" SG_ 1278 SHU2MSeatVentilationCmd 2;
BA_ "GenSigSendType" SG_ 1278 SHU2LSeatVentilationCmd 2;
BA_ "GenSigSendType" SG_ 1278 SHU2RSeatHeatLevelCmd 2;
BA_ "GenSigSendType" SG_ 1278 SHU2MSeatHeatLevelCmd 2;
BA_ "GenSigSendType" SG_ 1278 SHU2LSeatHeatLevelCmd 2;
BA_ "GenSigSendType" SG_ 1278 IHU_22_FRSeatVentilationCmd 2;
BA_ "GenSigSendType" SG_ 1278 IHU_22_FLSeatVentilationCmd 2;
BA_ "GenSigSendType" SG_ 1278 IHU_22_FRSeatHeatLevelCmd 2;
BA_ "GenSigSendType" SG_ 1278 IHU_22_FLSeatHeatLevelCmd 2;
BA_ "GenSigSendType" SG_ 1155 IHU_21_Reserved_1 2;
BA_ "GenSigSendType" SG_ 1155 IHU_setRsvTravelWeek 2;
BA_ "GenSigSendType" SG_ 1155 IHU_setRsvTravelSts 2;
BA_ "GenSigSendType" SG_ 1155 IHU_setRsvTravelMin 2;
BA_ "GenSigSendType" SG_ 1155 IHU_setRsvTravelHour 2;
BA_ "GenSigSendType" SG_ 1480 IHU_20_Reserved1 0;
BA_ "GenSigSendType" SG_ 1480 NextTrafficSts 0;
BA_ "GenSigStartValue" SG_ 1480 NextTrafficSts 3;
BA_ "GenSigSendType" SG_ 1480 TrafficSts 0;
BA_ "GenSigStartValue" SG_ 1480 TrafficSts 3;
BA_ "GenSigSendType" SG_ 1480 NavDistance 0;
BA_ "GenSigSendType" SG_ 1119 IHU_19_Reserved_1 2;
BA_ "GenSigSendType" SG_ 1119 IHU_19_Set_HdrestSpkrMod 2;
BA_ "GenSigSendType" SG_ 1119 IHU_19_Set_AMPESEVol 2;
BA_ "GenSigSendType" SG_ 1119 IHU_19_Set_AMPWelVol 2;
BA_ "GenSigSendType" SG_ 1119 IHU_19_Set_AMPBTMediVol 2;
BA_ "GenSigSendType" SG_ 1119 IHU_19_REQ_AMPA2BMediSound 2;
BA_ "GenSigSendType" SG_ 1119 IHU_19_REQ_AMPA2BESESound 2;
BA_ "GenSigSendType" SG_ 1119 IHU_19_PABSetCmd 2;
BA_ "GenSigSendType" SG_ 1119 IHU_19_HwSet 2;
BA_ "GenSigSendType" SG_ 1119 IHU_19_BSRBPASet 2;
BA_ "GenSigSendType" SG_ 1119 REQ_AMPA2BKeyTone 2;
BA_ "GenSigSendType" SG_ 1119 REQ_AMPA2BTTSSound 2;
BA_ "GenSigSendType" SG_ 1119 REQ_AMPA2BVRSound 2;
BA_ "GenSigSendType" SG_ 1119 REQ_AMPA2BNaviSound 2;
BA_ "GenSigSendType" SG_ 1119 REQ_AMPA2BMediaSound 2;
BA_ "GenSigSendType" SG_ 1119 Set_AMPMute 2;
BA_ "GenSigSendType" SG_ 1119 Set_AMPSpeedVolume 2;
BA_ "GenSigSendType" SG_ 1119 REQ_AMPA2BPhoneSound 2;
VAL_ 1050 HPA_Subscribe_Status 7 "Reserved" 6 "Reserved" 5 "Subscription expires in a 1 day" 4 "Subscription expires in a 7 days" 3 "Subscription Out of Date" 2 "Subscription Failed" 1 "Subscription succeeded" 0 "OFF" ;
VAL_ 1050 HPA_IHU_Audio_HPA_status 1 "HPA display" 0 "HPA hidden" ;
VAL_ 1050 FaultStatusCameraDVR 3 "Reserved" 2 "Failure" 1 "Normal" 0 "Unready" ;
VAL_ 1050 REQ_AVMDisp_1 3 "Ignore" 2 "Request Off" 1 "Request On" 0 "No request" ;
VAL_ 1050 PDC_fault_status 1 "PDC  failure" 0 "No  failure" ;
VAL_ 1050 APA_fault_status 3 "Reserved" 2 "HPA failure" 1 "APA  failure" 0 "No failure" ;
VAL_ 1050 FAPASet_Feedback 1 "ON" 0 "OFF" ;
VAL_ 1050 HPASubStsFeedback 1 "Subscrib" 0 "Not Subscrib" ;
VAL_ 1050 UndoSet_Feedback 1 "ON" 0 "OFF" ;
VAL_ 1050 Undo_fault_status 1 "Undo failure" 0 "No failure" ;
VAL_ 1050 PDCmute_Set_Feedback 1 "ON" 0 "OFF" ;
VAL_ 1050 MOD_WorkSts 3 "RESERVED" 2 "ACTIVE" 1 "standby" 0 "OFF" ;
VAL_ 1050 STAT_BSV_status 1 "on" 0 "off" ;
VAL_ 1050 HPAMode 7 "Invalid" 6 "Terminated" 5 "Failure" 4 "Completed" 3 "Guidance" 2 "Training" 1 "Standby" 0 "Off" ;
VAL_ 1050 HPAActive 1 "Active" 0 "Inactive" ;
VAL_ 1050 HPA_IHU_Audio_Park_Tips_1 21 "Reserved" 20 "Reserved" 19 "Reserved" 18 "Reserved" 17 "Reserved" 16 "Reserved" 9 "tips for new parking space" 8 "tips for pedestrian" 7 "alarm" 6 "quit" 5 "pause" 4 "tips for parking failure" 3 "take over request(function deactived)" 2 "take over request(hazard situation)" 1 "take over request(system failure)" 0 "pause" ;
VAL_ 1050 HPA_IHU_Audio_Learn_Tips_1 21 " Reserved" 20 " Reserved" 19 " Reserved" 18 " Reserved" 17 " Reserved" 16 " Reserved" 9 " Reserved" 8 " Reserved" 7 " Reserved" 6 " Reserved" 5 " Reserved" 4 " Reserved" 3 " failure tips for overspeed" 2 " failure tips for out of range" 1 " failure tips for overtime" 0 " failure tips for environment" ;
VAL_ 1050 HPA_IHU_Audio_Park_Tips 21 "tips for narrow lane" 20 "tips for oncoming car" 19 "parking confirm " 18 "break tips for braking" 17 "break tips for obstacle" 16 "break tips for safe belt" 9 "break tips for door open" 8 "tips when HPA deactivation" 7 "function recover request" 6 "tips after parking" 5 "tips before parking" 4 "tips before a cross" 3 "turn right" 2 "turn left" 1 "prepration for activation" 0 "HPA activation request" ;
VAL_ 1050 HPA_IHU_Audio_Learn_Tips 21 " map-cancel" 20 " system failure" 19 " learning-cancel" 18 " tips for safety belt" 17 " move on" 16 " tips for door-open" 9 " map-building initialization" 8 " tips for experience" 7 " tips for map-building completion" 6 " map-rebulid tips" 5 " map storage request" 4 " tips for overtime" 3 " tips for out of range" 2 " deceleration request" 1 " move forward and park in" 0 " map-building request" ;
VAL_ 1050 HPA_Exam_status 3 "Reserved" 2 "Exam Failed" 1 "Exam succeeded" 0 "OFF" ;
VAL_ 1050 REQ_BSVDisp 3 "Reserved" 2 "Right Request" 1 "Left Request" 0 "No Request" ;
VAL_ 1050 MEBSet_Feedback 1 "ON" 0 "OFF" ;
VAL_ 1050 AVM_FactoryMode 1 " Factory Mode" 0 " Normal Mode" ;
VAL_ 1050 AVMFeedbackSts_RemoteMode 1 " On" 0 " Off" ;
VAL_ 1050 AVM_3_IHUTTSExtend 15 "Reserved" 14 "Reserved" 13 "Reserved" 12 "Reserved" 11 "Reserved" 10 "Parking space recognition " 9 "The path is smooth, please park out by yourself" 8 "Please select  function" 7 "Follow Trajactory Backing is available" 6 "Please drive to the clear parking line of road" 5 "Please learn the route first" 4 "Please drive to the starting point of route learning" 3 " Please shift to P gear and pull up the electronic handbrake" 2 " Please dial the steering light to select the parking direction" 1 " The speed is too fast, please slow down" 0 " None" ;
VAL_ 1050 AVM_3_IHUTTS 31 "Please select parking space" 30 "Please close the trunk" 29 "Please close the hood" 28 "Please fasten  Seat Belt" 27 "Please close the door" 26 "Memory Parking out is available," 25 "Parking out function is available" 24 " Remote exit" 23 " Remote pause" 22 " Backing exit,please take over" 21 " Backing is suspended,please check" 20 " Release the brakes and steering wheel,Backing is beginning" 19 " Backing is completed" 18 " Remote backward" 17 " Remote foward" 16 " Pay attention to surroundings" 15 " Release the brakes and steering wheel, Parking is beginning" 14 " Slot parking available" 13 " Cruise parking available" 12 " Memory parking available" 11 " The route saving failed" 10 " The route saved successfully" 9 " The route is being saved, do not touch any key" 8 " The route learning mileage is about to reach the upper limit" 7 " Route learning failed£¨ODD is not satisfied" 6 " Parking is completed" 5 " Parking exit, please take over" 4 " Parking is suspended, please check" 3 " Open the mobile APP to activate the parking function" 2 " Select the activation mode of parking function" 1 " Drive forward to search parking slot" 0 " None" ;
VAL_ 1050 AVMDisplaySts 1 " On" 0 " Off" ;
VAL_ 1267 AIPM_2_DriveModeSet 3 " Not Used" 2 " DOWN" 1 " UP" 0 " Not Active" ;
VAL_ 1265 PanelKeyVoiceRemindReq 1 " Request" 0 " Not active" ;
VAL_ 704 CDPFailSts 0 " Fail not present" 1 " Fail present (lamp on)" ;
VAL_ 704 AVHFailSts 0 " Fail not present" 1 " Fail present (lamp on)" ;
VAL_ 704 AVHSts 3 " Not Used" 2 " Active" 1 " Standby" 0 " Off" ;
VAL_ 704 HDCFailSts 0 " Fail not present" 1 " Fail present (lamp on)" ;
VAL_ 704 DiagnosticSessionSts 0 " Not active" 1 " Active" ;
VAL_ 704 CDPActive 0 " Not active" 1 " Active" ;
VAL_ 704 HHCFailSts 0 " Fail not present" 1 " Fail present (lamp on)" ;
VAL_ 704 VDCActive 0 " Not active" 1 " Active(blinking lamp)" ;
VAL_ 704 TCSActive 0 " Not active" 1 " Active(blinking lamp)" ;
VAL_ 704 VDCFailSts 0 " Fail not present" 1 " Fail present (lamp on)" ;
VAL_ 704 TCSFailSts 0 " Fail not present" 1 " Fail present (lamp on)" ;
VAL_ 704 EBDFailSts 0 " Fail not present" 1 " Fail present (lamp on)" ;
VAL_ 704 ABSFailSts 0 " Fail not present" 1 " Fail present (lamp on)" ;
VAL_ 704 AVHWarningMessage 1 " Fasten DriverSeatBelt and Close the LHF door" 0 " Off" ;
VAL_ 704 HDCCtrlSts 3 " Not used" 2 " On active braking" 1 " flash not active braking" 0 " OFF" ;
VAL_ 704 VehicleSpeedVSOSigValidData 1 " Not valid" 0 " Valid" ;
VAL_ 704 ESPSwitchStatus 1 " Disable" 0 " On" ;
VAL_ 932 RHRWheelSpeedRawValidData 1 " Not Valid" 0 " Valid" ;
VAL_ 932 RHRWheelDriveDirection 7 " reserved" 6 " reserved" 5 " reserved" 4 " Invalid" 3 " Stop" 2 " Backward" 1 " Forward" 0 " Init" ;
VAL_ 932 LHRWheelSpeedRawValidData 1 " Not Valid" 0 " Valid" ;
VAL_ 932 LHRWheelDriveDirection 7 " reserved" 6 " reserved" 5 " reserved" 4 " Invalid" 3 " Stop" 2 " Backward" 1 " Forward" 0 " Init" ;
VAL_ 931 RHFWheelSpeedRawValidData 1 " Not Valid" 0 " Valid" ;
VAL_ 931 RHFWheelDriveDirection 7 " reserved" 6 " reserved" 5 " reserved" 4 " Invalid" 3 " Stop" 2 " Backward" 1 " Forward" 0 " Init" ;
VAL_ 931 LHFWheelSpeedRawValidData 1 " Not Valid" 0 " Valid" ;
VAL_ 931 LHFWheelDriveDirection 7 " reserved" 6 " reserved" 5 " reserved" 4 " Invalid" 3 " Stop" 2 " Backward" 1 " Forward" 0 " Init" ;
VAL_ 793 RHRPulseCounterFailSts 1 " Fail Present" 0 " Fail Not Present" ;
VAL_ 793 LHFPulseCounterFailSts 1 " Fail Present" 0 " Fail Not Present" ;
VAL_ 793 RHFPulseCounterFailSts 1 " Fail Present" 0 " Fail Not Present" ;
VAL_ 793 LHRPulseCounterFailSts 1 " Fail Present" 0 " Fail Not Present" ;
VAL_ 787 ABS_ESP_3_AVHSts 3 " Not used" 2 " Active" 1 " Standby" 0 " Off" ;
VAL_ 787 ABS_ESP_3_AVHFailSts 1 " Fail present (lamp on)" 0 " Not present" ;
VAL_ 800 SecRowRBeltWarning 1 "Warning" 0 "No Warning" ;
VAL_ 800 SecRowMBeltWarning 1 "Warning" 0 "No Warning" ;
VAL_ 800 SecRowLBeltWarning 1 "Warning" 0 "No Warning" ;
VAL_ 800 ThdRowRBeltWarning 1 "Warning" 0 "No Warning" ;
VAL_ 800 ThdRowLBeltWarning 1 "Warning" 0 "No Warning" ;
VAL_ 800 PsngrSeatBeltWarning 3 " Not used" 2 " Warning" 1 " Reserve" 0 " Not warning" ;
VAL_ 800 AirBagFailSts 3 " Lamp on, but no warning information displaying on the LCD" 2 " Fail present, lamp on" 1 " Fail no present, lamp flashing" 0 " Fail no present, lamp off" ;
VAL_ 800 ABM_1_PABSetSts 1 "PAB ON" 0 "PAB OFF" ;
VAL_ 1250 BMS_34_ValidData 1 " Not valid" 0 " Valid" ;
VAL_ 1250 EVCC_2_ValidData 1 " Not valid" 0 " Valid" ;
VAL_ 1250 EVCC_ElectronicLockSts 4 "Elock error" 3 "Unlock error" 2 "Lock error" 1 "Lock" 0 "Unlock" ;
VAL_ 1509 TCU_5_ValidData 1 " Not valid" 0 " Valid" ;
VAL_ 1509 HCU_EMS_3_ValidData 1 " Not valid" 0 " Valid" ;
VAL_ 1509 AWD_1_ValidData 1 " Not valid" 0 " Valid" ;
VAL_ 1560 ECUSPEC_AWAKE_IHU 1 " Active" 0 " Inactive" ;
VAL_ 1560 DIAGNOSTIC_AWAKE_IHU 1 " Active" 0 " Inactive" ;
VAL_ 1560 IGNITION_AWAKE_IHU 1 " Active" 0 " Inactive" ;
VAL_ 1560 NETWORK_AWAKE_IHU 1 " Active" 0 " Inactive" ;
VAL_ 1560 ECUSPEC_WAKEUP_IHU 1 " Active" 0 " Inactive" ;
VAL_ 1560 NETWORK_WAKEUP_IHU 1 " Active" 0 " Inactive" ;
VAL_ 1560 RESET_WAKEUP_IHU 1 " Active" 0 " Inactive" ;
VAL_ 1560 IGNITION_WAKEUP_IHU 1 " Active" 0 " Inactive" ;
VAL_ 1560 usrData0_IHU 255 " User data not used" 0 " User data for current vehicle" ;
VAL_ 1560 RMR_IHU_CBV 1 " Active" 0 " Inactive" ;
VAL_ 1266 TBOX_SetAVMVeiw 7 " Not used" 6 " Not used" 5 " Not used" 4 " 2D right" 3 " 2D left" 2 " 2D Rear" 1 " 2D front" 0 " Not Active       " ;
VAL_ 1266 TBOX_SetAVMOnReq 3 " Not used" 2 " On                                                         " 1 " Off                                                   " 0 " Not Active   " ;
VAL_ 1312 TBOX_1_RemDiagSts 3 "End Read" 2 "Reading" 1 "Start Read" 0 "Not Read" ;
VAL_ 1243 STAT_HUDRotation 15 "Reserved" 14 "Reserved" 13 "Reserved" 12 "Reserved" 11 "2.0" 10 "1.6" 9 "1.2" 8 "0.8" 7 "0.4" 5 "-0.4" 4 "-0.8" 3 "-1.2" 2 "-1.6" 1 "-2" 0 "Not Active " ;
VAL_ 1243 STAT_ADASDisplayPoision 3 "Invalid" 2 "Ignore" 1 "ADAS right" 0 "ADAS left" ;
VAL_ 1243 STAT_NavigationDisplay 1 "Display" 0 "No Display" ;
VAL_ 1243 STAT_ADASDisplay 1 "Display" 0 "No Display" ;
VAL_ 1243 STAT_BluetoothDisplay 1 "Display" 0 "No Display" ;
VAL_ 1243 HUD_1_HUDHiTWarn 3 "Reserved" 2 "Reserved" 1 "warning" 0 "No warning" ;
VAL_ 1243 STAT_FaceIDOnOFF 1 "ON" 0 "OFF" ;
VAL_ 1243 STAT_HUDBrightness 9 "Level10" 8 "Level9" 7 "Level8" 6 "Level7" 5 "Level6" 4 "Level5" 3 "Level4" 2 "Level3" 1 "Level2" 0 "Level1" ;
VAL_ 1243 STAT_HUD 3 " Standby" 2 " Preparing" 1 " Error" 0 " Normal" ;
VAL_ 1243 STAT_HUDProfileID 7 "Ignore" 6 "Reserved" 5 "Reserved" 4 "ID5" 3 "ID4" 2 "ID3" 1 "ID2" 0 "ID1" ;
VAL_ 1243 STAT_HUDDisplayMod 2 "sport" 1 " Snowy" 0 " Normal" ;
VAL_ 1243 STAT_HUDDisplayOnOff 1 " ON" 0 " OFF" ;
VAL_ 1243 STAT_HUDHeight 15 "Reserved" 14 "Reserved" 13 "Reserved" 12 "Reserved" 11 "Reserved" 10 "Reserved" 9 "Level10" 8 "Level9" 7 "Level8" 6 "Level7" 5 "Level6" 4 "Level5" 3 "Level4" 2 "Level3" 1 "Level2" 0 "Level1" ;
VAL_ 1140 STAT_SurndFnOnOff 3 "Reserved" 2 "OFF" 1 "ON" 0 "Not Active" ;
VAL_ 1140 STAT_VirtualSbwfrOnOff 3 "OFF" 2 "ConcertHall" 1 "VocalConcert" 0 "Not Active" ;
VAL_ 1140 STAT_AMPSoundEffectMidTreble 7 "-1" 6 "-2" 5 "-3" 4 "-4" 3 "-5" 2 "-6" 1 "-7" 0 "Not Active" ;
VAL_ 1140 STAT_AMPSoundEffectMidBass 7 "-1" 6 "-2" 5 "-3" 4 "-4" 3 "-5" 2 "-6" 1 "-7" 0 "Not Active" ;
VAL_ 1140 STAT_AMPSoundEffectMegaBass 7 "-1" 6 "-2" 5 "-3" 4 "-4" 3 "-5" 2 "-6" 1 "-7" 0 "Not Active" ;
VAL_ 1140 STAT_AMPPwrRdySts 1 " ON" 0 "OFF" ;
VAL_ 1140 STAT_ENCOnOff 1 " ON" 0 "OFF" ;
VAL_ 1140 STAT_AMPESEVol 63 " Reserved" 62 " Reserved" 61 " Reserved" 60 " Reserved" 59 " Reserved" 58 " Reserved" 57 " Reserved" 56 " Reserved" 55 " Reserved" 54 " Reserved" 53 " Reserved" 52 " Reserved" 51 " Reserved" 50 " Reserved" 49 " Reserved" 48 " Reserved" 41 " Reserved" 40 " Reserved" 39 " Reserved" 38 " Reserved" 37 " Reserved" 36 " Reserved" 35 " Reserved" 34 " Reserved" 33 " Reserved" 32 " 31" 31 " 30" 30 " 29" 29 " 28" 28 " 27" 27 " 26" 26 " 25" 25 " 24" 24 " 23" 23 " 22" 22 " 21" 21 " 20" 20 " 19" 19 " 18" 18 " 17" 17 " 16" 16 " 15" 15 " 14" 14 " 13" 13 " 12" 12 " 11" 11 " 10" 10 " 9" 9 " 8" 8 " 7" 7 " 6" 6 " 5" 5 " 4" 4 " 3" 3 " 2" 2 " 1" 1 " 0 " 0 " Not Active" ;
VAL_ 1140 STAT_AMPWelVol 63 " Reserved" 62 " Reserved" 61 " Reserved" 60 " Reserved" 59 " Reserved" 58 " Reserved" 57 " Reserved" 56 " Reserved" 55 " Reserved" 54 " Reserved" 53 " Reserved" 52 " Reserved" 51 " Reserved" 50 " Reserved" 49 " Reserved" 48 " Reserved" 41 " Reserved" 40 " Reserved" 39 " Reserved" 38 " Reserved" 37 " Reserved" 36 " Reserved" 35 " Reserved" 34 " Reserved" 33 " Reserved" 32 " 31" 31 " 30" 30 " 29" 29 " 28" 28 " 27" 27 " 26" 26 " 25" 25 " 24" 24 " 23" 23 " 22" 22 " 21" 21 " 20" 20 " 19" 19 " 18" 18 " 17" 17 " 16" 16 " 15" 15 " 14" 14 " 13" 13 " 12" 12 " 11" 11 " 10" 10 " 9" 9 " 8" 8 " 7" 7 " 6" 6 " 5" 5 " 4" 4 " 3" 3 " 2" 2 " 1" 1 " 0 " 0 " Not Active" ;
VAL_ 1140 STAT_AMPBTMediVol 63 " Reserved" 62 " Reserved" 61 " Reserved" 60 " Reserved" 59 " Reserved" 58 " Reserved" 57 " Reserved" 56 " Reserved" 55 " Reserved" 54 " Reserved" 53 " Reserved" 52 " Reserved" 51 " Reserved" 50 " Reserved" 49 " Reserved" 48 " Reserved" 41 " Reserved" 40 " Reserved" 39 " Reserved" 38 " Reserved" 37 " Reserved" 36 " Reserved" 35 " Reserved" 34 " Reserved" 33 " Reserved" 32 " 31" 31 " 30" 30 " 29" 29 " 28" 28 " 27" 27 " 26" 26 " 25" 25 " 24" 24 " 23" 23 " 22" 22 " 21" 21 " 20" 20 " 19" 19 " 18" 18 " 17" 17 " 16" 16 " 15" 15 " 14" 14 " 13" 13 " 12" 12 " 11" 11 " 10" 10 " 9" 9 " 8" 8 " 7" 7 " 6" 6 " 5" 5 " 4" 4 " 3" 3 " 2" 2 " 1" 1 " 0 " 0 " Not Active" ;
VAL_ 1140 STAT_AMPTEMP 7 " Reserved" 6 " Reserved" 5 " Reserved" 4 " Reserved" 3 " 3" 2 " 2" 1 " 1" 0 " Not Active" ;
VAL_ 1140 STAT_AMPMute 3 " reserved" 2 " OFF" 1 " ON" 0 " Not Active" ;
VAL_ 1140 STAT_AMPSpeedVolume 7 " Reserved" 6 " Reserved" 5 " Reserved" 4 " High" 3 " Middle" 2 " Low" 1 " OFF" 0 " Not Active" ;
VAL_ 1140 EAMP_2_HdrestSpkrMod 7 "reserved" 6 "reserved " 5 "reserved" 4 "reserved" 3 "Private mode" 2 "Drive mode" 1 "Shared mode" 0 "Not Active" ;
VAL_ 1121 STAT_AMPAlarmVolume 15 " Reserved" 14 " Reserved" 13 " Reserved" 12 " Reserved" 11 " Reserved" 10 " 10" 9 " 9" 8 " 8" 7 " 7" 6 " 6" 5 " 5" 4 " 4" 3 " 3" 2 " 2" 1 " 1" 0 " Not Active" ;
VAL_ 1121 STAT_AMPLoudness 3 " reserved" 2 " OFF" 1 " ON" 0 " Not Active" ;
VAL_ 1121 STAT_AMPLiveAcoustics 3 " reserved" 2 " OFF" 1 " ON" 0 " Not Active" ;
VAL_ 1121 STAT_AMPSoundFieldFader 15 " 7" 14 " 6" 13 " 5" 12 " 4" 11 " 3" 10 " 2" 9 " 1" 8 " 0" 7 " -1" 6 " -2" 5 " -3" 4 " -4" 3 " -5" 2 " -6" 1 " -7" 0 " Not Active" ;
VAL_ 1121 STAT_AMPSoundFieldBalance 15 " 7" 14 " 6" 13 " 5" 12 " 4" 11 " 3" 10 " 2" 9 " 1" 8 " 0" 7 " -1" 6 " -2" 5 " -3" 4 " -4" 3 " -5" 2 " -6" 1 " -7" 0 " Not Active" ;
VAL_ 1121 STAT_AMPSoundEffectTreble 15 " 7" 14 " 6" 13 " 5" 12 " 4" 11 " 3" 10 " 2" 9 " 1" 8 " 0" 7 " -1" 6 " -2" 5 " -3" 4 " -4" 3 " -5" 2 " -6" 1 " -7" 0 " Not Active" ;
VAL_ 1121 STAT_AMPSoundEffectMidrange 15 " 7" 14 " 6" 13 " 5" 12 " 4" 11 " 3" 10 " 2" 9 " 1" 8 " 0" 7 " -1" 6 " -2" 5 " -3" 4 " -4" 3 " -5" 2 " -6" 1 " -7" 0 " Not Active" ;
VAL_ 1121 STAT_AMPSoundEffectBass 15 " 7" 14 " 6" 13 " 5" 12 " 4" 11 " 3" 10 " 2" 9 " 1" 8 " 0" 7 " -1" 6 " -2" 5 " -3" 4 " -4" 3 " -5" 2 " -6" 1 " -7" 0 " Not Active" ;
VAL_ 1121 STAT_AMPSoundEffect 15 " Reserved" 14 " Reserved" 13 " Reserved" 12 " Reserved" 11 " Reserved" 10 " Reserved" 9 "  Reserved" 8 " Rural model" 7 " Vocals mode" 6 " Rock mode" 5 " Classic mode" 4 " Jazz mode" 3 " Popular mode" 2 " Standard mode " 1 " Customer-defined mode" 0 " Not Active" ;
VAL_ 1121 STAT_AMPRestoreDefaults 3 " Reserved" 2 " OFF" 1 " ON" 0 " Not Active" ;
VAL_ 1121 STAT_AMPDefaultVolume 63 " Reserved" 62 " Reserved" 61 " Reserved" 60 " Reserved" 59 " Reserved" 58 " Reserved" 57 " Reserved" 56 " Reserved" 55 " Reserved" 54 " Reserved" 53 " Reserved" 52 " Reserved" 51 " Reserved" 50 " Reserved" 49 " Reserved" 48 " Reserved" 41 " Reserved" 40 " Reserved" 39 " Reserved" 38 " Reserved" 37 " Reserved" 36 " Reserved" 35 " Reserved" 34 " Reserved" 33 " Reserved" 32 " 31" 31 " 30" 30 " 29" 29 " 28" 28 " 27" 27 " 26" 26 " 25" 25 " 24" 24 " 23" 23 " 22" 22 " 21" 21 " 20" 20 " 19" 19 " 18" 18 " 17" 17 " 16" 16 " 15" 15 " 14" 14 " 13" 13 " 12" 12 " 11" 11 " 10" 10 " 9" 9 " 8" 8 " 7" 7 " 6" 6 " 5" 5 " 4" 4 " 3" 3 " 2" 2 " 1" 1 " 0 " 0 " Not Active" ;
VAL_ 1121 STAT_AMPSoundFocus 0 " Not Active" ;
VAL_ 1121 STAT_AMPPhoneVolume 31 " Reserved" 30 " Reserved" 29 " Reserved" 28 " Reserved" 27 " Reserved" 26 " 25" 25 " 24" 24 " 23" 23 " 22" 22 " 21" 21 " 20" 20 " 19" 19 " 18" 18 " 17" 17 " 16" 16 " 15" 15 " 14" 14 " 13" 13 " 12" 12 " 11" 11 " 10" 10 " 9" 9 " 8" 8 " 7" 7 " 6" 6 " 5" 5 " 4" 4 " 3" 3 " 2" 2 " 1" 1 " 0 " 0 " Not Active" ;
VAL_ 1121 STAT_AMPMediaVolume 63 " Reserved" 62 " Reserved" 61 " Reserved" 60 " Reserved" 59 " Reserved" 58 " Reserved" 57 " Reserved" 56 " Reserved" 55 " Reserved" 54 " Reserved" 53 " Reserved" 52 " Reserved" 51 " Reserved" 50 " Reserved" 49 " Reserved" 48 " Reserved" 41 " Reserved" 40 " Reserved" 39 " Reserved" 38 " Reserved" 37 " Reserved" 36 " Reserved" 35 " Reserved" 34 " Reserved" 33 " Reserved" 32 " 31" 31 " 30" 30 " 29" 29 " 28" 28 " 27" 27 " 26" 26 " 25" 25 " 24" 24 " 23" 23 " 22" 22 " 21" 21 " 20" 20 " 19" 19 " 18" 18 " 17" 17 " 16" 16 " 15" 15 " 14" 14 " 13" 13 " 12" 12 " 11" 11 " 10" 10 " 9" 9 " 8" 8 " 7" 7 " 6" 6 " 5" 5 " 4" 4 " 3" 3 " 2" 2 " 1" 1 " 0 " 0 " Not Active" ;
VAL_ 1121 STAT_AMPKeyTone 3 " reserved" 2 " OFF" 1 " ON" 0 " Not Active" ;
VAL_ 1121 STAT_AMPVRVolume 15 " Reserved" 14 " Reserved" 13 " Reserved" 12 " Reserved" 11 " 10" 10 " 9" 9 " 8" 8 " 7" 7 " 6" 6 " 5" 5 " 4" 4 " 3" 3 " 2" 2 " 1" 1 " 0 " 0 " Not Active" ;
VAL_ 1121 STAT_AMPNaviVolume 15 " Reserved" 14 " Reserved" 13 " Reserved" 12 " Reserved" 11 " 10" 10 " 9" 9 " 8" 8 " 7" 7 " 6" 6 " 5" 5 " 4" 4 " 3" 3 " 2" 2 " 1" 1 " 0 " 0 " Not Active" ;
VAL_ 1242 TBOX_RsvTravelSts 1 " Open" 0 " Close" ;
VAL_ 1242 TBOX_RsvTravelMin 63 " Reserved" 62 " Reserved" 61 " Reserved" 60 " 59" 59 " 58" 58 " 57" 57 " 56" 56 " 55" 55 " 54" 54 " 53" 53 " 52" 52 " 51" 51 " 50" 50 " 49" 49 " 48" 48 " 47" 47 " 46" 46 " 45" 45 " 44" 44 " 43" 43 " 42" 42 " 41" 41 " 40" 40 " 39" 39 " 38" 38 " 37" 37 " 36" 36 " 35" 35 " 34" 34 " 33" 33 " 32" 32 " 31" 31 " 30" 30 " 29" 29 " 28" 28 " 27" 27 " 26" 26 " 25" 25 " 24" 24 " 23" 23 " 22" 22 " 21" 21 " 20" 20 " 19" 19 " 18" 18 " 17" 17 " 16" 16 " 15" 15 " 14" 14 " 13" 13 " 12" 12 " 11" 11 " 10" 10 " 9" 9 " 8" 8 " 7" 7 " 6" 6 " 5" 5 " 4" 4 " 3" 3 " 2" 2 " 1" 1 " 0" 0 " Reserved" ;
VAL_ 1242 TBOX_RsvTravelHour 31 " Reserved" 30 " Reserved" 29 " Reserved" 28 " Reserved" 27 " Reserved" 26 " Reserved" 25 " Reserved" 24 " 23" 23 " 22" 22 " 21" 21 " 20" 20 " 19" 19 " 18" 18 " 17" 17 " 16" 16 " 15" 15 " 14" 14 " 13" 13 " 12" 12 " 11" 11 " 10" 10 " 9" 9 " 8" 8 " 7" 7 " 6" 6 " 5" 5 " 4" 4 " 3" 3 " 2" 2 " 1" 1 " 0" 0 " Reserved" ;
VAL_ 856 TBOX_ChargeModeSts 3 " Reserved" 2 " Reservation Charge" 1 " Immediate Charge" 0 " No Charge" ;
VAL_ 856 TBOX_ChargeTimeHourFed1 31 " Reserved" 30 " Reserved" 29 " Reserved" 28 " Reserved" 27 " Reserved" 26 " Reserved" 25 "24" 24 "23" 23 "22" 22 "21" 21 "20" 20 "19" 19 "18" 18 "17" 17 "16" 16 "15" 15 "14" 14 "13" 13 "12" 12 "11" 11 "10" 10 " 9" 9 " 8" 8 " 7" 7 " 6" 6 " 5" 5 " 4" 4 " 3" 3 " 2" 2 " 1" 1 " 0" 0 " Reserved" ;
VAL_ 856 TBOX_TimeToStartChargeMinuteFed1 63 " Reserved" 62 " Reserved" 61 " Reserved" 60 " 59" 59 " 58" 58 " 57" 57 " 56" 56 " 55" 55 " 54" 54 " 53" 53 " 52" 52 " 51" 51 " 50" 50 " 49" 49 " 48" 48 " 47" 47 " 46" 46 " 45" 45 " 44" 44 " 43" 43 " 42" 42 " 41" 41 " 40" 40 " 39" 39 " 38" 38 " 37" 37 " 36" 36 " 35" 35 " 34" 34 " 33" 33 " 32" 32 " 31" 31 " 30" 30 " 29" 29 " 28" 28 " 27" 27 " 26" 26 " 25" 25 " 24" 24 " 23" 23 " 22" 22 " 21" 21 " 20" 20 " 19" 19 " 18" 18 " 17" 17 " 16" 16 " 15" 15 " 14" 14 " 13" 13 " 12" 12 " 11" 11 " 10" 10 " 9" 9 " 8" 8 " 7" 7 " 6" 6 " 5" 5 " 4" 4 " 3" 3 " 2" 2 " 1" 1 " 0" 0 " Reserved" ;
VAL_ 856 TBOX_TimeToStartChargeHourFed1 31 " Reserved" 30 " Reserved" 29 " Reserved" 28 " Reserved" 27 " Reserved" 26 " Reserved" 25 " Reserved" 24 " 23" 23 " 22" 22 " 21" 21 " 20" 20 " 19" 19 " 18" 18 " 17" 17 " 16" 16 " 15" 15 " 14" 14 " 13" 13 " 12" 12 " 11" 11 " 10" 10 " 9" 9 " 8" 8 " 7" 7 " 6" 6 " 5" 5 " 4" 4 " 3" 3 " 2" 2 " 1" 1 " 0" 0 " Reserved" ;
VAL_ 1150 APASoftKeyRequest 3 "Invalid" 2 "Reserved" 1 "APA Enter Request" 0 "No request" ;
VAL_ 1150 SET_BSV_Enable 3 "No change" 2 "Reserved" 1 "Enable" 0 "Disenable" ;
VAL_ 1150 IHU_CurrentThemeMode 2 "Auto Mode" 1 "Night Mode" 0 "Day Mode" ;
VAL_ 1150 IHU_CurrentTheme 2 "Theme 3" 1 "Theme 2" 0 "Theme 1" ;
VAL_ 1150 HPA_Voice_Confirmed 1 "confirm" 0 "cancel" ;
VAL_ 1150 HPA_Voice_FuctionSwitch 1 "display HPA interface" 0 "hide HPA interface" ;
VAL_ 1150 MOD_Setting 3 "NO Change" 2 "Reserved" 1 "ON" 0 "OFF" ;
VAL_ 1150 PDCmute_Setting 3 "NO Change" 2 "Reserved" 1 "ON" 0 "OFF" ;
VAL_ 1150 AVMSoftKeyRequest 3 "Invalid" 2 "Reserved" 1 "AVM Enter Request" 0 "No Request" ;
VAL_ 1150 ADAS_tollstation 2 "Reserved" 1 "No" 0 "yes" ;
VAL_ 1092 NavRampInfo 3 "Reserved" 2 "About to leave" 1 "exists" 0 "unknown" ;
VAL_ 1092 NavSpeedLimitType 3 " Reserved" 2 "Recessive" 1 "dominance" 0 "unknown" ;
VAL_ 1092 NavSpeedLimit_EV 34 "180" 33 "160" 32 "150" 31 "145" 30 "130" 29 "120" 28 "113" 27 "110" 26 "100" 25 "97" 24 "90" 23 "80" 22 "72" 21 "70" 20 "65" 19 "64" 18 "60" 17 "56" 16 "55" 15 "50" 14 "48" 13 "45" 12 "40" 11 "35" 10 "32" 9 "30" 8 "25" 7 "24" 6 "20" 5 "16" 4 "15" 3 "10" 0 "not display" ;
VAL_ 1092 NavCountryCodeInfo 45 "CHN ?ß€?" 44 "MYS ????????" 43 "NZL ??????" 42 "AUS ???????" 41 "KOS ??????" 40 "ALB ??????????" 39 "MNE ???" 38 "MKD ???????" 37 "BIH ????" 36 "SRB ???????" 35 "ISR ?????" 34 "TUR ??????" 33 "CHE ???" 32 "NOR ???" 31 " AUT ?¶Ã???" 30 "SWE ???" 29 "SVN ?????????" 28 "SVK ??π§??" 27 "ROU ????????" 26 "PRT ??????" 25 "POL ????" 24 "NLD ????" 23 "MLT ?????" 22 "LVA ???????" 21 "LUX ????" 20 "LTU ??????" 19 "ITA ?????" 18 "IRL ??????" 17 "IMN ?????" 16 "HUN ??????" 15 "HRV ???????" 14 "GIB ???????" 13 "GRC ???" 12 "GBR ???" 11 "FRO ???????" 10 "FRA ????" 9 "FIN ????" 8 "EST ???????" 7 "ESP ??????" 6 "DNK ????" 5 "DEU ?1?" 4 "CZE ???????" 3 "CYP ????°§?" 2 "BGR ????????" 1 "BEL ?????" 0 "None" ;
VAL_ 1330 IHU_29_VoiceReminder 3 "Reserved" 2 "Brief" 1 "Standard" 0 "Not active" ;
VAL_ 1330 IHU_29_SpeedLmtNmberE 63 " reserved" 62 " reserved" 61 " reserved" 60 " reserved" 59 " reserved" 58 " reserved" 41 "20%" 40 "19%" 39 "18%" 38 "17%" 37 "16%" 36 "15%" 35 "14%" 34 "13%" 33 "12%" 32 "11%" 31 "10%" 30 "9%" 29 "8%" 28 "7%" 27 "6%" 26 "5%" 25 "4%" 24 "3%" 23 "2%" 22 "1%" 21 "0%" 20 "-1%" 19 "-2%" 18 "-3%" 17 "-4%" 16 "-5%" 15 "-6%" 14 "-7%" 13 "-8%" 12 "-9%" 11 "-10% " 10 "-11%" 9 "-12%" 8 "-13%" 7 "-14%" 6 "-15%" 5 "-16%" 4 "-17%" 3 "-18%" 2 "-19%" 1 "-20%" 0 "No display" ;
VAL_ 1330 IHU_29_SpeedLmtNmberAb 63 "reserved" 62 "reserved" 61 "reserved" 60 "reserved" 59 "reserved" 58 "reserved" 57 "reserved" 56 "reserved" 55 "reserved" 54 "reserved" 53 "reserved" 52 "reserved" 51 "reserved" 50 "reserved" 49 "reserved" 48 "reserved" 47 "reserved" 46 "reserved" 45 "reserved" 44 "reserved" 43 "reserved" 42 "reserved" 41 "reserved" 40 "reserved" 39 "reserved" 38 "reserved" 37 "reserved" 36 "reserved" 35 "reserved" 34 "reserved" 33 "reserved" 32 "reserved" 31 "reserved" 30 "reserved" 29 "reserved" 28 "reserved" 27 "reserved" 26 "reserved" 25 "reserved" 24 "reserved" 23 "reserved" 22 "reserved" 10 "-1" 9 "-2" 8 "-3" 7 "-4" 6 "-5" 5 "-6" 4 "-7" 3 "-8" 2 "-9" 1 "-10" 0 "No display" ;
VAL_ 1330 IHU_29_SLAMode 3 " Reserved" 2 " Relative" 1 " Absolute" 0 " Not active" ;
VAL_ 1330 ShowRoomSwt 3 " Reserved" 2 " Open" 1 " Close" 0 " Not Active" ;
VAL_ 1330 SLASpdlimitWarningAudSWSet 3 " Not Used" 2 " OFF" 1 " ON" 0 " Not Active" ;
VAL_ 1330 SLWFONOFFSet 3 " Not Used" 2 " OFF" 1 " ON" 0 " Not Active" ;
VAL_ 1330 IHU_29_DchaSet 2 "Disable" 1 "Enable" 0 "Not active" ;
VAL_ 1330 ElectcUnlckCmd 1 "Active" 0 "Not Active" ;
VAL_ 1330 IHU_29_ChrgElecLockSwt 3 "Not used" 2 "Lock" 1 "Unlock" 0 "Not Active" ;
VAL_ 1330 IHU_29_ChrgStopSoc 255 "Invalid" 254 "Abnormal
(254)" 0 "Not Active(0)" ;
VAL_ 1330 IHU_29_V2LStopSoc 255 "Invalid" 254 "Abnormal
(254)" 0 "Not Active(0)" ;
VAL_ 1330 IHU_29_KeepWrmSwt 3 "Not used" 2 "ON" 1 "OFF" 0 "Not Active" ;
VAL_ 1330 IHU_29_V2LSwt 3 "Not used" 2 "ON" 1 "OFF" 0 "Not Active" ;
VAL_ 1330 IHU_29_V2LFctSwt 3 "Not used" 2 "ON" 1 "OFF" 0 "Not Active" ;
VAL_ 1330 IHU_29_TowMod 3 "Not used" 2 "ON" 1 "OFF" 0 "Not Active" ;
VAL_ 1406 IACC_Need_Confirm_Swtich 3 "No change" 2 "Reserved" 1 "Need confirm" 0 "No need confirm" ;
VAL_ 1406 NaviPilot_start 1 "navigation on" 0 "navigation off" ;
VAL_ 1406 NaviPilot_status 1 "valid" 0 "invalid" ;
VAL_ 1406 NaviPilot_side_along_suggestion 1 "right" 0 "left" ;
VAL_ 1406 NaviPilot_2nd_Ramp_on 1 "in scope" 0 "not in scope yet" ;
VAL_ 1406 NaviPilot_1stEntry_Lane_end 1 "in scope" 0 "not in scope yet" ;
VAL_ 1406 NaviPilot_1st_Ramp_on 1 "in scope" 0 "not in scope yet" ;
VAL_ 1406 NaviPilot_Is_Ramp 1 "ramp" 0 "not ramp" ;
VAL_ 1406 NaviPilot_Is_Tunnel 1 "tunnel" 0 "not tunnel" ;
VAL_ 1406 NaviPilot_Current_Roadgrade 3 "Ordinary road" 2 "City express way" 1 "Highway" 0 "undefined" ;
VAL_ 1406 NaviPilot_1st_Exit_traffic_jam 1 "traffic jam" 0 "no traffic jam" ;
VAL_ 1406 NaviPilot_2nd_Exit_lane 1 "in scope" 0 "no further exit or not in scope" ;
VAL_ 1406 NaviPilot_1st_Exit_lane 1 "in scope" 0 "not in scope yet" ;
VAL_ 1177 IHU_26_RRWinCmd 127 "Reserved" 126 "Reserved" 125 "Reserved" 124 "Reserved" 123 "Reserved" 122 "Reserved" 121 "Reserved" 120 "Reserved" 119 "Reserved" 118 "Reserved" 117 "Reserved" 116 "Reserved" 115 "Reserved" 114 "Reserved" 113 "Reserved" 112 "Reserved" 111 "Reserved" 110 "Reserved" 109 "Reserved" 108 "Reserved" 107 "Reserved" 106 "Reserved" 105 "Reserved" 104 "Reserved" 103 "Reserved" 102 "Reserved" 101 "Reserved" 100 "100%" 99 "99%" 98 "98%" 97 "97%" 96 "96%" 95 "95%" 94 "94%" 93 "93%" 92 "92%" 91 "91%" 90 "90%" 89 "89%" 88 "88%" 87 "87%" 86 "86%" 85 "85%" 84 "84%" 83 "83%" 82 "82%" 81 "81%" 80 "80%" 79 "79%" 78 "78%" 77 "77%" 76 "76%" 75 "75%" 74 "74%" 73 "73%" 72 "72%" 71 "71%" 70 "70%" 69 "69%" 68 "68%" 67 "67%" 66 "66%" 65 "65%" 64 "64%" 63 "63%" 62 "62%" 61 "61%" 60 "60%" 59 "59%" 58 "58%" 57 "57%" 56 "56%" 55 "55%" 54 "54%" 53 "53%" 52 "52%" 51 "51%" 50 "50%" 49 "49%" 48 "48%" 47 "47%" 46 "46%" 45 "45%" 44 "44%" 43 "43%" 42 "42%" 41 "41%" 40 "40%" 39 "39%" 38 "38%" 37 "37%" 36 "36%" 35 "35%" 34 "34%" 33 "33%" 32 "32%" 31 "31%" 30 "30%" 29 "29%" 28 "28%" 27 "27%" 26 "26%" 25 "25%" 24 "24%" 23 "23%" 22 "22%" 21 "21%" 20 "20%" 19 "19%" 18 "18%" 17 "17%" 16 "16%" 15 "15%" 14 "14%" 13 "13%" 12 "12%" 11 "11%" 10 "10%" 9 "9%" 8 "8%" 7 "7%" 6 "6%" 5 "5%" 4 "4%" 3 "3%" 2 "2%" 1 "1%" 0 "Not active" ;
VAL_ 1177 IHU_26_WiprSnvty 6 "Reserved" 5 "Reserved" 4 "Level4" 3 "Level3" 2 "Level2" 1 "Level1" 0 "Not Active" ;
VAL_ 1177 IHU_26_SeatLegSpprtPosnCmd 15 "Reserved" 14 "Reserved" 13 "Reserved" 12 "Reserved" 11 "100%" 10 "90% " 9 "80% " 8 "70% " 7 "60% " 6 "50% " 5 "40% " 4 "30% " 3 "20% " 2 "10% " 1 "0% " 0 "Not active " ;
VAL_ 1177 IHU_26_RLWinCmd 127 "Reserved" 126 "Reserved" 125 "Reserved" 124 "Reserved" 123 "Reserved" 122 "Reserved" 121 "Reserved" 120 "Reserved" 119 "Reserved" 118 "Reserved" 117 "Reserved" 116 "Reserved" 115 "Reserved" 114 "Reserved" 113 "Reserved" 112 "Reserved" 111 "Reserved" 110 "Reserved" 109 "Reserved" 108 "Reserved" 107 "Reserved" 106 "Reserved" 105 "Reserved" 104 "Reserved" 103 "Reserved" 102 "Reserved" 101 "Reserved" 100 "100%" 99 "99%" 98 "98%" 97 "97%" 96 "96%" 95 "95%" 94 "94%" 93 "93%" 92 "92%" 91 "91%" 90 "90%" 89 "89%" 88 "88%" 87 "87%" 86 "86%" 85 "85%" 84 "84%" 83 "83%" 82 "82%" 81 "81%" 80 "80%" 79 "79%" 78 "78%" 77 "77%" 76 "76%" 75 "75%" 74 "74%" 73 "73%" 72 "72%" 71 "71%" 70 "70%" 69 "69%" 68 "68%" 67 "67%" 66 "66%" 65 "65%" 64 "64%" 63 "63%" 62 "62%" 61 "61%" 60 "60%" 59 "59%" 58 "58%" 57 "57%" 56 "56%" 55 "55%" 54 "54%" 53 "53%" 52 "52%" 51 "51%" 50 "50%" 49 "49%" 48 "48%" 47 "47%" 46 "46%" 45 "45%" 44 "44%" 43 "43%" 42 "42%" 41 "41%" 40 "40%" 39 "39%" 38 "38%" 37 "37%" 36 "36%" 35 "35%" 34 "34%" 33 "33%" 32 "32%" 31 "31%" 30 "30%" 29 "29%" 28 "28%" 27 "27%" 26 "26%" 25 "25%" 24 "24%" 23 "23%" 22 "22%" 21 "21%" 20 "20%" 19 "19%" 18 "18%" 17 "17%" 16 "16%" 15 "15%" 14 "14%" 13 "13%" 12 "12%" 11 "11%" 10 "10%" 9 "9%" 8 "8%" 7 "7%" 6 "6%" 5 "5%" 4 "4%" 3 "3%" 2 "2%" 1 "1%" 0 "Not active" ;
VAL_ 1177 IHU_26_FRWinCmd 127 "Reserved" 126 "Reserved" 125 "Reserved" 124 "Reserved" 123 "Reserved" 122 "Reserved" 121 "Reserved" 120 "Reserved" 119 "Reserved" 118 "Reserved" 117 "Reserved" 116 "Reserved" 115 "Reserved" 114 "Reserved" 113 "Reserved" 112 "Reserved" 111 "Reserved" 110 "Reserved" 109 "Reserved" 108 "Reserved" 107 "Reserved" 106 "Reserved" 105 "Reserved" 104 "Reserved" 103 "Reserved" 102 "Reserved" 101 "Reserved" 100 "100%" 99 "99%" 98 "98%" 97 "97%" 96 "96%" 95 "95%" 94 "94%" 93 "93%" 92 "92%" 91 "91%" 90 "90%" 89 "89%" 88 "88%" 87 "87%" 86 "86%" 85 "85%" 84 "84%" 83 "83%" 82 "82%" 81 "81%" 80 "80%" 79 "79%" 78 "78%" 77 "77%" 76 "76%" 75 "75%" 74 "74%" 73 "73%" 72 "72%" 71 "71%" 70 "70%" 69 "69%" 68 "68%" 67 "67%" 66 "66%" 65 "65%" 64 "64%" 63 "63%" 62 "62%" 61 "61%" 60 "60%" 59 "59%" 58 "58%" 57 "57%" 56 "56%" 55 "55%" 54 "54%" 53 "53%" 52 "52%" 51 "51%" 50 "50%" 49 "49%" 48 "48%" 47 "47%" 46 "46%" 45 "45%" 44 "44%" 43 "43%" 42 "42%" 41 "41%" 40 "40%" 39 "39%" 38 "38%" 37 "37%" 36 "36%" 35 "35%" 34 "34%" 33 "33%" 32 "32%" 31 "31%" 30 "30%" 29 "29%" 28 "28%" 27 "27%" 26 "26%" 25 "25%" 24 "24%" 23 "23%" 22 "22%" 21 "21%" 20 "20%" 19 "19%" 18 "18%" 17 "17%" 16 "16%" 15 "15%" 14 "14%" 13 "13%" 12 "12%" 11 "11%" 10 "10%" 9 "9%" 8 "8%" 7 "7%" 6 "6%" 5 "5%" 4 "4%" 3 "3%" 2 "2%" 1 "1%" 0 "Not active" ;
VAL_ 1177 IHU_26_FLWinCmd 127 "Reserved" 126 "Reserved" 125 "Reserved" 124 "Reserved" 123 "Reserved" 122 "Reserved" 121 "Reserved" 120 "Reserved" 119 "Reserved" 118 "Reserved" 117 "Reserved" 116 "Reserved" 115 "Reserved" 114 "Reserved" 113 "Reserved" 112 "Reserved" 111 "Reserved" 110 "Reserved" 109 "Reserved" 108 "Reserved" 107 "Reserved" 106 "Reserved" 105 "Reserved" 104 "Reserved" 103 "Reserved" 102 "Reserved" 101 "Reserved" 100 "100%" 99 "99%" 98 "98%" 97 "97%" 96 "96%" 95 "95%" 94 "94%" 93 "93%" 92 "92%" 91 "91%" 90 "90%" 89 "89%" 88 "88%" 87 "87%" 86 "86%" 85 "85%" 84 "84%" 83 "83%" 82 "82%" 81 "81%" 80 "80%" 79 "79%" 78 "78%" 77 "77%" 76 "76%" 75 "75%" 74 "74%" 73 "73%" 72 "72%" 71 "71%" 70 "70%" 69 "69%" 68 "68%" 67 "67%" 66 "66%" 65 "65%" 64 "64%" 63 "63%" 62 "62%" 61 "61%" 60 "60%" 59 "59%" 58 "58%" 57 "57%" 56 "56%" 55 "55%" 54 "54%" 53 "53%" 52 "52%" 51 "51%" 50 "50%" 49 "49%" 48 "48%" 47 "47%" 46 "46%" 45 "45%" 44 "44%" 43 "43%" 42 "42%" 41 "41%" 40 "40%" 39 "39%" 38 "38%" 37 "37%" 36 "36%" 35 "35%" 34 "34%" 33 "33%" 32 "32%" 31 "31%" 30 "30%" 29 "29%" 28 "28%" 27 "27%" 26 "26%" 25 "25%" 24 "24%" 23 "23%" 22 "22%" 21 "21%" 20 "20%" 19 "19%" 18 "18%" 17 "17%" 16 "16%" 15 "15%" 14 "14%" 13 "13%" 12 "12%" 11 "11%" 10 "10%" 9 "9%" 8 "8%" 7 "7%" 6 "6%" 5 "5%" 4 "4%" 3 "3%" 2 "2%" 1 "1%" 0 "Not active" ;
VAL_ 1177 ChrgPortCover_Switch 1 " Active" 0 " Not active" ;
VAL_ 1177 IHU_26_CenterLockSwt 3 " Reserved" 2 " LOCK" 1 " UNLOCK" 0 " Not Active" ;
VAL_ 1177 IHU_26_SeatLvlPosnCmd 15 "Reserved" 14 "Reserved" 13 "Reserved" 12 "Reserved" 11 "100%" 10 "90% " 9 "80% " 8 "70% " 7 "60% " 6 "50% " 5 "40% " 4 "30% " 3 "20% " 2 "10% " 1 "0% " 0 "Not active " ;
VAL_ 1177 IHU_26_SeatHdrestHeiAdjmtCmd 15 "Reserved" 14 "Reserved" 13 "Reserved" 12 "Reserved" 11 "Reserved" 10 "100%" 9 "90%" 8 "80%" 7 "70%" 6 "60%" 5 "50%" 4 "40%" 3 "30%" 2 "20%" 1 "10%" 0 "Not active" ;
VAL_ 1177 IHU_26_WinInhbSwt 1 " Active" 0 " Not active" ;
VAL_ 1177 IHU_26_ReWinDefrstSwt 1 " Active" 0 " Not active" ;
VAL_ 1177 IHU_26_SteerWhlHeatgSwt 1 " Active" 0 " Not active" ;
VAL_ 1177 IHU_26_BackrAgPosnCmd 31 "Reserved" 30 "Reserved" 29 "Reserved" 28 "Reserved" 27 "Reserved" 26 "Reserved" 25 "Reserved" 24 "Reserved" 23 "Reserved" 22 "Reserved" 21 "100%" 20 "95%" 19 "90%" 18 "85%" 17 "80%" 16 "75%" 15 "70%" 14 "65%" 13 "60%" 12 "55%" 11 "50%" 10 "45% " 9 "40% " 8 "35% " 7 "30% " 6 "25% " 5 "20% " 4 "15% " 3 "10% " 2 "5% " 1 "0% " 0 "Not active " ;
VAL_ 1177 IHU_26_SeatCushPosnCmd 15 "Reserved" 14 "Reserved" 13 "Reserved" 12 "Reserved" 11 "Reserved" 10 "100%" 9 "90%" 8 "80%" 7 "70%" 6 "60%" 5 "50%" 4 "40%" 3 "30%" 2 "20%" 1 "10%" 0 "Not active" ;
VAL_ 1177 IHU_26_SeatHeiPosnCmd 15 "Reserved" 14 "Reserved" 13 "Reserved" 12 "Reserved" 11 "100%" 10 "90% " 9 "80% " 8 "70% " 7 "60% " 6 "50% " 5 "40% " 4 "30% " 3 "20% " 2 "10% " 1 "0% " 0 "Not active " ;
VAL_ 643 IHU_25_APPsts 1 " Active" 0 " Not Active" ;
VAL_ 643 IHU_25_AmbLigFlngModSel 7 " mode7" 6 " mode6" 5 " mode5" 4 " mode4" 3 " mode3" 2 " mode2" 1 " mode1" 0 " Not Active" ;
VAL_ 643 IHU_25_AmbLig14FlngEna 1 " Active" 0 " Not Active" ;
VAL_ 643 IHU_25_AmbLig13FlngEna 1 " Active" 0 " Not Active" ;
VAL_ 643 IHU_25_AmbLig12FlngEna 1 " Active" 0 " Not Active" ;
VAL_ 643 IHU_25_AmbLig14FadeEna 1 " Active" 0 " Not Active" ;
VAL_ 643 IHU_25_AmbLig13FadeEna 1 " Active" 0 " Not Active" ;
VAL_ 643 IHU_25_AmbLig12FadeEna 1 " Active" 0 " Not Active" ;
VAL_ 643 IHU_25_AmbLig11FadeEna 1 " Active" 0 " Not Active" ;
VAL_ 643 IHU_25_AmbLig10FadeEna 1 " Active" 0 " Not Active" ;
VAL_ 643 IHU_25_AmbLig09FadeEna 1 " Active" 0 " Not Active" ;
VAL_ 643 IHU_25_AmbLig08FadeEna 1 " Active" 0 " Not Active" ;
VAL_ 643 IHU_25_AmbLig07FadeEna 1 " Active" 0 " Not Active" ;
VAL_ 643 IHU_25_AmbLig06FadeEna 1 " Active" 0 " Not Active" ;
VAL_ 643 IHU_25_AmbLig05FadeEna 1 " Active" 0 " Not Active" ;
VAL_ 643 IHU_25_AmbLig04FadeEna 1 " Active" 0 " Not Active" ;
VAL_ 643 IHU_25_AmbLig03FadeEna 1 " Active" 0 " Not Active" ;
VAL_ 643 IHU_25_AmbLig02FadeEna 1 " Active" 0 " Not Active" ;
VAL_ 643 IHU_25_AmbLig01FadeEna 1 " Active" 0 " Not Active" ;
VAL_ 643 IHU_25_AmbLig14Authn 1 " Active" 0 " Not Active" ;
VAL_ 643 IHU_25_AmbLig13Authn 1 " Active" 0 " Not Active" ;
VAL_ 643 IHU_25_AmbLig12Authn 1 " Active" 0 " Not Active" ;
VAL_ 643 IHU_25_AmbLig11Authn 1 " Active" 0 " Not Active" ;
VAL_ 643 IHU_25_AmbLig10Authn 1 " Active" 0 " Not Active" ;
VAL_ 643 IHU_25_AmbLig09Authn 1 " Active" 0 " Not Active" ;
VAL_ 643 IHU_25_AmbLig08Authn 1 " Active" 0 " Not Active" ;
VAL_ 643 IHU_25_AmbLig07Authn 1 " Active" 0 " Not Active" ;
VAL_ 643 IHU_25_AmbLig06Authn 1 " Active" 0 " Not Active" ;
VAL_ 643 IHU_25_AmbLig05Authn 1 " Active" 0 " Not Active" ;
VAL_ 643 IHU_25_AmbLig04Authn 1 " Active" 0 " Not Active" ;
VAL_ 643 IHU_25_AmbLig03Authn 1 " Active" 0 " Not Active" ;
VAL_ 643 IHU_25_AmbLig02Authn 1 " Active" 0 " Not Active" ;
VAL_ 643 IHU_25_AmbLig01Authn 1 " Active" 0 " Not Active" ;
VAL_ 1244 PassSeatMsgModeCmd 5 "Jump Mode" 4 "Relieve Mode" 3 "Cross Mode" 2 "Cat Paw Mode" 1 "Wave Mode" 0 "Not Active" ;
VAL_ 1244 PassSeatMsgStr_LvlCmd 4 "High" 3 "Middle" 2 "Low" 1 "OFF" 0 "NotActive" ;
VAL_ 1244 IHU_24_SetHUDRot 15 "Reserved" 14 "Reserved" 13 "Reserved" 12 "Reserved" 11 "2.0" 10 "1.6" 9 "1.2" 8 "0.8" 7 "0.4" 5 "-0.4" 4 "-0.8" 3 "-1.2" 2 "-1.6" 1 "-2" 0 "Not Active" ;
VAL_ 1244 AUTODefrostlevelKeySts 4 "high" 3 "middle" 2 "low" 1 "Off" 0 "Not Active" ;
VAL_ 1244 DriverSeatMsg_ModeCmd 7 "Reserved" 6 "Reserved" 5 "JumpMode" 4 "Relieve Mode" 3 "CrossMode" 2 "Cat PawMode" 1 "WaveMode" 0 "NotActive" ;
VAL_ 1244 DriverSeatMsgStr_Lvlcmd 7 "reserved" 6 "reserved" 5 "reserved" 4 "High" 3 "Middle" 2 "Low" 1 "OFF" 0 "NotActive" ;
VAL_ 1244 IHU_24_SetAdasDisp 3 "Reserved" 2 "Display " 1 "No Display" 0 "No Active" ;
VAL_ 1244 IHU_24_SetBlueToothDisp 3 "Reserved" 2 "Display " 1 "No Display" 0 "No Active" ;
VAL_ 1244 IHU_24_SetFaceIdOnoff 3 "Reserved" 2 "OFF" 1 "ON" 0 "No Active" ;
VAL_ 1244 IHU_24_PwrOff 1 "Active" 0 "No active" ;
VAL_ 1244 IHU_RearFogLightSwtCmd 1 " Active" 0 " Not active" ;
VAL_ 1244 IHU_FrntFogLightSwtCmd 1 " Active" 0 " Not active" ;
VAL_ 1244 IHU_24_SetAdasDispPoision 7 "Reserved" 6 "Reserved" 5 "Reserved" 4 "Invalid" 3 "Ignore" 2 "ADAS right" 1 "ADAS left" 0 "Not Active" ;
VAL_ 1244 IHU_24_SetNavDisp 3 "Reserved" 2 "Display " 1 "No Display" 0 "No Active" ;
VAL_ 1244 IHU_24_SetHudBri 15 "Ignore" 14 "Reserved" 13 "Reserved" 12 "Reserved" 11 "Reserved" 10 "Level10" 9 "Level9" 8 "Level8" 7 "Level7" 6 "Level6" 5 "Level5" 4 "Level4" 3 "Level3" 2 "Level2" 1 "Level1" 0 "Not Active" ;
VAL_ 1244 IHU_24_SetHudDispMod 3 "sport" 2 "snowy" 1 "normal" 0 "Not Active" ;
VAL_ 1244 IHU_LightMainSwitchCmd 4 "LowBeamSwitch" 3 "PositionLampSwitch" 2 "Auto" 1 "Off" 0 "Not active" ;
VAL_ 1244 IHU_24_SetHudHei 15 "Ignore" 14 "Reserved" 13 "Reserved" 12 "Reserved" 11 "Reserved" 10 "Level10" 9 "Level9" 8 "Level8" 7 "Level7" 6 "Level6" 5 "Level5" 4 "Level4" 3 "Level3" 2 "Level2" 1 "Level1" 0 "Not Active" ;
VAL_ 1244 IHU_24_SetHudDispOnOff 4 "Invalid" 3 "IgnoreAJ545:AJ549" 2 "ON" 1 "OFF" 0 "Not Active" ;
VAL_ 1035 IHU_OTAPwrMngt 7 " Reserved" 6 " Reserved" 5 " Reserved" 4 " Reserved" 3 " Continuous ON" 2 " Power On" 1 " Power Off" 0 " No Request" ;
VAL_ 1035 IHU_OTAHvReq 3 " Reserved" 2 " Power Up" 1 " Power Down" 0 " No Request" ;
VAL_ 1035 IHU_OTASts 3 " Reserved" 2 " Reserved" 1 " OTA Status" 0 " Normal Status" ;
VAL_ 1278 IHU_22_DispEvDteTyp 3 " Dynamic Mileage" 2 " Standard Mileage" 1 " Electric Power" 0 " Not Active" ;
VAL_ 1278 IHU_22_DispPwrMod 3 "EV Mileage" 2 " HEV Mileage" 1 " ODO" 0 " Not Active" ;
VAL_ 1278 IHU_22_RCCPInhbSwt 1 " Active" 0 " Not Active" ;
VAL_ 1278 IHU_22_FRSeatAutVentnCmd 3 " Reserved" 2 " OFF" 1 " ON" 0 " Not Active" ;
VAL_ 1278 IHU_22_FLSeatAutVentnCmd 3 " Reserved" 2 " OFF" 1 " ON" 0 " Not Active" ;
VAL_ 1278 IHU_22_FRSeatAutHeatCmd 3 " Reserved" 2 " OFF" 1 " ON" 0 " Not Active" ;
VAL_ 1278 IHU_22_FLSeatAutHeatCmd 3 " Reserved" 2 " OFF" 1 " ON" 0 " Not Active" ;
VAL_ 1278 SHU3RSeatVentilationCmd 7 " Reserved" 6 " Reserved" 5 " Reserved" 4 " Seat Ventilation Level3" 3 " Seat Ventilation Level2" 2 " Seat Ventilation Level1" 1 " OFF" 0 " Not Active" ;
VAL_ 1278 SHU3LSeatVentilationCmd 7 " Reserved" 6 " Reserved" 5 " Reserved" 4 " Seat Ventilation Level3" 3 " Seat Ventilation Level2" 2 " Seat Ventilation Level1" 1 " OFF" 0 " Not Active" ;
VAL_ 1278 SHU3RSeatHeatLevelCmd 7 " Reserved" 6 " Reserved" 5 " Reserved" 4 " Seat heating Level3" 3 " Seat heating Level2" 2 " Seat heating Level1" 1 " OFF" 0 " Not Active" ;
VAL_ 1278 SHU3LSeatHeatLevelCmd 7 " Reserved" 6 " Reserved" 5 " Reserved" 4 " Seat heating Level3" 3 " Seat heating Level2" 2 " Seat heating Level1" 1 " OFF" 0 " Not Active" ;
VAL_ 1278 SHU2RSeatVentilationCmd 7 " Reserved" 6 " Reserved" 5 " Reserved" 4 " Seat Ventilation Level3" 3 " Seat Ventilation Level2" 2 " Seat Ventilation Level1" 1 " OFF" 0 " Not Active" ;
VAL_ 1278 SHU2MSeatVentilationCmd 7 " Reserved" 6 " Reserved" 5 " Reserved" 4 " Seat Ventilation Level3" 3 " Seat Ventilation Level2" 2 " Seat Ventilation Level1" 1 " OFF" 0 " Not Active" ;
VAL_ 1278 SHU2LSeatVentilationCmd 7 " Reserved" 6 " Reserved" 5 " Reserved" 4 " Seat Ventilation Level3" 3 " Seat Ventilation Level2" 2 " Seat Ventilation Level1" 1 " OFF" 0 " Not Active" ;
VAL_ 1278 SHU2RSeatHeatLevelCmd 7 " Reserved" 6 " Reserved" 5 " Reserved" 4 " Seat heating Level3" 3 " Seat heating Level2" 2 " Seat heating Level1" 1 " OFF" 0 " Not Active" ;
VAL_ 1278 SHU2MSeatHeatLevelCmd 7 " Reserved" 6 " Reserved" 5 " Reserved" 4 " Seat heating Level3" 3 " Seat heating Level2" 2 " Seat heating Level1" 1 " OFF" 0 " Not Active" ;
VAL_ 1278 SHU2LSeatHeatLevelCmd 7 " Reserved" 6 " Reserved" 5 " Reserved" 4 " Seat heating Level3" 3 " Seat heating Level2" 2 " Seat heating Level1" 1 " OFF" 0 " Not Active" ;
VAL_ 1278 IHU_22_FRSeatVentilationCmd 7 " Reserved" 6 " Reserved" 5 " Reserved" 4 " Seat Ventilation Level3" 3 " Seat Ventilation Level2" 2 " Seat Ventilation Level1" 1 " OFF" 0 " Not Active" ;
VAL_ 1278 IHU_22_FLSeatVentilationCmd 7 " Reserved" 6 " Reserved" 5 " Reserved" 4 " Seat Ventilation Level3" 3 " Seat Ventilation Level2" 2 " Seat Ventilation Level1" 1 " OFF" 0 " Not Active" ;
VAL_ 1278 IHU_22_FRSeatHeatLevelCmd 7 " Reserved" 6 " Reserved" 5 " Reserved" 4 " Seat heating Level3" 3 " Seat heating Level2" 2 " Seat heating Level1" 1 " OFF" 0 " Not Active" ;
VAL_ 1278 IHU_22_FLSeatHeatLevelCmd 7 " Reserved" 6 " Reserved" 5 " Reserved" 4 " Seat heating Level3" 3 " Seat heating Level2" 2 " Seat heating Level1" 1 " OFF" 0 " Not Active" ;
VAL_ 1155 IHU_setRsvTravelSts 3 " Not used" 2 " Open" 1 " Close" 0 " Not Active" ;
VAL_ 1155 IHU_setRsvTravelMin 63 " Reserved" 62 " Reserved" 61 " Reserved" 60 " 59" 59 " 58" 58 " 57" 57 " 56" 56 " 55" 55 " 54" 54 " 53" 53 " 52" 52 " 51" 51 " 50" 50 " 49" 49 " 48" 48 " 47" 47 " 46" 46 " 45" 45 " 44" 44 " 43" 43 " 42" 42 " 41" 41 " 40" 40 " 39" 39 " 38" 38 " 37" 37 " 36" 36 " 35" 35 " 34" 34 " 33" 33 " 32" 32 " 31" 31 " 30" 30 " 29" 29 " 28" 28 " 27" 27 " 26" 26 " 25" 25 " 24" 24 " 23" 23 " 22" 22 " 21" 21 " 20" 20 " 19" 19 " 18" 18 " 17" 17 " 16" 16 " 15" 15 " 14" 14 " 13" 13 " 12" 12 " 11" 11 " 10" 10 " 9" 9 " 8" 8 " 7" 7 " 6" 6 " 5" 5 " 4" 4 " 3" 3 " 2" 2 " 1" 1 " 0" 0 " Not Active" ;
VAL_ 1155 IHU_setRsvTravelHour 31 " Reserved" 30 " Reserved" 29 " Reserved" 28 " Reserved" 27 " Reserved" 26 " Reserved" 25 " Reserved" 24 " 23" 23 " 22" 22 " 21" 21 " 20" 20 " 19" 19 " 18" 18 " 17" 17 " 16" 16 " 15" 15 " 14" 14 " 13" 13 " 12" 12 " 11" 11 " 10" 10 " 9" 9 " 8" 8 " 7" 7 " 6" 6 " 5" 5 " 4" 4 " 3" 3 " 2" 2 " 1" 1 " 0" 0 " Not Active" ;
VAL_ 1480 NextTrafficSts 3 " Invalid" 2 "Heavy traffic jam" 1 " Normal traffic jam" 0 "Smooth traffic" ;
VAL_ 1480 TrafficSts 3 " Invalid" 2 "Heavy traffic jam" 1 " Normal traffic jam" 0 "Smooth traffic" ;
VAL_ 1119 IHU_19_Set_HdrestSpkrMod 7 "reserved" 6 "reserved " 5 "reserved" 4 "reserved" 3 "Private mode" 2 "Drive mode" 1 "Shared mode" 0 "Not Active" ;
VAL_ 1119 IHU_19_Set_AMPESEVol 63 " Reserved" 62 " Reserved" 61 " Reserved" 60 " Reserved" 59 " Reserved" 58 " Reserved" 57 " Reserved" 56 " Reserved" 55 " Reserved" 54 " Reserved" 53 " Reserved" 52 " Reserved" 51 " Reserved" 50 " Reserved" 49 " Reserved" 48 " Reserved" 41 " Reserved" 40 " Reserved" 39 " Reserved" 38 " Reserved" 37 " Reserved" 36 " Reserved" 35 " Reserved" 34 " Reserved" 33 " Reserved" 32 " 31" 31 " 30" 30 " 29" 29 " 28" 28 " 27" 27 " 26" 26 " 25" 25 " 24" 24 " 23" 23 " 22" 22 " 21" 21 " 20" 20 " 19" 19 " 18" 18 " 17" 17 " 16" 16 " 15" 15 " 14" 14 " 13" 13 " 12" 12 " 11" 11 " 10" 10 " 9" 9 " 8" 8 " 7" 7 " 6" 6 " 5" 5 " 4" 4 " 3" 3 " 2" 2 " 1" 1 " 0 " 0 " Not Active" ;
VAL_ 1119 IHU_19_Set_AMPWelVol 63 " Reserved" 62 " Reserved" 61 " Reserved" 60 " Reserved" 59 " Reserved" 58 " Reserved" 57 " Reserved" 56 " Reserved" 55 " Reserved" 54 " Reserved" 53 " Reserved" 52 " Reserved" 51 " Reserved" 50 " Reserved" 49 " Reserved" 48 " Reserved" 41 " Reserved" 40 " Reserved" 39 " Reserved" 38 " Reserved" 37 " Reserved" 36 " Reserved" 35 " Reserved" 34 " Reserved" 33 " Reserved" 32 " 31" 31 " 30" 30 " 29" 29 " 28" 28 " 27" 27 " 26" 26 " 25" 25 " 24" 24 " 23" 23 " 22" 22 " 21" 21 " 20" 20 " 19" 19 " 18" 18 " 17" 17 " 16" 16 " 15" 15 " 14" 14 " 13" 13 " 12" 12 " 11" 11 " 10" 10 " 9" 9 " 8" 8 " 7" 7 " 6" 6 " 5" 5 " 4" 4 " 3" 3 " 2" 2 " 1" 1 " 0 " 0 " Not Active" ;
VAL_ 1119 IHU_19_Set_AMPBTMediVol 63 " Reserved" 62 " Reserved" 61 " Reserved" 60 " Reserved" 59 " Reserved" 58 " Reserved" 57 " Reserved" 56 " Reserved" 55 " Reserved" 54 " Reserved" 53 " Reserved" 52 " Reserved" 51 " Reserved" 50 " Reserved" 49 " Reserved" 48 " Reserved" 41 " Reserved" 40 " Reserved" 39 " Reserved" 38 " Reserved" 37 " Reserved" 36 " Reserved" 35 " Reserved" 34 " Reserved" 33 " Reserved" 32 " 31" 31 " 30" 30 " 29" 29 " 28" 28 " 27" 27 " 26" 26 " 25" 25 " 24" 24 " 23" 23 " 22" 22 " 21" 21 " 20" 20 " 19" 19 " 18" 18 " 17" 17 " 16" 16 " 15" 15 " 14" 14 " 13" 13 " 12" 12 " 11" 11 " 10" 10 " 9" 9 " 8" 8 " 7" 7 " 6" 6 " 5" 5 " 4" 4 " 3" 3 " 2" 2 " 1" 1 " 0 " 0 " Not Active" ;
VAL_ 1119 IHU_19_REQ_AMPA2BMediSound 7 "reserved" 6 "reserved " 5 "reserved" 4 " OFF" 3 " Welcome" 2 " BT Media" 1 " Media" 0 " Not Active" ;
VAL_ 1119 IHU_19_REQ_AMPA2BESESound 3 " reserved" 2 " OFF" 1 " ON" 0 " Not Active" ;
VAL_ 1119 IHU_19_PABSetCmd 3 " Not Used" 2 " PAB ON Cmd           " 1 " PAB OFF Cmd" 0 " Not Active" ;
VAL_ 1119 IHU_19_HwSet 3 " Not Used" 2 " OFF                                   " 1 " ON" 0 " Not Active" ;
VAL_ 1119 IHU_19_BSRBPASet 3 " Not Used" 2 " OFF                                  " 1 " ON" 0 " Not Active" ;
VAL_ 1119 REQ_AMPA2BKeyTone 3 " reserved" 2 " OFF" 1 " ON" 0 " Not Active" ;
VAL_ 1119 REQ_AMPA2BTTSSound 3 " reserved" 2 " OFF" 1 " ON" 0 " Not Active" ;
VAL_ 1119 REQ_AMPA2BVRSound 3 " SIRI" 2 " OFF" 1 " ON(VR)" 0 " Not Active" ;
VAL_ 1119 REQ_AMPA2BNaviSound 3 " reserved" 2 " OFF" 1 " ON" 0 " Not Active" ;
VAL_ 1119 REQ_AMPA2BMediaSound 3 " reserved" 2 " OFF" 1 " ON" 0 " Not Active" ;
VAL_ 1119 Set_AMPMute 3 " reserved" 2 " OFF" 1 " ON" 0 " Not Active" ;
VAL_ 1119 Set_AMPSpeedVolume 7 " Reserved" 6 " Reserved" 5 " Reserved" 4 " High" 3 " Middle" 2 " Low" 1 " OFF" 0 " Not Active" ;
VAL_ 1119 REQ_AMPA2BPhoneSound 7 " Reserved" 6 " Reserved" 5 " Reserved" 4 " Reserved" 2 " Tbox Sound ON" 1 " BT PhoneSound ON" 0 "Not Active" ;
